VERSION "HNNBNNNYNNNNNNNNNNNNNNNNNNNNNNNNNNNNNNNNNN/4/%%%/4/'%**4NNN///"

NS_ :

BS_:

BU_: BAP_Tester FASFrontradar ICAS1_X_Gateway MFK MFK120 MIK MRR2023 NR_1 NR_2

BO_ 333 ACC_18: 32 FASFrontradar
 SG_ ACC_18_CRC : 0|8@1+ (1,0) [0|255] ""  ICAS1_X_Gateway,MFK120
 SG_ ACC_18_BZ : 8|4@1+ (1,0) [0|15] ""  ICAS1_X_Gateway,MFK120
 SG_ ACC_DynErhoehung : 14|1@1+ (1.0,0.0) [0.0|1] ""  ICAS1_X_Gateway
 SG_ ACC_Freilaufstrategie_TSK : 15|1@1+ (1.0,0.0) [0.0|1] ""  ICAS1_X_Gateway
 SG_ ACC_zul_Regelabw_unten : 16|6@1+ (0.024,0) [0.000|1.512] "Unit_MeterPerSeconSquar"  ICAS1_X_Gateway
 SG_ ACC_Sollbeschleunigung_02 : 24|11@1+ (0.005,-7.22) [-7.220|3.005] "Unit_MeterPerSeconSquar"  ICAS1_X_Gateway
 SG_ ACC_zul_Regelabw_oben : 35|5@1+ (0.0625,0) [0.0000|1.9375] "Unit_MeterPerSeconSquar"  ICAS1_X_Gateway
 SG_ ACC_neg_Sollbeschl_Grad_02 : 40|8@1+ (0.05,0) [0.00|12.75] "Unit_MeterPerCubicSecon"  ICAS1_X_Gateway
 SG_ ACC_pos_Sollbeschl_Grad_02 : 48|8@1+ (0.05,0) [0.00|12.75] "Unit_MeterPerCubicSecon"  ICAS1_X_Gateway
 SG_ ACC_Anfahren : 56|1@1+ (1.0,0.0) [0.0|1] ""  ICAS1_X_Gateway
 SG_ ACC_Anhalten : 57|1@1+ (1.0,0.0) [0.0|1] ""  ICAS1_X_Gateway
 SG_ ACC_Typ : 58|2@1+ (1.0,0.0) [0.0|3] ""  ICAS1_X_Gateway
 SG_ ACC_Status_ACC : 60|3@1+ (1.0,0.0) [0.0|7] ""  ICAS1_X_Gateway,MFK,MFK120
 SG_ ACC_Minimale_Bremsung : 63|1@1+ (1.0,0.0) [0.0|1] ""  ICAS1_X_Gateway
 SG_ ACC_Anhalteweg : 64|11@1+ (0.01,0) [0.00|20.45] "Unit_Meter"  ICAS1_X_Gateway
 SG_ ACC_Anforderung_HMS : 77|3@1+ (1.0,0.0) [0.0|7] ""  ICAS1_X_Gateway
 SG_ ACC_Freilauf_Info : 88|2@1+ (1.0,0.0) [0.0|3] ""  ICAS1_X_Gateway
 SG_ ACC_Tempolimitassistent_Ein : 90|1@1+ (1.0,0.0) [0.0|1] ""  ICAS1_X_Gateway,MFK,MFK120
 SG_ ACC_FoD_Status : 91|2@1+ (1.0,0.0) [0.0|3] ""  ICAS1_X_Gateway,MFK
 SG_ ACC_Verkehrssinn : 94|2@1+ (1.0,0.0) [0.0|3] ""  ICAS1_X_Gateway,MFK120
 SG_ ACC_TA_Kurve_Abstand : 98|6@1+ (5,0) [0|300] "Unit_Meter"  ICAS1_X_Gateway,MFK,MFK120
 SG_ ACC_TA_Kurve_vDelta : 104|4@1+ (5,0) [0|50] "Unit_KiloMeterPerHour"  ICAS1_X_Gateway,MFK,MFK120
 SG_ RDR_VBEG_Anforderung : 108|5@1+ (1,4) [5|35] "Unit_KiloMeterPerHour"  ICAS1_X_Gateway
 SG_ ACC_Abbiegewunsch : 113|2@1+ (1.0,0.0) [0.0|3] ""  ICAS1_X_Gateway,MFK,MFK120
 SG_ ACC_Abbiegewunsch_Abstand : 115|9@1+ (1,0) [0|510] "Unit_Meter"  ICAS1_X_Gateway,MFK,MFK120
 SG_ ACC_Sollbeschleunigung_AD : 124|12@1+ (0.005,-12) [-12.000|8.465] "Unit_MeterPerSeconSquar"  ICAS1_X_Gateway
 SG_ MPPmod_1_Segment : 208|6@1+ (1,0) [2|63] ""  ICAS1_X_Gateway
 SG_ MPPmod_2_Segment : 214|6@1+ (1,0) [2|63] ""  ICAS1_X_Gateway
 SG_ MPPmod_3_Segment : 220|6@1+ (1,0) [2|63] ""  ICAS1_X_Gateway
 SG_ MPPmod_4_Segment : 226|6@1+ (1,0) [2|63] ""  ICAS1_X_Gateway
 SG_ RDR_v_ueber_Grund : 236|12@1+ (0.1,0) [0.0|409.0] "Unit_KiloMeterPerHour"  ICAS1_X_Gateway
 SG_ RDR_v_ueber_Grund_Genauigkeit : 248|6@1+ (0.1,0) [0.0|6.0] "Unit_KiloMeterPerHour"  ICAS1_X_Gateway
 SG_ RDR_v_ueber_Grund_Fahrtrichtung : 254|2@1+ (1.0,0.0) [0.0|3] ""  ICAS1_X_Gateway

BO_ 768 ACC_19: 48 FASFrontradar
 SG_ ACC_FzgStatus_Kamerafusion : 54|2@1+ (1.0,0.0) [0.0|3] ""  ICAS1_X_Gateway
 SG_ ACC_FzgStatus_Anfahrbereitschaft : 56|2@1+ (1.0,0.0) [0.0|3] ""  ICAS1_X_Gateway
 SG_ ACC_FzgStatus_Fehleranzeige : 58|3@1+ (1.0,0.0) [0.0|7] ""  ICAS1_X_Gateway
 SG_ ACC_ENG_Texte_02 : 61|3@1+ (1.0,0.0) [0.0|7] ""  ICAS1_X_Gateway
 SG_ ACC_Tempolimit : 64|5@1+ (1.0,0.0) [0.0|31] ""  ICAS1_X_Gateway
 SG_ ACC_Wunschgeschw_Farbe : 69|1@1+ (1.0,0.0) [0.0|1] ""  ICAS1_X_Gateway
 SG_ ACC_Warnung_Verkehrszeichen_1 : 70|1@1+ (1.0,0.0) [0.0|1] ""  ICAS1_X_Gateway
 SG_ ACA_Querfuehrung : 71|2@1+ (1.0,0.0) [0.0|3] ""  ICAS1_X_Gateway
 SG_ ACC_Wunschgeschw_Farbe_02 : 73|2@1+ (1.0,0.0) [0.0|3] ""  ICAS1_X_Gateway
 SG_ ACC_Regelung_AIO : 75|1@1+ (1.0,0.0) [0.0|1] ""  ICAS1_X_Gateway
 SG_ ACC_Wunschgeschw_02 : 76|10@1+ (0.32,0) [0.00|327.04] "Unit_KiloMeterPerHour"  ICAS1_X_Gateway,MFK,MFK120
 SG_ ACC_Abstandsindex_02 : 86|10@1+ (1,0) [1|1021] ""  ICAS1_X_Gateway,MFK,MFK120
 SG_ ACC_Display_Prio : 96|2@1+ (1.0,0.0) [0.0|3] ""  ICAS1_X_Gateway
 SG_ ACC_rel_Objekt_Zusatzanz : 98|2@1+ (1.0,0.0) [0.0|3] ""  ICAS1_X_Gateway
 SG_ ACC_Gesetzte_Zeitluecke : 101|3@1+ (1.0,0.0) [0.0|7] ""  ICAS1_X_Gateway
 SG_ ACC_Optischer_Fahrerhinweis : 104|1@1+ (1.0,0.0) [0.0|1] ""  ICAS1_X_Gateway
 SG_ ACC_EGO_Fahrzeug : 106|3@1+ (1.0,0.0) [0.0|7] ""  ICAS1_X_Gateway
 SG_ ACC_Relevantes_Objekt_02 : 109|2@1+ (1.0,0.0) [0.0|3] ""  ICAS1_X_Gateway
 SG_ ACC_Wunschgeschw_erreicht : 112|1@1+ (1.0,0.0) [0.0|1] ""  ICAS1_X_Gateway
 SG_ ACC_Anzeige_Zeitluecke : 113|1@1+ (1.0,0.0) [0.0|1] ""  ICAS1_X_Gateway
 SG_ ACC_Texte_Primaeranz_03 : 114|6@1+ (1.0,0.0) [0.0|63] ""  ICAS1_X_Gateway
 SG_ ACC_Texte_Zusatzanz_03 : 120|6@1+ (1.0,0.0) [0.0|63] ""  ICAS1_X_Gateway
 SG_ STA_Primaeranz : 126|2@1+ (1.0,0.0) [0.0|3] ""  ICAS1_X_Gateway
 SG_ ACC_Anzeige_Objektmarkierung : 136|4@1+ (1.0,0.0) [0.0|15] ""  ICAS1_X_Gateway
 SG_ ACC_Regelgeschw : 140|10@1+ (0.32,0) [0.00|327.04] "Unit_KiloMeterPerHour"  ICAS1_X_Gateway
 SG_ ACC_Einheit_maxSetzgeschw : 150|1@1+ (1.0,0.0) [0.0|1] ""  ICAS1_X_Gateway
 SG_ ACC_maxSetzgeschw : 151|9@1+ (1,0) [0|510] ""  ICAS1_X_Gateway
 SG_ ACC_Tempolimit_Einheit : 179|1@1+ (1.0,0.0) [0.0|1] ""  ICAS1_X_Gateway
 SG_ ACC_RUV : 184|2@1+ (1.0,0.0) [0.0|3] ""  ICAS1_X_Gateway
 SG_ ACC_Tachokranz : 186|1@1+ (1.0,0.0) [0.0|1] ""  ICAS1_X_Gateway
 SG_ ACC_Typ_Tachokranz_unten : 187|1@1+ (1.0,0.0) [0.0|1] ""  ICAS1_X_Gateway
 SG_ ACC_ENG_Texte : 188|2@1+ (1.0,0.0) [0.0|3] ""  ICAS1_X_Gateway,MFK,MFK120
 SG_ ACC_Status_GRA_Modus : 190|2@1+ (1.0,0.0) [0.0|3] ""  ICAS1_X_Gateway,MFK,MFK120
 SG_ ACA_Querfuehrung_Texte : 192|3@1+ (1.0,0.0) [0.0|7] ""  ICAS1_X_Gateway
 SG_ ACA_Hinweistexte : 195|3@1+ (1.0,0.0) [0.0|7] ""  ICAS1_X_Gateway
 SG_ ACC_FoD_Status : 198|2@1+ (1.0,0.0) [0.0|3] ""  ICAS1_X_Gateway
 SG_ ACC_Status_Anzeige : 208|3@1+ (1.0,0.0) [0.0|7] ""  ICAS1_X_Gateway
 SG_ ACC_Akustik_03 : 211|3@1+ (1.0,0.0) [0.0|7] ""  ICAS1_X_Gateway
 SG_ ACC_Texte_02 : 224|6@1+ (1.0,0.0) [0.0|63] ""  ICAS1_X_Gateway
 SG_ ACC_Status_Stauende : 231|1@1+ (1.0,0.0) [0.0|1] ""  ICAS1_X_Gateway
 SG_ STA_Texte : 232|3@1+ (1.0,0.0) [0.0|7] ""  ICAS1_X_Gateway
 SG_ AbstWarn_LRR_FAS_Fkt_Status : 235|2@1+ (1.0,0.0) [0.0|3] ""  ICAS1_X_Gateway
 SG_ STA_Zusatzanz : 237|2@1+ (1.0,0.0) [0.0|3] ""  ICAS1_X_Gateway
 SG_ FAS_Licht_Anf : 239|1@1+ (1.0,0.0) [0.0|1] ""  ICAS1_X_Gateway
 SG_ ACC_Texte_Sekundaeranz_03 : 256|5@1+ (1.0,0.0) [0.0|31] ""  ICAS1_X_Gateway
 SG_ ACC_Modus_Pop_Up : 262|3@1+ (1.0,0.0) [0.0|7] ""  ICAS1_X_Gateway
 SG_ ACC_Statusicon : 265|4@1+ (1.0,0.0) [0.0|15] ""  ICAS1_X_Gateway
 SG_ ACC_Anzeige_Objektregelung : 269|5@1+ (1.0,0.0) [0.0|31] ""  ICAS1_X_Gateway
 SG_ ACC_Anzeige_Maximalabstand : 274|7@1+ (2,0) [0|254] "Unit_Meter"  ICAS1_X_Gateway
 SG_ ACC_Typ_LNS : 281|3@1+ (1.0,0.0) [0.0|7] ""  ICAS1_X_Gateway
 SG_ ACC_Typ_RNS : 284|3@1+ (1.0,0.0) [0.0|7] ""  ICAS1_X_Gateway
 SG_ ACC_Typ_WZO : 287|3@1+ (1.0,0.0) [0.0|7] ""  ICAS1_X_Gateway
 SG_ ACC_Abstand_WZO : 290|10@1+ (0.2,0) [0.2|204.6] "Unit_Meter"  ICAS1_X_Gateway
 SG_ ACC_Abstand_RNS : 300|10@1+ (0.2,0) [0.2|204.6] "Unit_Meter"  ICAS1_X_Gateway
 SG_ ACC_Abstand_LNS : 310|10@1+ (0.2,0) [0.2|204.6] "Unit_Meter"  ICAS1_X_Gateway
 SG_ ACC_Texte_03 : 320|7@1+ (1.0,0.0) [0.0|127] ""  ICAS1_X_Gateway,MFK120
 SG_ ACC_iBoost_Anzeige : 327|2@1+ (1.0,0.0) [0.0|3] ""  ICAS1_X_Gateway
 SG_ ACC_Texte_Sekundaeranz_02 : 329|5@1+ (1.0,0.0) [0.0|31] ""  ICAS1_X_Gateway
 SG_ ACC_Sollabstand_1 : 334|10@1+ (0.2,0) [0.2|204.6] "Unit_Meter"  ICAS1_X_Gateway
 SG_ ACC_Sollabstand_2 : 344|10@1+ (0.2,0) [0.2|204.6] "Unit_Meter"  ICAS1_X_Gateway
 SG_ ACC_Sollabstand_3 : 354|10@1+ (0.2,0) [0.2|204.6] "Unit_Meter"  ICAS1_X_Gateway
 SG_ ACC_Sollabstand_4 : 364|10@1+ (0.2,0) [0.2|204.6] "Unit_Meter"  ICAS1_X_Gateway
 SG_ ACC_Sollabstand_5 : 374|10@1+ (0.2,0) [0.2|204.6] "Unit_Meter"  ICAS1_X_Gateway

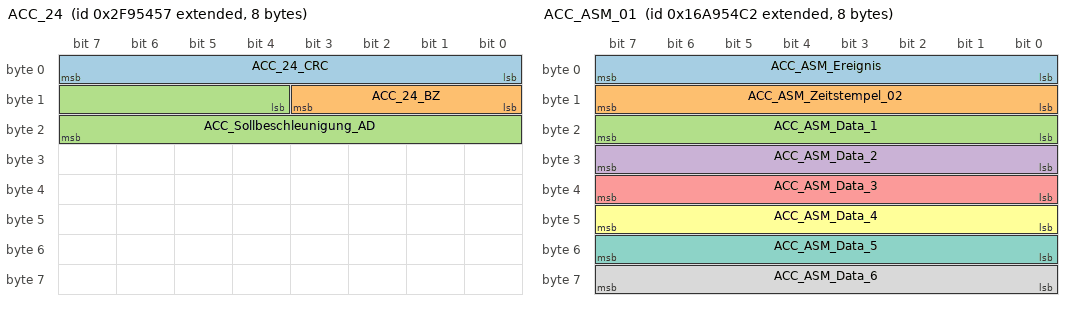
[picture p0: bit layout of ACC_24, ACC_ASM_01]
BO_ 2197378135 ACC_24: 8 Vector__XXX
 SG_ ACC_24_CRC : 0|8@1+ (1,0) [0|255] ""  ICAS1_X_Gateway
 SG_ ACC_24_BZ : 8|4@1+ (1,0) [0|15] ""  ICAS1_X_Gateway
 SG_ ACC_Sollbeschleunigung_AD : 12|12@1+ (0.005,-12) [-12.000|8.465] "Unit_MeterPerSeconSquar"  ICAS1_X_Gateway

BO_ 2527679682 ACC_ASM_01: 8 FASFrontradar
 SG_ ACC_ASM_Ereignis : 0|8@1+ (1,0) [1|254] ""  ICAS1_X_Gateway
 SG_ ACC_ASM_Zeitstempel_02 : 8|8@1+ (0.04,0) [0.00|10.16] "Unit_Secon"  ICAS1_X_Gateway
 SG_ ACC_ASM_Data_1 : 16|8@1+ (1,0) [0|255] ""  ICAS1_X_Gateway
 SG_ ACC_ASM_Data_2 : 24|8@1+ (1,0) [0|255] ""  ICAS1_X_Gateway
 SG_ ACC_ASM_Data_3 : 32|8@1+ (1,0) [0|255] ""  ICAS1_X_Gateway
 SG_ ACC_ASM_Data_4 : 40|8@1+ (1,0) [0|255] ""  ICAS1_X_Gateway
 SG_ ACC_ASM_Data_5 : 48|8@1+ (1,0) [0|255] ""  ICAS1_X_Gateway
 SG_ ACC_ASM_Data_6 : 56|8@1+ (1,0) [0|255] ""  ICAS1_X_Gateway

BO_ 64 Airbag_01: 8 ICAS1_X_Gateway
 SG_ Airbag_01_CRC : 0|8@1+ (1,0) [0|255] ""  FASFrontradar,MFK120,MRR2023
 SG_ Airbag_01_BZ : 8|4@1+ (1,0) [0|15] ""  FASFrontradar,MFK120,MRR2023
 SG_ AB_RGS_Anst : 12|4@1+ (1.0,0.0) [0.0|15] ""  Vector__XXX
 SG_ AB_Front_Crash : 16|1@1+ (1.0,0.0) [0.0|1] ""  MFK,MFK120
 SG_ AB_Heck_Crash : 17|1@1+ (1.0,0.0) [0.0|1] ""  MFK,MFK120
 SG_ AB_SF_Crash : 18|1@1+ (1.0,0.0) [0.0|1] ""  MFK,MFK120
 SG_ AB_SB_Crash : 19|1@1+ (1.0,0.0) [0.0|1] ""  MFK,MFK120
 SG_ AB_Rollover_Crash : 20|1@1+ (1.0,0.0) [0.0|1] ""  MFK,MFK120
 SG_ AB_Crash_Int : 21|3@1+ (1.0,0.0) [0.0|7] ""  FASFrontradar,MFK120,MRR2023
 SG_ AB_Lampe : 24|1@1+ (1.0,0.0) [0.0|1] ""  Vector__XXX
 SG_ AB_Deaktiviert : 25|1@1+ (1.0,0.0) [0.0|1] ""  Vector__XXX
 SG_ AB_VB_deaktiviert : 26|1@1+ (1.0,0.0) [0.0|1] ""  Vector__XXX
 SG_ AB_Systemfehler : 27|1@1+ (1.0,0.0) [0.0|1] ""  MFK,MFK120
 SG_ AB_Diagnose : 28|1@1+ (1.0,0.0) [0.0|1] ""  Vector__XXX
 SG_ AB_Stellgliedtest : 29|1@1+ (1.0,0.0) [0.0|1] ""  Vector__XXX
 SG_ AB_Erh_Auf_VB : 30|2@1+ (1.0,0.0) [0.0|3] ""  Vector__XXX
 SG_ AB_Gurtwarn_VF : 32|1@1+ (1.0,0.0) [0.0|1] ""  MFK
 SG_ AB_Gurtwarn_VB : 33|1@1+ (1.0,0.0) [0.0|1] ""  MFK
 SG_ AB_Anzeige_Fussg : 34|2@1+ (1.0,0.0) [0.0|3] ""  Vector__XXX
 SG_ AB_Texte_AKS : 36|2@1+ (1.0,0.0) [0.0|3] ""  Vector__XXX
 SG_ AB_PAO_Leuchte_Anf : 38|1@1+ (1.0,0.0) [0.0|1] ""  Vector__XXX
 SG_ AB_MKB_gueltig : 39|1@1+ (1.0,0.0) [0.0|1] ""  Vector__XXX
 SG_ AB_MKB_Anforderung : 40|1@1+ (1.0,0.0) [0.0|1] ""  Vector__XXX
 SG_ AB_Versorgungsspannung : 41|1@1+ (1.0,0.0) [0.0|1] ""  Vector__XXX
 SG_ AB_Deaktivierung_HV : 42|3@1+ (1.0,0.0) [0.0|7] ""  Vector__XXX
 SG_ AB_EDR_Trigger : 45|2@1+ (1.0,0.0) [0.0|3] ""  MFK120
 SG_ AB_Belegung_VF : 47|2@1+ (1.0,0.0) [0.0|3] ""  FASFrontradar,MRR2023
 SG_ AB_Gurtschloss_FA_ext : 49|3@1+ (1.0,0.0) [0.0|7] ""  MRR2023
 SG_ AB_Gurtschloss_FA_ext_aktiv : 52|1@1+ (1.0,0.0) [0.0|1] ""  MRR2023
 SG_ AB_eCS_Error : 53|1@1+ (1.0,0.0) [0.0|1] ""  Vector__XXX
 SG_ ASM_Masterzeit_02 : 56|8@1+ (0.04,0) [0.00|10.16] "Unit_Secon"  FASFrontradar,MFK,MFK120,MRR2023

BO_ 1312 Airbag_02: 8 ICAS1_X_Gateway
 SG_ Airbag_02_CRC : 0|8@1+ (1,0) [0|255] ""  FASFrontradar,MRR2023
 SG_ Airbag_02_BZ : 8|4@1+ (1,0) [0|15] ""  FASFrontradar,MRR2023
 SG_ LoGeWa_Event_Kombiwarnung : 12|4@1+ (1.0,0.0) [0.0|15] ""  Vector__XXX
 SG_ AB_Anforderung_eCall : 16|1@1+ (1.0,0.0) [0.0|1] ""  Vector__XXX
 SG_ AB_Anprall_Seite_Beifahrer : 17|1@1+ (1.0,0.0) [0.0|1] ""  MRR2023
 SG_ AB_Anprall_FGS : 19|1@1+ (1.0,0.0) [0.0|1] ""  MRR2023
 SG_ AB_Anprall_Front_Beifahrer : 20|1@1+ (1.0,0.0) [0.0|1] ""  MRR2023
 SG_ AB_Anprall_Front_Fahrer : 21|1@1+ (1.0,0.0) [0.0|1] ""  MRR2023
 SG_ AB_Wickelklappung_Reihe2_MI : 24|2@1+ (1.0,0.0) [0.0|3] ""  Vector__XXX
 SG_ AB_Belegung_VB : 26|2@1+ (1.0,0.0) [0.0|3] ""  Vector__XXX
 SG_ AB_Abschaltanf_SIH_BF : 28|1@1+ (1.0,0.0) [0.0|1] ""  Vector__XXX
 SG_ AB_Anprall_Seite_Fahrer : 29|1@1+ (1.0,0.0) [0.0|1] ""  MRR2023
 SG_ SC_PAO_Schriftzug_Anf : 30|2@1+ (1.0,0.0) [0.0|3] ""  Vector__XXX
 SG_ SC_PAO_ON_Anf : 32|2@1+ (1.0,0.0) [0.0|3] ""  Vector__XXX
 SG_ SC_PAO_OFF_Anf : 34|2@1+ (1.0,0.0) [0.0|3] ""  Vector__XXX
 SG_ AB_Crashschwere : 36|3@1+ (1.0,0.0) [0.0|7] ""  Vector__XXX
 SG_ AB_Anforderung_USM : 39|1@1+ (1.0,0.0) [0.0|1] ""  Vector__XXX
 SG_ AB_Gurtschloss_FA : 40|2@1+ (1.0,0.0) [0.0|3] ""  MFK,MFK120,MRR2023
 SG_ AB_Gurtschloss_BF : 42|2@1+ (1.0,0.0) [0.0|3] ""  MFK,MFK120
 SG_ AB_Gurtschloss_Reihe2_FA : 44|2@1+ (1.0,0.0) [0.0|3] ""  MFK,MFK120
 SG_ AB_Gurtschloss_Reihe2_MI : 46|2@1+ (1.0,0.0) [0.0|3] ""  MFK,MFK120
 SG_ AB_Gurtschloss_Reihe2_BF : 48|2@1+ (1.0,0.0) [0.0|3] ""  MFK,MFK120
 SG_ AB_Gurtschloss_Reihe3_FA : 50|2@1+ (1.0,0.0) [0.0|3] ""  MFK,MFK120
 SG_ AB_Gurtschloss_Reihe3_MI : 52|2@1+ (1.0,0.0) [0.0|3] ""  MFK,MFK120
 SG_ AB_Gurtschloss_Reihe3_BF : 54|2@1+ (1.0,0.0) [0.0|3] ""  MFK,MFK120
 SG_ AB_Sitzpos_Sens_FA : 56|2@1+ (1.0,0.0) [0.0|3] ""  Vector__XXX
 SG_ AB_Sitzpos_Sens_BF : 58|2@1+ (1.0,0.0) [0.0|3] ""  Vector__XXX
 SG_ AB_Wickelklappung_Reihe2_BF : 60|2@1+ (1.0,0.0) [0.0|3] ""  Vector__XXX
 SG_ AB_Wickelklappung_Reihe2_FA : 62|2@1+ (1.0,0.0) [0.0|3] ""  Vector__XXX

BO_ 1349 Airbag_04: 8 ICAS1_X_Gateway
 SG_ Airbag_04_CRC : 0|8@1+ (1,0) [0|255] ""  FASFrontradar,MRR2023
 SG_ Airbag_04_BZ : 8|4@1+ (1,0) [0|15] ""  FASFrontradar,MRR2023
 SG_ AB_Anprall_Heck : 13|1@1+ (1.0,0.0) [0.0|1] ""  Vector__XXX
 SG_ AB_Gurtwarn_Reihe4_FA : 14|2@1+ (1.0,0.0) [0.0|3] ""  Vector__XXX
 SG_ AB_Gurtwarn_Reihe4_BF : 16|2@1+ (1.0,0.0) [0.0|3] ""  Vector__XXX
 SG_ AB_Gurtwarn_Reihe4_MI : 18|2@1+ (1.0,0.0) [0.0|3] ""  Vector__XXX
 SG_ AB_Gurtwarn_Reihe2_FA : 20|2@1+ (1.0,0.0) [0.0|3] ""  MFK
 SG_ AB_Gurtwarn_Reihe2_BF : 22|2@1+ (1.0,0.0) [0.0|3] ""  MFK
 SG_ AbstWarn_MV_FAS_Fkt_Status : 24|2@1+ (1.0,0.0) [0.0|3] ""  Vector__XXX
 SG_ WarnBrems_Charisma_Status : 26|2@1+ (1.0,0.0) [0.0|3] ""  Vector__XXX
 SG_ WarnBrems_Charisma_FahrPr : 28|4@1+ (1.0,0.0) [0.0|15] ""  Vector__XXX
 SG_ AB_Gurtwarn_Reihe2_MI : 32|2@1+ (1.0,0.0) [0.0|3] ""  MFK
 SG_ AB_Gurtwarn_Reihe3_FA : 34|2@1+ (1.0,0.0) [0.0|3] ""  MFK
 SG_ AB_Gurtwarn_Reihe3_MI : 36|2@1+ (1.0,0.0) [0.0|3] ""  MFK
 SG_ AB_Gurtwarn_Reihe3_BF : 38|2@1+ (1.0,0.0) [0.0|3] ""  MFK
 SG_ LGI_FAS_Fkt_Status : 40|2@1+ (1.0,0.0) [0.0|3] ""  Vector__XXX
 SG_ PreCrash_FAS_Fkt_Status : 42|3@1+ (1.0,0.0) [0.0|7] ""  Vector__XXX
 SG_ AB_Belegung_VF_ext : 45|3@1+ (1.0,0.0) [0.0|7] ""  MIK,MRR2023
 SG_ AB_SBR_hinten_verbau : 48|2@1+ (1.0,0.0) [0.0|3] ""  Vector__XXX
 SG_ AB_Belegung_VF_ext_aktiv : 50|1@1+ (1.0,0.0) [0.0|1] ""  Vector__XXX
 SG_ AWV_Einstellung_System_ASG : 51|1@1+ (1.0,0.0) [0.0|1] ""  Vector__XXX
 SG_ AWV_Einstellung_Warnung_ASG : 52|3@1+ (1.0,0.0) [0.0|7] ""  Vector__XXX
 SG_ SC_PreSense_Modus_Warnung_NV : 55|3@1+ (1.0,0.0) [0.0|7] ""  Vector__XXX
 SG_ SC_PreSense_Modus_Warnung_MV : 58|3@1+ (1.0,0.0) [0.0|7] ""  Vector__XXX
 SG_ SC_PreSense_Modus_System_MV : 61|1@1+ (1.0,0.0) [0.0|1] ""  Vector__XXX
 SG_ SC_PreSense_Modus_System_NV : 62|1@1+ (1.0,0.0) [0.0|1] ""  Vector__XXX
 SG_ SC_PreSense_Modus_System_KAS : 63|1@1+ (1.0,0.0) [0.0|1] ""  Vector__XXX

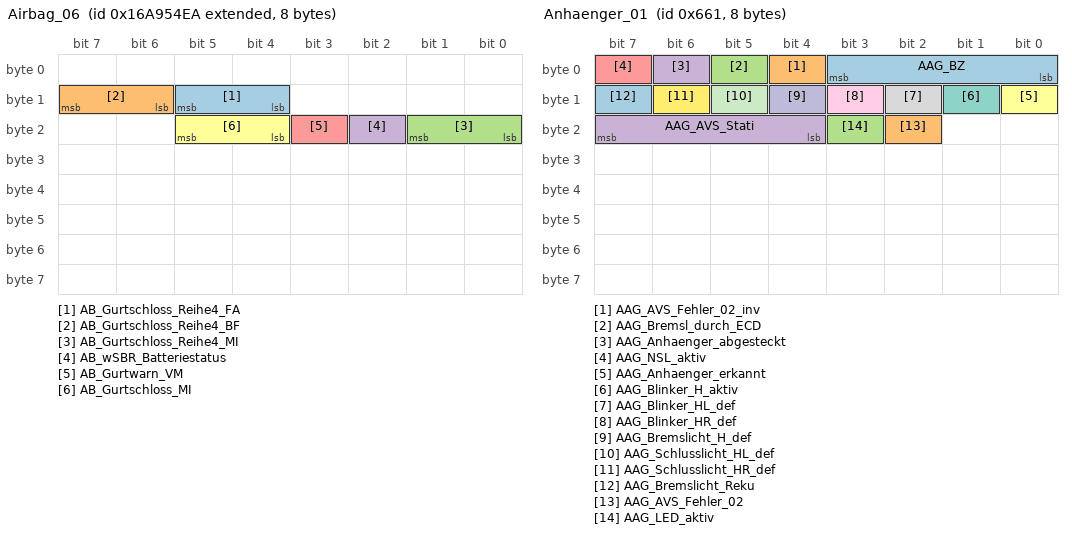
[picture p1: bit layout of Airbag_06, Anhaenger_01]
BO_ 2527679722 Airbag_06: 8 ICAS1_X_Gateway
 SG_ AB_Gurtschloss_Reihe4_FA : 12|2@1+ (1.0,0.0) [0.0|3] ""  Vector__XXX
 SG_ AB_Gurtschloss_Reihe4_BF : 14|2@1+ (1.0,0.0) [0.0|3] ""  Vector__XXX
 SG_ AB_Gurtschloss_Reihe4_MI : 16|2@1+ (1.0,0.0) [0.0|3] ""  Vector__XXX
 SG_ AB_wSBR_Batteriestatus : 18|1@1+ (1.0,0.0) [0.0|1] ""  Vector__XXX
 SG_ AB_Gurtwarn_VM : 19|1@1+ (1.0,0.0) [0.0|1] ""  MFK
 SG_ AB_Gurtschloss_MI : 20|2@1+ (1.0,0.0) [0.0|3] ""  Vector__XXX

BO_ 1633 Anhaenger_01: 8 ICAS1_X_Gateway
 SG_ AAG_BZ : 0|4@1+ (1,0) [0|15] ""  Vector__XXX
 SG_ AAG_AVS_Fehler_02_inv : 4|1@1+ (1.0,0.0) [0.0|1] ""  Vector__XXX
 SG_ AAG_Bremsl_durch_ECD : 5|1@1+ (1.0,0.0) [0.0|1] ""  Vector__XXX
 SG_ AAG_Anhaenger_abgesteckt : 6|1@1+ (1.0,0.0) [0.0|1] ""  Vector__XXX
 SG_ AAG_NSL_aktiv : 7|1@1+ (1.0,0.0) [0.0|1] ""  Vector__XXX
 SG_ AAG_Anhaenger_erkannt : 8|1@1+ (1.0,0.0) [0.0|1] ""  MFK,MFK120,MRR2023
 SG_ AAG_Blinker_H_aktiv : 9|1@1+ (1.0,0.0) [0.0|1] ""  Vector__XXX
 SG_ AAG_Blinker_HL_def : 10|1@1+ (1.0,0.0) [0.0|1] ""  Vector__XXX
 SG_ AAG_Blinker_HR_def : 11|1@1+ (1.0,0.0) [0.0|1] ""  Vector__XXX
 SG_ AAG_Bremslicht_H_def : 12|1@1+ (1.0,0.0) [0.0|1] ""  MRR2023
 SG_ AAG_Schlusslicht_HL_def : 13|1@1+ (1.0,0.0) [0.0|1] ""  Vector__XXX
 SG_ AAG_Schlusslicht_HR_def : 14|1@1+ (1.0,0.0) [0.0|1] ""  Vector__XXX
 SG_ AAG_Bremslicht_Reku : 15|1@1+ (1.0,0.0) [0.0|1] ""  Vector__XXX
 SG_ AAG_AVS_Fehler_02 : 18|1@1+ (1.0,0.0) [0.0|1] ""  Vector__XXX
 SG_ AAG_LED_aktiv : 19|1@1+ (1.0,0.0) [0.0|1] ""  Vector__XXX
 SG_ AAG_AVS_Stati : 20|4@1+ (1.0,0.0) [0.0|15] ""  Vector__XXX

BO_ 616 APS_04: 32 ICAS1_X_Gateway
 SG_ US_Fehler_HLS : 12|1@1+ (1.0,0.0) [0.0|1] ""  MFK
 SG_ US_Fehler_HRS : 13|1@1+ (1.0,0.0) [0.0|1] ""  MFK
 SG_ US_Fehler_VLS : 14|1@1+ (1.0,0.0) [0.0|1] ""  MFK
 SG_ US_Fehler_VRS : 15|1@1+ (1.0,0.0) [0.0|1] ""  MFK
 SG_ US_Links_01_Pos_X : 16|10@1+ (0.016,-8.176) [-8.176|8.176] "Unit_Meter"  MFK
 SG_ US_Links_01_Pos_Y : 26|9@1+ (0.016,0) [0.000|8.160] "Unit_Meter"  MFK
 SG_ US_Links_01_Valid : 35|1@1+ (1.0,0.0) [0.0|1] ""  MFK
 SG_ US_Links_02_Pos_X : 36|10@1+ (0.016,-8.176) [-8.176|8.176] "Unit_Meter"  MFK
 SG_ US_Links_02_Pos_Y : 46|9@1+ (0.016,0) [0.000|8.160] "Unit_Meter"  MFK
 SG_ US_Links_02_Valid : 55|1@1+ (1.0,0.0) [0.0|1] ""  MFK
 SG_ US_Rechts_01_Pos_X : 56|10@1+ (0.016,-8.176) [-8.176|8.176] "Unit_Meter"  MFK
 SG_ US_Rechts_01_Pos_Y : 66|9@1+ (0.016,-8.16) [-8.160|0.000] "Unit_Meter"  MFK
 SG_ US_Rechts_01_Valid : 75|1@1+ (1.0,0.0) [0.0|1] ""  MFK
 SG_ US_Rechts_02_Pos_X : 76|10@1+ (0.016,-8.176) [-8.176|8.176] "Unit_Meter"  MFK
 SG_ US_Rechts_02_Pos_Y : 86|9@1+ (0.016,-8.16) [-8.160|0.000] "Unit_Meter"  MFK
 SG_ US_Rechts_02_Valid : 95|1@1+ (1.0,0.0) [0.0|1] ""  MFK
 SG_ US_QAbstand_HLS : 96|9@1+ (0.016,0) [0.000|8.160] "Unit_Meter"  MFK,MFK120
 SG_ US_Nichtverfuegbarkeit_HLS : 105|1@1+ (1.0,0.0) [0.0|1] ""  MFK
 SG_ US_QAbstand_HRS : 106|9@1+ (0.016,0) [0.000|8.160] "Unit_Meter"  MFK,MFK120
 SG_ US_Nichtverfuegbarkeit_HRS : 115|1@1+ (1.0,0.0) [0.0|1] ""  MFK
 SG_ US_QAbstand_VLS : 116|9@1+ (0.016,0) [0.000|8.160] "Unit_Meter"  MFK,MFK120
 SG_ US_Nichtverfuegbarkeit_VLS : 125|1@1+ (1.0,0.0) [0.0|1] ""  MFK
 SG_ US_QAbstand_VRS : 126|9@1+ (0.016,0) [0.000|8.160] "Unit_Meter"  MFK,MFK120
 SG_ US_Nichtverfuegbarkeit_VRS : 135|1@1+ (1.0,0.0) [0.0|1] ""  MFK
 SG_ US_Datenalter_HLS : 192|16@1+ (0.1,0) [0.0|6553.5] "Unit_MilliSecon"  MFK
 SG_ US_Datenalter_HRS : 208|16@1+ (0.1,0) [0.0|6553.5] "Unit_MilliSecon"  MFK
 SG_ US_Datenalter_VLS : 224|16@1+ (0.1,0) [0.0|6553.5] "Unit_MilliSecon"  MFK
 SG_ US_Datenalter_VRS : 240|16@1+ (0.1,0) [0.0|6553.5] "Unit_MilliSecon"  MFK

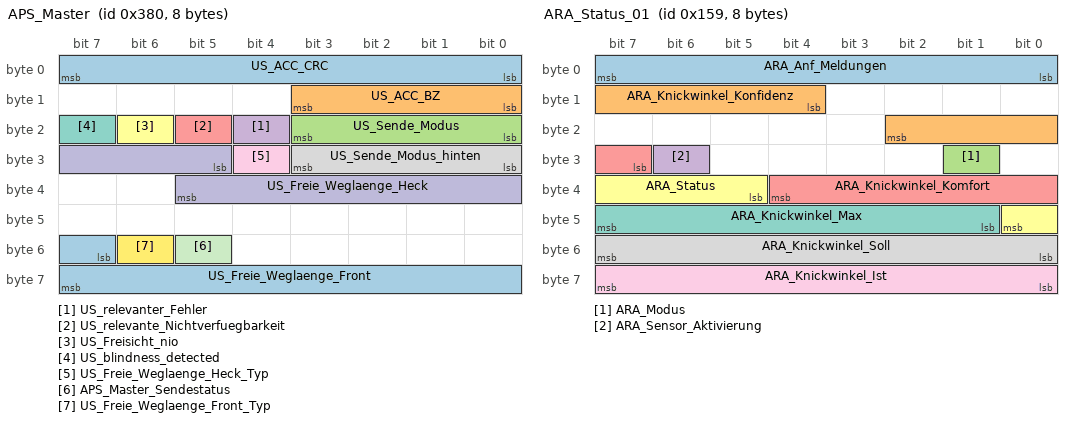
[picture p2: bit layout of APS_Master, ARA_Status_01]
BO_ 896 APS_Master: 8 ICAS1_X_Gateway
 SG_ US_ACC_CRC : 0|8@1+ (1,0) [0|255] ""  Vector__XXX
 SG_ US_ACC_BZ : 8|4@1+ (1,0) [0|15] ""  Vector__XXX
 SG_ US_Sende_Modus : 16|4@1+ (1.0,0.0) [0.0|15] ""  FASFrontradar,MRR2023
 SG_ US_relevanter_Fehler : 20|1@1+ (1.0,0.0) [0.0|1] ""  FASFrontradar,MRR2023
 SG_ US_relevante_Nichtverfuegbarkeit : 21|1@1+ (1.0,0.0) [0.0|1] ""  FASFrontradar,MRR2023
 SG_ US_Freisicht_nio : 22|1@1+ (1.0,0.0) [0.0|1] ""  FASFrontradar,MRR2023
 SG_ US_blindness_detected : 23|1@1+ (1.0,0.0) [0.0|1] ""  FASFrontradar,MRR2023
 SG_ US_Sende_Modus_hinten : 24|4@1+ (1.0,0.0) [0.0|15] ""  Vector__XXX
 SG_ US_Freie_Weglaenge_Heck_Typ : 28|1@1+ (1.0,0.0) [0.0|1] ""  Vector__XXX
 SG_ US_Freie_Weglaenge_Heck : 29|9@1+ (0.01,0) [0.00|5.00] "Unit_Meter"  Vector__XXX
 SG_ APS_Master_Sendestatus : 53|1@1+ (1.0,0.0) [0.0|1] ""  Vector__XXX
 SG_ US_Freie_Weglaenge_Front_Typ : 54|1@1+ (1.0,0.0) [0.0|1] ""  FASFrontradar,MRR2023
 SG_ US_Freie_Weglaenge_Front : 55|9@1+ (0.01,0) [0.00|5.00] "Unit_Meter"  FASFrontradar,MRR2023

BO_ 345 ARA_Status_01: 8 ICAS1_X_Gateway
 SG_ ARA_Anf_Meldungen : 0|8@1+ (1.0,0.0) [0.0|255] ""  Vector__XXX
 SG_ ARA_Knickwinkel_Konfidenz : 12|7@1+ (1,0) [0|120] "Unit_DegreOfArc"  Vector__XXX
 SG_ ARA_Modus : 25|1@1+ (1.0,0.0) [0.0|1] ""  Vector__XXX
 SG_ ARA_Sensor_Aktivierung : 30|1@1+ (1.0,0.0) [0.0|1] ""  Vector__XXX
 SG_ ARA_Knickwinkel_Komfort : 31|6@1+ (1,0) [0|60] "Unit_DegreOfArc"  Vector__XXX
 SG_ ARA_Status : 37|4@1+ (1.0,0.0) [0.0|15] ""  MRR2023
 SG_ ARA_Knickwinkel_Max : 41|7@1+ (1,0) [0|120] "Unit_DegreOfArc"  Vector__XXX
 SG_ ARA_Knickwinkel_Soll : 48|8@1+ (1,-125) [-125|126] "Unit_DegreOfArc"  Vector__XXX
 SG_ ARA_Knickwinkel_Ist : 56|8@1+ (1,-125) [-125|126] "Unit_DegreOfArc"  Vector__XXX

BO_ 2527679661 AWV_02: 8 FASFrontradar
 SG_ WBA_Warnblinken : 0|2@1+ (1.0,0.0) [0.0|3] ""  ICAS1_X_Gateway,MFK120
 SG_ AWV_KA_Konfiguration : 2|1@1+ (1.0,0.0) [0.0|1] ""  ICAS1_X_Gateway
 SG_ AWV_Warnung : 12|3@1+ (1.0,0.0) [0.0|7] ""  ICAS1_X_Gateway,MFK,MFK120
 SG_ AWV_Texte : 15|3@1+ (1.0,0.0) [0.0|7] ""  ICAS1_X_Gateway
 SG_ AWV_Warnlevel : 18|6@1+ (1.0,0.0) [0.0|63] ""  ICAS1_X_Gateway,MFK
 SG_ AWV_Einstellung_System_FSG : 24|1@1+ (1.0,0.0) [0.0|1] ""  ICAS1_X_Gateway
 SG_ AWV_Einstellung_Warnung_FSG : 25|3@1+ (1.0,0.0) [0.0|7] ""  ICAS1_X_Gateway
 SG_ AWV_Status_Anzeige : 28|2@1+ (1.0,0.0) [0.0|3] ""  ICAS1_X_Gateway
 SG_ AWV_LED_Leiste : 30|2@1+ (1.0,0.0) [0.0|3] ""  ICAS1_X_Gateway
 SG_ AWV_Priowarnung : 32|1@1+ (1.0,0.0) [0.0|1] ""  ICAS1_X_Gateway
 SG_ AWV_AW_Abstand : 33|9@1+ (1,0) [0|508] "Unit_Meter"  ICAS1_X_Gateway
 SG_ AWV_AW_Zeitluecke : 42|3@1+ (1.0,0.0) [0.0|7] ""  ICAS1_X_Gateway
 SG_ AWV_AW_Texte : 45|3@1+ (1.0,0.0) [0.0|7] ""  ICAS1_X_Gateway
 SG_ AWV_AW_Texte_Zusatzanzeige : 48|4@1+ (1.0,0.0) [0.0|15] ""  ICAS1_X_Gateway
 SG_ AWV_KA_ObjektFront : 52|1@1+ (1.0,0.0) [0.0|1] ""  ICAS1_X_Gateway
 SG_ AWV_Warnung_Richtung : 53|3@1+ (1.0,0.0) [0.0|7] ""  ICAS1_X_Gateway
 SG_ AWV_Kamera_Objekt_ID : 56|8@1+ (1,0) [1|255] "Unit_None"  ICAS1_X_Gateway

BO_ 219 AWV_03: 48 FASFrontradar
 SG_ AWV_03_CRC : 0|8@1+ (1,0) [0|255] ""  ICAS1_X_Gateway
 SG_ AWV_03_BZ : 8|4@1+ (1,0) [0|15] ""  ICAS1_X_Gateway
 SG_ PCF_Freigabe : 12|1@1+ (1.0,0.0) [0.0|1] ""  ICAS1_X_Gateway
 SG_ SDF_PSF_Objektstatus : 13|3@1+ (1.0,0.0) [0.0|7] ""  ICAS1_X_Gateway
 SG_ SDF_PSF_CU_Status : 16|1@1+ (1.0,0.0) [0.0|1] ""  ICAS1_X_Gateway
 SG_ SDF_PSF_CW : 17|7@1+ (1,0) [0|100] ""  ICAS1_X_Gateway
 SG_ SDF_PSF_Fahrer_aktiv : 24|1@1+ (1.0,0.0) [0.0|1] ""  ICAS1_X_Gateway
 SG_ SDF_PSF_Guete : 25|2@1+ (1.0,0.0) [0.0|3] ""  ICAS1_X_Gateway
 SG_ SDF_PSF_Kollisionsueberdeckung : 27|5@1+ (0.1,0) [0.1|2.8] "Unit_Meter"  ICAS1_X_Gateway
 SG_ SDF_PSF_Time_To_Collision : 32|8@1+ (0.01,0) [0.00|2.50] "Unit_Secon"  ICAS1_X_Gateway
 SG_ SDF_PSF_v_rel : 40|8@1+ (0.4,0) [0.4|101.2] "Unit_MeterPerSecon"  ICAS1_X_Gateway
 SG_ AWV_Eingriff_Sendeart : 64|1@1+ (1.0,0.0) [0.0|1] ""  ICAS1_X_Gateway
 SG_ AWV_Verz_Freigabe : 65|1@1+ (1.0,0.0) [0.0|1] ""  ICAS1_X_Gateway
 SG_ AWV_Verz_Anf : 66|10@1+ (0.024,-20.016) [-20.016|4.512] "Unit_MeterPerSeconSquar"  ICAS1_X_Gateway
 SG_ AWV_Anf_Prefill : 76|1@1+ (1.0,0.0) [0.0|1] ""  ICAS1_X_Gateway
 SG_ AWV_Ruckprofil : 77|3@1+ (1.0,0.0) [0.0|7] ""  ICAS1_X_Gateway
 SG_ AWV_Time_to_collision : 80|8@1+ (0.01,0) [0.00|2.50] "Unit_Secon"  ICAS1_X_Gateway
 SG_ AWV_HBA_Param : 88|2@1+ (1.0,0.0) [0.0|3] ""  ICAS1_X_Gateway
 SG_ AWV_Verz_Anf_ASIL : 90|3@1+ (1.0,0.0) [0.0|7] ""  ICAS1_X_Gateway
 SG_ AWV_Time_to_brake : 93|7@1+ (10,0) [0|1240] "Unit_MilliSecon"  ICAS1_X_Gateway
 SG_ AWV_Zielobjekttyp : 100|4@1+ (1.0,0.0) [0.0|15] ""  ICAS1_X_Gateway
 SG_ AWV_QFK_KruemmSoll : 104|15@1+ (0.0000067,0) [0E-7|0.2195389] "Unit_MeterInver"  ICAS1_X_Gateway
 SG_ AWV_QFK_KruemmSoll_VZ : 119|1@1+ (1.0,0.0) [0.0|1] ""  ICAS1_X_Gateway
 SG_ AWV_QFK_Spuerb : 120|8@1+ (0.4,0) [0.0|100.0] "Unit_PerCent"  ICAS1_X_Gateway
 SG_ AWV_QFK_AnfStat : 128|4@1+ (1.0,0.0) [0.0|15] ""  ICAS1_X_Gateway
 SG_ AWV_QFK_Signal1 : 132|10@1+ (1,0) [0|1023] ""  ICAS1_X_Gateway
 SG_ AWV_QFK_Art1 : 142|3@1+ (1,0) [0|7] ""  ICAS1_X_Gateway
 SG_ AWV_QFK_Art2 : 145|3@1+ (1,0) [0|7] ""  ICAS1_X_Gateway
 SG_ AWV_QFK_Signal2 : 148|10@1+ (1,0) [0|1023] ""  ICAS1_X_Gateway
 SG_ AWV_Fahrerbremswunsch_erf : 158|1@1+ (1.0,0.0) [0.0|1] ""  ICAS1_X_Gateway
 SG_ AWV_Timestamp_TTC : 161|13@1+ (0.001,0) [0.000|8.190] "Unit_Secon"  ICAS1_X_Gateway
 SG_ AWV_QFK_KrSoll_VZ : 175|1@1+ (1.0,0.0) [0.0|1] ""  ICAS1_X_Gateway
 SG_ AWV_QFK_KrSoll : 176|16@1+ (0.0000067,0) [0E-7|0.4390778] "Unit_MeterInver"  ICAS1_X_Gateway
 SG_ AWV_Status_AWU : 192|4@1+ (1.0,0.0) [0.0|15] ""  ICAS1_X_Gateway
 SG_ SOK_AWV_03_Signatur : 336|48@1+ (1,0) [0|281474976710655] "Unit_None"  ICAS1_X_Gateway

BO_ 2536767264 BAP_Debug_Cmd: 8 BAP_Tester
 SG_ BAP_Debug_Cmd : 0|16@1+ (1.0,0.0) [0.0|65535] ""  FASFrontradar,MFK,MFK120,MRR2023

BO_ 2536767280 BAP_Debug_Data: 8 FASFrontradar
 SG_ BAP_Debug_Data : 0|64@1+ (1.0,0.0) [0.0|18446744073709551615] ""  BAP_Tester

BO_ 2536728320 BAP_REM2_ASG_01: 8 ICAS1_X_Gateway
 SG_ BAP_REM2_ASG_01_Header : 0|64@1+ (1.0,0.0) [0.0|18446744073709551615] ""  FASFrontradar,MRR2023

BO_ 2536728336 BAP_REM2_FSG_01: 8 FASFrontradar
 SG_ BAP_REM2_FSG_01_Header : 0|64@1+ (1.0,0.0) [0.0|18446744073709551615] ""  ICAS1_X_Gateway

BO_ 2536728337 BAP_REM2_FSG_02: 8 FASFrontradar
 SG_ BAP_REM2_FSG_02_Header : 0|64@1+ (1.0,0.0) [0.0|18446744073709551615] ""  ICAS1_X_Gateway

BO_ 2536725248 BAP_REM_ASG_01: 8 ICAS1_X_Gateway
 SG_ BAP_REM_ASG_01_Header : 0|8@1+ (1,0) [0|255] "Unit_None"  MFK

BO_ 2536725249 BAP_REM_ASG_02: 64 ICAS1_X_Gateway
 SG_ BAP_REM_ASG_02_Header : 0|512@1+ (1.0,0.0) [0.0|13407807929942597099574024998205846127479365820592393377723561443721764030073546976801874298166903427690031858186486050853753882811946569946433649006084095] ""  MFK

BO_ 2536725264 BAP_REM_FSG_01: 8 MFK
 SG_ BAP_REM_FSG_01_Header : 0|8@1+ (1,0) [0|255] "Unit_None"  ICAS1_X_Gateway

BO_ 2536725265 BAP_REM_FSG_02: 8 MFK
 SG_ BAP_REM_FSG_02_Header : 0|8@1+ (1,0) [0|255] "Unit_None"  ICAS1_X_Gateway

BO_ 2536726273 BAP_TPA_ASG_02: 8 ICAS1_X_Gateway
 SG_ BAP_TPA_ASG_02_Header : 0|64@1+ (1.0,0.0) [0.0|18446744073709551615] ""  MFK

BO_ 2536726288 BAP_TPA_FSG_01: 8 MFK
 SG_ BAP_TPA_FSG_01_Header : 0|64@1+ (1.0,0.0) [0.0|18446744073709551615] ""  ICAS1_X_Gateway

BO_ 870 Blinkmodi_02: 8 ICAS1_X_Gateway
 SG_ Blinkmodi_02_CRC : 0|8@1+ (1,0) [0|255] ""  MFK,MFK120
 SG_ Blinkmodi_02_BZ : 8|4@1+ (1,0) [0|15] ""  MFK,MFK120
 SG_ BM_ZV_auf : 12|1@1+ (1.0,0.0) [0.0|1] ""  Vector__XXX
 SG_ BM_ZV_zu : 13|1@1+ (1.0,0.0) [0.0|1] ""  Vector__XXX
 SG_ BM_DWA_ein : 14|1@1+ (1.0,0.0) [0.0|1] ""  Vector__XXX
 SG_ BM_DWA_Alarm : 15|1@1+ (1.0,0.0) [0.0|1] ""  Vector__XXX
 SG_ BM_Crash : 16|1@1+ (1.0,0.0) [0.0|1] ""  Vector__XXX
 SG_ BM_Panik : 17|1@1+ (1.0,0.0) [0.0|1] ""  Vector__XXX
 SG_ BM_Not_Bremsung : 18|1@1+ (1.0,0.0) [0.0|1] ""  Vector__XXX
 SG_ BM_GDO : 19|1@1+ (1.0,0.0) [0.0|1] ""  Vector__XXX
 SG_ BM_Warnblinken : 20|1@1+ (1.0,0.0) [0.0|1] ""  FASFrontradar,MFK,MFK120
 SG_ BM_Taxi_Notalarm : 21|1@1+ (1.0,0.0) [0.0|1] ""  Vector__XXX
 SG_ BM_Telematik : 22|1@1+ (1.0,0.0) [0.0|1] ""  Vector__XXX
 SG_ BM_links : 23|1@1+ (1.0,0.0) [0.0|1] ""  MFK,MFK120
 SG_ BM_rechts : 24|1@1+ (1.0,0.0) [0.0|1] ""  MFK,MFK120
 SG_ Blinken_li_Fzg_Takt : 25|1@1+ (1.0,0.0) [0.0|1] ""  Vector__XXX
 SG_ Blinken_re_Fzg_Takt : 26|1@1+ (1.0,0.0) [0.0|1] ""  Vector__XXX
 SG_ Blinken_li_Kombi_Takt : 27|1@1+ (1.0,0.0) [0.0|1] ""  Vector__XXX
 SG_ Blinken_re_Kombi_Takt : 28|1@1+ (1.0,0.0) [0.0|1] ""  Vector__XXX
 SG_ BM_NBA_n_codiert_n_aktiv : 29|1@1+ (1.0,0.0) [0.0|1] ""  Vector__XXX
 SG_ BM_NBA_Status : 30|2@1+ (1.0,0.0) [0.0|3] ""  Vector__XXX
 SG_ BM_WBT_Beleuchtung : 32|1@1+ (1.0,0.0) [0.0|1] ""  Vector__XXX
 SG_ BM_HD_Oeffnung_angelernt : 33|1@1+ (1.0,0.0) [0.0|1] ""  Vector__XXX
 SG_ BM_Autobahn : 34|1@1+ (1.0,0.0) [0.0|1] ""  Vector__XXX
 SG_ BM_Rollenmodus_Blinken : 35|1@1+ (1.0,0.0) [0.0|1] ""  Vector__XXX
 SG_ BM_Recas : 36|1@1+ (1.0,0.0) [0.0|1] ""  Vector__XXX
 SG_ BM_Wischblinken : 37|1@1+ (1.0,0.0) [0.0|1] ""  Vector__XXX
 SG_ BM_Telematik_Abbruchgrund : 38|6@1+ (1.0,0.0) [0.0|63] ""  Vector__XXX
 SG_ BM_PiloPa : 44|1@1+ (1.0,0.0) [0.0|1] ""  Vector__XXX
 SG_ SAL_TA_Blinken_Status : 45|3@1+ (1.0,0.0) [0.0|7] ""  MFK,MFK120
 SG_ SAL_RHP_Blinken_Status : 49|3@1+ (1.0,0.0) [0.0|7] ""  Vector__XXX
 SG_ SAL_RHP_Warnblinken : 52|1@1+ (1.0,0.0) [0.0|1] ""  Vector__XXX
 SG_ DWA_Alarmquelle : 59|5@1+ (1.0,0.0) [0.0|31] ""  Vector__XXX

BO_TX_BU_ 333 :FASFrontradar,MRR2023;
BO_TX_BU_ 768 :FASFrontradar,MRR2023;
BO_TX_BU_ 2527679682 :FASFrontradar,MRR2023;
BO_TX_BU_ 2527679661 :FASFrontradar,MRR2023;
BO_TX_BU_ 219 :FASFrontradar,MRR2023;
BO_TX_BU_ 2536767280 :FASFrontradar,MFK,MFK120,MRR2023;
BO_TX_BU_ 2536728336 :FASFrontradar,MRR2023;
BO_TX_BU_ 2536728337 :FASFrontradar,MRR2023;

CM_ "E3V_FASCANFD1_V15.04.01.00F Generated by BusNet_NG_Produktiv 9.26.0.5_V2";
CM_ BU_ FASFrontradar "Frontradar (mit Funktion Adaptive Cruise Control) E3_Volumen";
CM_ BU_ ICAS1_X_Gateway "ICAS1.X E3 1.1 UNECE
DFL-Kürzel: Gateway";
CM_ BU_ MFK "Multifunktionskamera";
CM_ BU_ MFK120 "Multi function camera 120° E3 1_1 UNECE";
CM_ BU_ MRR2023 "Frontradar (mit Funktion Adaptive Cruise Control) E3_Volumen";
CM_ BU_ NR_1 "Nanoradar 01
Nahbereichsradar 01
DFL-Kürzel: NR_01";
CM_ BU_ NR_2 "Nanoradar 02
Nahbereichsradar 02
DFL-Kürzel: NR_02";

CM_ BO_ 1633 "ab MQB 7.2";
CM_ BO_ 616 "mit DLC32";
CM_ BO_ 870 "Nur die Kombination des statischen und toggelnden Signals ergibt den Blinktakt für die Hell & Dunkelphase";

CM_ SG_ 333 ACC_18_BZ "4bit Botschaftszähler, wird mit jeder Sendebotschaft inkrementiert";
CM_ SG_ 333 ACC_18_CRC "Für MLB:
Berechnung siehe Lastenheft 'Kommunikationsabsicherung für FlexRay und CAN'
Ab MQB und MLBevo:
Berechnung siehe Lastenheft 'End-to-End Kommunikationsabsicherung'

Endwerte siehe Begleitdokument 'S-PDU Kennungsfolgen'";
CM_ SG_ 333 ACC_Abbiegewunsch "Identifizierter Abbiegewunsch vom Fahrer";
CM_ SG_ 333 ACC_Abbiegewunsch_Abstand "Ort des identifizierten Abbiegewunsches vom Fahrer";
CM_ SG_ 333 ACC_Anfahren "Anforderung Anfahren";
CM_ SG_ 333 ACC_Anforderung_HMS "Bremsanforderung an den Haltemanager";
CM_ SG_ 333 ACC_Anhalten "Im Falle eines gesetzten Bits wird vom ACC ein Anhalten bis in den Stand gewünscht. Das Bit wird von ACC nur unterhalb einer appl. Geschwindigkeitsschwelle gesetzt. Notwendig für die ACCplus-Funktionalität. Nicht für Audi B8 relevant, jedoch im Vorgriff a";
CM_ SG_ 333 ACC_Anhalteweg "Verbleibender Weg bis zum Stillstand";
CM_ SG_ 333 ACC_DynErhoehung "Ansteuerung einer erhöhten Dynamik im Verzögerungsfall (vor allem beim Motormomentenabbau)";
CM_ SG_ 333 ACC_FoD_Status "Informiert den TSK und Kombi, ob die ACC-Funktion freigeschaltet ist oder nicht.";
CM_ SG_ 333 ACC_Freilauf_Info "Freilauf-Freigabe durch Aktiven Teilnehmer Freilauf";
CM_ SG_ 333 ACC_Freilaufstrategie_TSK "Das Signal definiert im aktiven ACC - Betrieb, ob ein Freilauf direkt über das ACC angefordert wird oder ein Freilauf über den Triebstrangkoordinator (TSK) angefordert wird, falls das ACC den Freilauf freigibt.";
CM_ SG_ 333 ACC_Minimale_Bremsung "Im Falle eines gesetzten Bits wird vom ACC dem TSK angezeigt, dass es sich im Resume_Suspend_Mode befindet. In diesem Mode darf der TSK keine ECD-Bremsung anfordern, unabhängig von der 'ACC_Sollbeschleunigungsanforderung'. Eine Fahrzeugverzögerung darf nu";
CM_ SG_ 333 ACC_neg_Sollbeschl_Grad_02 "Empfehlung an den Triebstrangkoordinator , mit welchem betragsmäßig maximalen negativen Gradienten eine ACC-Anforderung 'ACC_Sollbeschleunigung_02' einzuregeln ist.";
CM_ SG_ 333 ACC_pos_Sollbeschl_Grad_02 "Empfehlung an den Triebstrangkoordinator , mit welchem betragsmäßig maximalen positiven Gradienten eine ACC-Anforderung 'ACC_Sollbeschleunigung_02' einzuregeln ist.";
CM_ SG_ 333 ACC_Sollbeschleunigung_02 "Anforderung an den Triebstrangkoordinator , eine 'ACC_Sollbeschleunigung' umzusetzen.";
CM_ SG_ 333 ACC_Sollbeschleunigung_AD "ACC target acceleration torque for TSK";
CM_ SG_ 333 ACC_Status_ACC "'ACC OFF' bedeutet ACC-Hauptschalter ist 'Gerastet Aus

'ACC Reversibler Fehler' bedeutet, daß das ACC aktuell einen 
reversiblen Fehler im ACC-SG selbst oder in einem zum 
ACC-System gehörenden SG erkennt.

'ACC irreversibler Fehler' bedeutet, daß ";
CM_ SG_ 333 ACC_TA_Kurve_Abstand "Gibt den Abstand zu dem Punkt an, auf den sich das Geschwindigkeitsdelta bezieht. Dieser Punkt ist nicht der Kurveneingang, sondern der Punkt in der Kurve mit maximaler Krümmung. Der Kurveneingang kann uns nicht zur Verfügung gestellt werden";
CM_ SG_ 333 ACC_TA_Kurve_vDelta "Beschreibung: Gibt das Delta der vom ACC eingeregelten Geschwindigkeit im Vergleich zu der Geschwindigkeit an, die für eine erfolgreiche TA Durchfahrt eingestellt werden müsste.";
CM_ SG_ 333 ACC_Tempolimitassistent_Ein "Status ACC-Tempolimitassistent";
CM_ SG_ 333 ACC_Typ "Motor plausibilisiert seine eigene Kodierung";
CM_ SG_ 333 ACC_Verkehrssinn "Vom Radar erkannter Verkehrssinn";
CM_ SG_ 333 ACC_zul_Regelabw_oben "Anforderung an den Triebstrangkoordinator. Zulässiger Betrag der Abweichung zwischen angeforderter 'ACC_Sollbeschleunigung(_02)' und umzusetzender Sollbeschleunigung  im TSK. Im TSK wird, abhängig vom Arbeitspunkt die Toleranz und die Sollbeschleunigung f";
CM_ SG_ 333 ACC_zul_Regelabw_unten "Anforderung an den Triebstrangkoordinator. Zulässiger Betrag der Abweichung zwischen angeforderter 'ACC_Sollbeschleunigung(_02)' und umzusetzender Sollbeschleunigung  im TSK. Im TSK wird, abhängig vom Arbeitspunkt die Toleranz und die Sollbeschleunigung f";
CM_ SG_ 333 MPPmod_1_Segment "Erstes vom MPP abweichendes Segment, welches befahren werden soll.";
CM_ SG_ 333 MPPmod_2_Segment "Zweites vom MPP abweichendes Segment, welches befahren werden soll";
CM_ SG_ 333 MPPmod_3_Segment "Drittes vom MPP abweichendes Segment, welches befahren werden soll.";
CM_ SG_ 333 MPPmod_4_Segment "Viertes vom MPP abweichendes Segment, welches befahren werden soll.";
CM_ SG_ 333 RDR_v_ueber_Grund "Das Signal V_ueber_Grund zeigt die Fahrzeuggeschwindigkeit über Grund in X-Richtung an.
Das Signal wird ausschließlich durch Auswertung von Radarsignalen erzeugt.";
CM_ SG_ 333 RDR_v_ueber_Grund_Fahrtrichtung "Das Signal zeigt die Fahrtrichtung des Fahrzeugs an.  
Das Signal wird ausschließlich durch Auswertung von Radarsignalen erzeugt.";
CM_ SG_ 333 RDR_v_ueber_Grund_Genauigkeit "Das Signal zeigt die Genauigkeit des Geschwindigkeitssignals RDR_v_ueber_Grund im 95%-Konfidenzintervall an.";
CM_ SG_ 333 RDR_VBEG_Anforderung "Anforderung einer Höchstgeschwindigkeitsbegrenzung durch den Frontradar";

CM_ SG_ 768 AbstWarn_LRR_FAS_Fkt_Status "Rückmeldung des Funktionsstatus an FAS ProfileMaster";
CM_ SG_ 768 ACA_Hinweistexte "Anzeigesignal für Hinweise zur Fahrerbedienenhandlung";
CM_ SG_ 768 ACA_Querfuehrung "Ansteuerung einer primären Anzeige 'Querführung aktiv' für ACA in verschiedenen Farben";
CM_ SG_ 768 ACA_Querfuehrung_Texte "Signal zur Ansteuerung von Fahrerhinweisen der Querführung in ACA im Mitteldisplay";
CM_ SG_ 768 ACC_Abstand_LNS "VW: Anzeige des gemessenen Abstands zum linken Nebenspurobjekt (LNS) als Entfernung von der Hinterachse des Egofahrzeugs";
CM_ SG_ 768 ACC_Abstand_RNS "VW: Anzeige des gemessenen Abstands zum rechten Nebenspurobjekt (RNS) als Entfernung von der Hinterachse des Egofahrzeugs";
CM_ SG_ 768 ACC_Abstand_WZO "VW: Anzeige des gemessenen Abstands zum Zielobjekt (WZO) als Entfernung von der Hinterachse des Egofahrzeugs";
CM_ SG_ 768 ACC_Abstandsindex_02 "Für die optionale Anzeige einer einheitenlosen Abstandsreserve oder einer gemessenen Zeitlücke in der Zusatzanzeige. Der Wertebereich 1..1021 entspricht Audi (aktiv_Folgefahrt), VW (passiv/aktiv_Folgefahrt). Audi nutzt den Wertebereich 0..1023, VW nutzt d";
CM_ SG_ 768 ACC_Akustik_03 "Ansteuerung der zugehörigen Akustik im Kombiinstrument, solange die entsprechende Bitkombination gesetzt ist.";
CM_ SG_ 768 ACC_Anzeige_Maximalabstand "VW: Zur Skalierung der Anzeige auf die maximale Reichweite (geschwindigkeitsabhängig) als Entfernung von der Hinterachse des Egofahrzeugs";
CM_ SG_ 768 ACC_Anzeige_Objektmarkierung "Ansteuerung des HUD-Balken bei einer höheren Verzögerung oder einer Objekterkennung auf ein Ziel.";
CM_ SG_ 768 ACC_Anzeige_Objektregelung "VW: Hervorhebung relevantes Regelobjekt in der ACC-Anzeige";
CM_ SG_ 768 ACC_Anzeige_Zeitluecke "Anforderung zur Umschaltung zwischen dem Anzeigemodus 'Keine Änderung Zeitlücke' und 'Änderung Zeitlücke' (z.B. Pfeildarstellung in Zusatzanzeige)
";
CM_ SG_ 768 ACC_Display_Prio "Zur situationsabhängigen Prioritätensteuerung von ACC Anzeigen im nicht permanenten Anzeigebereich. Im Kombiinstrument ist jeder Prioritätsstufe eine adäquate Prio-Definition zugeordnet.

";
CM_ SG_ 768 ACC_EGO_Fahrzeug "Ansteuerung einer Statusanzeige für ACC in verschiedenen Farben";
CM_ SG_ 768 ACC_Einheit_maxSetzgeschw "Einheit zu Signal ACC_maxSetzgeschw";
CM_ SG_ 768 ACC_ENG_Texte "Signal zur Ansteuerung von Fahrerhinweisen der Energo-Funktioin im Mitteldisplay ";
CM_ SG_ 768 ACC_ENG_Texte_02 "Signal zur Ansteuerung von Fahrerhinweisen der Energo-Funktion im Mitteldisplay";
CM_ SG_ 768 ACC_FoD_Status "Informiert den TSK und Kombi, ob die ACC-Funktion freigeschaltet ist oder nicht.";
CM_ SG_ 768 ACC_FzgStatus_Anfahrbereitschaft "Signal zur Ansteuerung von Fahrerhinweisen der ACC-Anfahrbereitschaft im Mitteldisplay";
CM_ SG_ 768 ACC_FzgStatus_Fehleranzeige "Signal zur Ansteuerung von Fahrerhinweisen der ACC-Fehleranzeige im Mitteldisplay";
CM_ SG_ 768 ACC_FzgStatus_Kamerafusion "Signal zur Ansteuerung von Fahrerhinweisen der ACC-Objekterkennung im Mitteldisplay";
CM_ SG_ 768 ACC_Gesetzte_Zeitluecke "Nur in ADR/ACC-Fahrzeugen: ACC Zusatzanzeige: 0 = aus / ungleich 0 = ein; angezeigte ADR-Zeitlücke wird auf 3 Bits begrenzt";
CM_ SG_ 768 ACC_iBoost_Anzeige "Signal dient der Anzeige des iBoost für die Funktion ACC";
CM_ SG_ 768 ACC_maxSetzgeschw "maximale ACC-Setzgeschwindigkeit zur Ansteuerung des ACC-Setzbereichs im Kombi
Hinweis: Signal ist mit Signal ACC_Einheit_maxSetzgeschw zu interpretieren";
CM_ SG_ 768 ACC_Modus_Pop_Up "Steuert das Pop-Up bei der Modus-Umschaltung zwischen den Längsregelfunktionen";
CM_ SG_ 768 ACC_Optischer_Fahrerhinweis "Fahrerübernahmeaufforderung; z.B. bei Erreichen der Systemgrenzen oder beim Auftreten von Fehlern in kritischen Situationen (VW).
";
CM_ SG_ 768 ACC_Regelgeschw "Zur Anzeige der Regelgeschwindigkeit (z.B. Kurven- / Tempolimitassistent) im Kombiinstrument";
CM_ SG_ 768 ACC_Regelung_AIO "Unterscheidung im Kombi, ob pACC Regelung auf Ampel aktiv oder AIO zur Anzeige kommt";
CM_ SG_ 768 ACC_rel_Objekt_Zusatzanz "Für optionale Anzeige eines Bildes/Textes in der Zusatzanzeige. ";
CM_ SG_ 768 ACC_Relevantes_Objekt_02 "Ansteuerung einer primären Anzeige 'Relevantes Objekt' für ACC in verschiedenen Farben.";
CM_ SG_ 768 ACC_RUV "Anzeige für Rechtsunterholverhinderung in Abhängigkeit Rechts- / Linksverkehr";
CM_ SG_ 768 ACC_Sollabstand_1 "VW: Anzeige der Fahrerwunschzeitlücke 1 zum Zielobjekt (WZO) als Entfernung von der Hinterachse des Egofahrzeugs";
CM_ SG_ 768 ACC_Sollabstand_2 "VW: Anzeige der Fahrerwunschzeitlücke 2 zum Zielobjekt (WZO) als Entfernung von der Hinterachse des Egofahrzeugs";
CM_ SG_ 768 ACC_Sollabstand_3 "VW: Anzeige der Fahrerwunschzeitlücke 3 zum Zielobjekt (WZO) als Entfernung von der Hinterachse des Egofahrzeugs";
CM_ SG_ 768 ACC_Sollabstand_4 "VW: Anzeige der Fahrerwunschzeitlücke 4 zum Zielobjekt (WZO) als Entfernung von der Hinterachse des Egofahrzeugs";
CM_ SG_ 768 ACC_Sollabstand_5 "VW: Anzeige der Fahrerwunschzeitlücke 5 zum Zielobjekt (WZO) als Entfernung von der Hinterachse des Egofahrzeugs";
CM_ SG_ 768 ACC_Status_Anzeige "Status nur zur Defintion von Anzeige im Kombi. Hinweis: Wird für die spez. VW-Anzeige (überlappende Anzeigebereiche) verwendet. Vom AUDI-ACC im Rahmen der Modulstrategie zu bedienen.";
CM_ SG_ 768 ACC_Status_GRA_Modus "Statusinformation zur GRA in Verbindung mit ACC";
CM_ SG_ 768 ACC_Status_Stauende "Information, ob ACC auf ein Stauende auf Basis von Car2X reagiert.";
CM_ SG_ 768 ACC_Statusicon "Statusanzeige der aktiven Längsregelfuntkion (ACC/GRA-Modus)";
CM_ SG_ 768 ACC_Tachokranz "Für zusätzliche Status- und Einstellbereichsanzeige im Tacho. (z.B. Tachokranz)
";
CM_ SG_ 768 ACC_Tempolimit "Anzeige einer Tempolimit-Vorgabe (Geschwindigkeitsbegrenzung, Aufhebung einer Geschwindigkeitsbegrenzung)

Signalbeschreibung 0..31: siehe LH Kombi-SG_-_6.2.x_ACC";
CM_ SG_ 768 ACC_Tempolimit_Einheit "Einheit des Verkehrszeichen in ACC_Tempolimit";
CM_ SG_ 768 ACC_Texte_02 "Zusätzliches Signal zu 'ACC_Texte_Primaeranz', welches Warnungen und Fahrerhinweise bzgl. ACC im Mitteldisplay des Kombis anzeigt.";
CM_ SG_ 768 ACC_Texte_03 "Zusätzliches Signal zu 'ACC_Texte_Primaeranz', welches Warnungen und Fahrerhinweise bzgl. ACC im Mitteldisplay des Kombis anzeigt; Signalergänzung der Aktivierverhinderung aufgrund Geschwindigkeitsgrenze für ACC und TA";
CM_ SG_ 768 ACC_Texte_Primaeranz_03 "Textdefinitionen";
CM_ SG_ 768 ACC_Texte_Sekundaeranz_02 "VW: Anzeige ACC Informationen, wie z.B. die Vorankündigung, oder die Anfahrbereitschaft";
CM_ SG_ 768 ACC_Texte_Sekundaeranz_03 "VW: Anzeige ACC Informationen, wie z.B. die Vorankündigung, oder die Anfahrbereitschaft";
CM_ SG_ 768 ACC_Texte_Zusatzanz_03 "Beschreibt aktuell aktives Fahrprogramm/Zeitlücke usw. des ACC";
CM_ SG_ 768 ACC_Typ_LNS "VW: Anzeige der Klasse des linken Nebenspurobjektes (LNS)";
CM_ SG_ 768 ACC_Typ_RNS "VW: Anzeige der Klasse des rechten Nebenspurobjektes (RNS)";
CM_ SG_ 768 ACC_Typ_Tachokranz_unten "Mit diesem Bit wird die LED unterhalb der minimalen Setzgeschwindigkeit an/ausgeschaltet.
";
CM_ SG_ 768 ACC_Typ_WZO "VW: Anzeige der Klasse des Zielobjektes (WZO)";
CM_ SG_ 768 ACC_Warnung_Verkehrszeichen_1 "PACC: Zeigt bei Überschreitung der aktuellen Höchstgeschwindigkeit um 10% einen Hinweis im Kombi an";
CM_ SG_ 768 ACC_Wunschgeschw_02 "Zur Anzeige der Wunschgeschwindigkeit im Kombiinstrument
";
CM_ SG_ 768 ACC_Wunschgeschw_erreicht "Signal for Bentley BY83x: ACC_set_speed_achieved

Mit diesem Signal wird im Kombi eine Anzeige angesteuert, wenn das Fahrzeug die gesetzte Wunschgeschwindigkeit erreicht hat.

This signal illuminates the set speed icon a different colour  in the Kombi";
CM_ SG_ 768 ACC_Wunschgeschw_Farbe "Umschaltung der Farbe der angezeigten Setzgeschwindigkeit im Tacho";
CM_ SG_ 768 ACC_Wunschgeschw_Farbe_02 "Umschaltung der Farbe der angezeigten Setzgeschwindigkeit im Tacho";
CM_ SG_ 768 FAS_Licht_Anf "Anforderung zum Einschalten des Assistenzfahrlicht";
CM_ SG_ 768 STA_Primaeranz "Signal zur Ansteuerung der STA-Primaeranzeige";
CM_ SG_ 768 STA_Texte "Signal, welches Warnungen und Fahrerhinweise bzgl. der Funktion STA im Kombi anzeigt";
CM_ SG_ 768 STA_Zusatzanz "Für Anzeigen der STA-Funktion im Mitteldisplay";

CM_ SG_ 2197378135 ACC_Sollbeschleunigung_AD "ACC target acceleration torque for TSK";

CM_ SG_ 2527679682 ACC_ASM_Data_1 "Dieses Signal wird von ACC (LongRangeRadar) befüllt und an den Assistenzsystemmonitor ASM (Host SG: Safety Computer) gesendet.";
CM_ SG_ 2527679682 ACC_ASM_Data_2 "Dieses Signal wird von ACC (LongRangeRadar) befüllt und an den Assistenzsystemmonitor ASM (Host SG: Safety Computer) gesendet.";
CM_ SG_ 2527679682 ACC_ASM_Data_3 "Dieses Signal wird von ACC (LongRangeRadar) befüllt und an den Assistenzsystemmonitor ASM (Host SG: Safety Computer) gesendet.";
CM_ SG_ 2527679682 ACC_ASM_Data_4 "Dieses Signal wird von ACC (LongRangeRadar) befüllt und an den Assistenzsystemmonitor ASM (Host SG: Safety Computer) gesendet.";
CM_ SG_ 2527679682 ACC_ASM_Data_5 "Dieses Signal wird von ACC (LongRangeRadar) befüllt und an den Assistenzsystemmonitor ASM (Host SG: Safety Computer) gesendet.";
CM_ SG_ 2527679682 ACC_ASM_Data_6 "Dieses Signal wird von ACC (LongRangeRadar) befüllt und an den Assistenzsystemmonitor ASM (Host SG: Safety Computer) gesendet.";
CM_ SG_ 2527679682 ACC_ASM_Ereignis "Dieses Signal definiert, welche Funktion und welche Art von Aktivität das Senden der Botschaft an den Assistenzsystemmonitor ASM (Host SG: Safety Computer) veranlasst hat.";
CM_ SG_ 2527679682 ACC_ASM_Zeitstempel_02 "Dieses Signal ermöglicht die zeitliche Zuordnung der von ACC an den Assistenzsystemmonitor ASM (Host SG: Safety Computer) gesendeten Statusbotschaften.";

CM_ SG_ 64 AB_Anzeige_Fussg "Anzeige für ausgelöste Fussgängerschutz-Aktuatorik";
CM_ SG_ 64 AB_Belegung_VF "Belegungserkennung vorne Fahrer.";
CM_ SG_ 64 AB_Crash_Int "Crash_Intensität_1 = fahrzeugabhängige Reaktionen im Crash
Crash_Intensität_2 = fahrzeugabhängige Reaktionen im Crash
Crash_Intensität_3 = fahrzeugabhängige Reaktionen im Crash

Die jeweiligen fahrzeugabhängigen Reaktionen im Crash sind in einem separ";
CM_ SG_ 64 AB_Deaktiviert "Airbag oder Gurtstraffer wurden per Anpassung deaktiviert: Aktualisierung erst nach Selbsttest";
CM_ SG_ 64 AB_Deaktivierung_HV "Deaktivierung des HV-Systems und der HV-Teilnehmer im Crash (u.a. Hybrid- und Elektrofahrzeuge)";
CM_ SG_ 64 AB_Diagnose "Airbag in Diagnose";
CM_ SG_ 64 AB_eCS_Error "Signal zur Anforderung der Anzeige von Störungen im System der elektrischen Gurtverriegelung";
CM_ SG_ 64 AB_EDR_Trigger "Triggerbedingung zur dezentralen Aufzeichnung unfallrelevanter Daten im Event Data Recorder";
CM_ SG_ 64 AB_Erh_Auf_VB "Der Fahrer soll bei einem Statuswechsel des Beifahrerairbags (ausgelöst durch die Beifahrerinsassenerkennung oder den Schlüsselschloßschalter) aufmerksam gemacht werden durch eine Anzeige im Kombi. Nur Audi: gültig für: AB2 (4-Türer AU352), B7, C6, D3";
CM_ SG_ 64 AB_Front_Crash "Bit wird bei Überschreitung der Gurtstraffer-, US- und RdW-Schwelle gesetzt";
CM_ SG_ 64 AB_Gurtschloss_FA_ext "Das Ergebnis der Basisfunktion 'Plausibilisierung Gurtschloss' des Verlassenskonzepts wird im Signal dargestellt.";
CM_ SG_ 64 AB_Gurtschloss_FA_ext_aktiv "Über dieses Signal wird signalisiert ob die Erweiterte Gurtdiagnose (Ergebnis wird im Signal AB_Gurtschloss_FA_ext dargestellt) aktiviert oder deaktiviert ist.";
CM_ SG_ 64 AB_Gurtwarn_VB "Beifahrer hat Gurt nicht gesteckt, Anzeige im Kombi";
CM_ SG_ 64 AB_Gurtwarn_VF "Fahrer hat Gurt nicht gesteckt, Anzeige im Kombi";
CM_ SG_ 64 AB_Heck_Crash "Wird für alle neu anlaufenden Projekte umgesetzt: AB8.4, Audi8/VW8";
CM_ SG_ 64 AB_Lampe "Sicherheitswarnlampe im Kombi wird vom Airbag-SG angesteuert; Zustand der Lampe wird auf dem CAN-Bus ausgegeben (auch Blinkinformation).";
CM_ SG_ 64 AB_MKB_Anforderung "Anforderung Multi-Kollisions-Bremsung";
CM_ SG_ 64 AB_MKB_gueltig "Multi-Kollisions-Bremsung im Airbag freigeschaltet";
CM_ SG_ 64 AB_PAO_Leuchte_Anf "Anforderung an die Passenger-Airbag-Off Leuchte in der Dachkonsole (ein / aus), Einsatz nur bei PAG";
CM_ SG_ 64 AB_RGS_Anst "PreCrash-Ansteuerung reversibler Gurtstraffer (Aktivierung und Kraftniveau)

10xx = deaktiviert";
CM_ SG_ 64 AB_Rollover_Crash "Wird im B6/B7 Cabrio und New Beetle Cabrio bedient. ";
CM_ SG_ 64 AB_SB_Crash "Z.Zt. nur in Verbindung mit Crash-Intensität >= 100b (Kraftstoffpumpenabschaltung) verwendet.
";
CM_ SG_ 64 AB_SF_Crash "Z.Zt. nur in Verbindung mit Crash-Intensität >= 100b (Kraftstoffpumpenabschaltung) verwendet.";
CM_ SG_ 64 AB_Stellgliedtest "Information, ob Airbag im Stellgliedtest ist, um eine Notrufauflösung beim Stellgliedtest zu verhindern";
CM_ SG_ 64 AB_Systemfehler "Systemfehler Ggf. wird Warnlampe dauernd eingeschaltet.";
CM_ SG_ 64 AB_Texte_AKS "Textanzeige für pyrotechnische Auslösung der aktiven Kopfstütze (AKS)";
CM_ SG_ 64 AB_VB_deaktiviert "Als Option vorgehalten, Beifahrerairbag wurden per Schlüsselschalter oder Insassenerkennung deaktiviert";
CM_ SG_ 64 AB_Versorgungsspannung "Übertragung der Plausibilitätsinformation Kl.15-Last vs. Kl.15-CAN.
Bedienung im Fall Kl.15-Last 'EIN' und Kl.15-CAN 'AUS' mit Ausgabe Warnung/Akustik im Kombi.";
CM_ SG_ 64 Airbag_01_CRC "Für MLB:
'Berechnung siehe Lastenheft 'Kommunikationsabsicherung für FlexRay und CAN''

Ab MQB und MLBevo:
'Berechnung siehe Lastenheft 'End-to-End Kommunikationsabsicherung''

Endwerte siehe Begleitdokument 'S-PDU Kennungsfolgen'";
CM_ SG_ 64 ASM_Masterzeit_02 "Masterzeit für alle ASM Sender";

CM_ SG_ 1312 AB_Abschaltanf_SIH_BF "Die Insassenerkennung auf der Beifahrerseite fordert bei Übertemperatur eine Abschaltung der Sitzheizung an. Die Übertemperatur kann bei niederohmigen Nebenschlüssen der Sitzheizungsmatte als Folge von zu hohem resultierenden Strom auftreten.";
CM_ SG_ 1312 AB_Anforderung_eCall "Trigger für Car2X Steuergerät das ein eCall Ereignis erkannt wurde.";
CM_ SG_ 1312 AB_Anforderung_USM "Trigger für Gateway (OBDC) und MIB/MMI, dass ein USM-Ereignis erkannt wurde.";
CM_ SG_ 1312 AB_Anprall_FGS "Uebermittlung der Lage einer Kollision, Fussgaengerschutz-Aktorik";
CM_ SG_ 1312 AB_Anprall_Front_Beifahrer "Uebermittlung der Lage einer Kollision, Anprallzone Front Beifahrerseite";
CM_ SG_ 1312 AB_Anprall_Front_Fahrer "Uebermittlung der Lage einer Kollision, Anprallzone Front Fahrerseite";
CM_ SG_ 1312 AB_Anprall_Seite_Beifahrer "Uebermittlung der Lage einer Kollision, Anprallzone Beifahrerseite Seite";
CM_ SG_ 1312 AB_Anprall_Seite_Fahrer "Uebermittlung der Lage einer Kollision, Anprallzone Fahrerseite Seite";
CM_ SG_ 1312 AB_Belegung_VB "Belegungserkennung vorne Beifahrer. Wird in US-Steuergeräten über Bladder-Matte bedient, optional bei RdW, falls SBE_EuroNCAP entschieden wird.";
CM_ SG_ 1312 AB_Crashschwere "Übermittlung der Crashschwere an das Gateway (OBDC)";
CM_ SG_ 1312 AB_Gurtschloss_BF "Gurtschlossstatus Beifahrerseite";
CM_ SG_ 1312 AB_Gurtschloss_FA "Gurtschlosstatatus Fahrerseite";
CM_ SG_ 1312 AB_Gurtschloss_Reihe2_BF "Gurtschlossstatus 2. Reihe Beifahrerseite,  Mehrausstattung";
CM_ SG_ 1312 AB_Gurtschloss_Reihe2_FA "Gurtschlossstatus 2. Reihe Fahrerseite, Mehrausstattung";
CM_ SG_ 1312 AB_Gurtschloss_Reihe2_MI "Gurtschlossstatus 2. Reihe Mitte,  Mehrausstattung";
CM_ SG_ 1312 AB_Gurtschloss_Reihe3_BF "Gurtschlossstatus 3. Reihe Beifahrerseite,  Mehrausstattung";
CM_ SG_ 1312 AB_Gurtschloss_Reihe3_FA "Gurtschlossstatus 3. Reihe Fahrerseite,  Mehrausstattung";
CM_ SG_ 1312 AB_Gurtschloss_Reihe3_MI "Gurtschlossstatus 3. Reihe Mitte,  Mehrausstattung";
CM_ SG_ 1312 AB_Sitzpos_Sens_BF "Ausgabe Sitzposition Beifahrer";
CM_ SG_ 1312 AB_Sitzpos_Sens_FA "Ausgabe Sitzposition Fahrer";
CM_ SG_ 1312 AB_Wickelklappung_Reihe2_BF "Status Wickelklappung 2. Reihe Beifahrerseite, Mehrausstattung";
CM_ SG_ 1312 AB_Wickelklappung_Reihe2_FA "Status Wickelklappung 2. Reihe Fahrerseite, Mehrausstattung";
CM_ SG_ 1312 AB_Wickelklappung_Reihe2_MI "Status Wickelklappung 2. Reihe Mitte, Mehrausstattung";
CM_ SG_ 1312 Airbag_02_CRC "Für MLB:
'Berechnung siehe Lastenheft 'Kommunikationsabsicherung für FlexRay und CAN''

Ab MQB und MLBevo:
'Berechnung siehe Lastenheft 'End-to-End Kommunikationsabsicherung''

Endwerte siehe Begleitdokument 'S-PDU Kennungsfolgen'";
CM_ SG_ 1312 LoGeWa_Event_Kombiwarnung "Event für Kombiwarnung";
CM_ SG_ 1312 SC_PAO_OFF_Anf "Sollwert für LED 'OFF' in Anzeige Passenger Airbag On/Off";
CM_ SG_ 1312 SC_PAO_ON_Anf "Sollwert für LED 'ON' in Anzeige Passenger Airbag On/Off";
CM_ SG_ 1312 SC_PAO_Schriftzug_Anf "Sollwert für LED 'PASSENGER AIRBAG' in Anzeige Passenger Airbag On/Off";

CM_ SG_ 1349 AB_Anprall_Heck "Uebermittlung der Lage einer Kollision, Anprallzone Heck";
CM_ SG_ 1349 AB_Belegung_VF_ext "Das Signal kommuniziert den Status des Sitzbelegsensors Fahrer incl. dauerhafter Zustände mit Signalqualität ASIL A.";
CM_ SG_ 1349 AB_Belegung_VF_ext_aktiv "Kennzeichnet aktive Funktion 'Erweiterte Sitzbelegdiagnose' für Signal AB_Belegung_VF_ext";
CM_ SG_ 1349 AB_Gurtwarn_Reihe2_BF "Status Gurtwarnung 2. Sitzreihe Beifahrerseite";
CM_ SG_ 1349 AB_Gurtwarn_Reihe2_FA "Status Gurtwarnung 2. Sitzreihe Fahrerseite";
CM_ SG_ 1349 AB_Gurtwarn_Reihe2_MI "Status Gurtwarnung 2. Sitzreihe Mitte";
CM_ SG_ 1349 AB_Gurtwarn_Reihe3_BF "Status Gurtwarnung 3. Sitzreihe Beifahrerseite";
CM_ SG_ 1349 AB_Gurtwarn_Reihe3_FA "Status Gurtwarnung 3. Sitzreihe Fahrerseite";
CM_ SG_ 1349 AB_Gurtwarn_Reihe3_MI "Status Gurtwarnung 3. Sitzreihe Mitte";
CM_ SG_ 1349 AB_Gurtwarn_Reihe4_BF "Status Gurtwarnung 4. Sitzreihe Beifahrerseite";
CM_ SG_ 1349 AB_Gurtwarn_Reihe4_FA "Status Gurtwarnung 4. Sitzreihe Fahrerseite";
CM_ SG_ 1349 AB_Gurtwarn_Reihe4_MI "Status Gurtwarnung 4. Sitzreihe Mitte";
CM_ SG_ 1349 AB_SBR_hinten_verbau "Verbauinformation Sitzbelegungssensor hinten (2. und 3. Sitzreihe)";
CM_ SG_ 1349 AbstWarn_MV_FAS_Fkt_Status "FAS-ProfileMaster Iststatus der Kundenfunktion";
CM_ SG_ 1349 Airbag_04_BZ "4bit Botschaftszähler, wird mit jeder Sendebotschaft inkrementiert";
CM_ SG_ 1349 Airbag_04_CRC "Für MLB:
Berechnung siehe Lastenheft 'Kommunikationsabsicherung für FlexRay und CAN'
Ab MQB und MLBevo:
Berechnung siehe Lastenheft 'End-to-End Kommunikationsabsicherung'

Endwerte siehe Begleitdokument 'S-PDU Kennungsfolgen'";
CM_ SG_ 1349 AWV_Einstellung_System_ASG "Signal zur Realisierung des BAP-Koordinators";
CM_ SG_ 1349 AWV_Einstellung_Warnung_ASG "Signal zur Realisierung des BAP-Koordinators";
CM_ SG_ 1349 LGI_FAS_Fkt_Status "FAS-ProfileMaster Iststatus der Kundenfunktion (LGI: Lokale Gefahreninformation)";
CM_ SG_ 1349 PreCrash_FAS_Fkt_Status "FAS-ProfileMaster Iststatus der Kundenfunktion";
CM_ SG_ 1349 SC_PreSense_Modus_System_KAS "BAP-Kommunikation zum Kreuzungsassistent";
CM_ SG_ 1349 SC_PreSense_Modus_System_MV "Signal zur Realisierung der BAP-Kommunikation für PreSense";
CM_ SG_ 1349 SC_PreSense_Modus_System_NV "Signal zur Realisierung der BAP-Kommunikation für PreSense";
CM_ SG_ 1349 SC_PreSense_Modus_Warnung_MV "Signal zur Realisierung der BAP-Kommunikation für PreSense";
CM_ SG_ 1349 SC_PreSense_Modus_Warnung_NV "Signal zur Realisierung der BAP-Kommunikation für PreSense";
CM_ SG_ 1349 WarnBrems_Charisma_FahrPr "Aktuell eingestelltes Fahrprogramm der Funktion Warn- und/oder Notbremsfunktion";
CM_ SG_ 1349 WarnBrems_Charisma_Status "Verfügbarkeit der Funktion Warn- und/oder Notbremsfunktion für die Ansteuerung durch den Charisma-Koordinator.";

CM_ SG_ 2527679722 AB_Gurtschloss_MI "Gurtschloss-Status 1. Reihe Mitte
Ersteinsetzer: T6PA";
CM_ SG_ 2527679722 AB_Gurtschloss_Reihe4_BF "Gurtschlossstatus 4. Reihe Beifahrerseite,  Mehrausstattung";
CM_ SG_ 2527679722 AB_Gurtschloss_Reihe4_FA "Gurtschlossstatus 4. Reihe Fahrerseite, Mehrausstattung";
CM_ SG_ 2527679722 AB_Gurtschloss_Reihe4_MI "Gurtschlossstatus 4. Reihe Mitte,  Mehrausstattung";
CM_ SG_ 2527679722 AB_Gurtwarn_VM "Beifahrer auf mittlerem Sitz (Nutzfahrzeug) hat Gurt nicht gesteckt, Anzeige im Kombi";
CM_ SG_ 2527679722 AB_wSBR_Batteriestatus "Anzeige einer schwachen Batterie in einer Sitzeinheit des wSBR-Systems im Kombi.";

CM_ SG_ 1633 AAG_Anhaenger_abgesteckt "Anhaenger wurde bei Kl. 15 aus abgesteckt";
CM_ SG_ 1633 AAG_Anhaenger_erkannt "Erkennung Anhaenger ";
CM_ SG_ 1633 AAG_AVS_Fehler_02 "Fehler AVS";
CM_ SG_ 1633 AAG_AVS_Fehler_02_inv "Fehler AVS (inverses Signal)";
CM_ SG_ 1633 AAG_AVS_Stati "Status AVS (bei abnehmbarer oder mech.schwenkbarer Anhängerkupplung ist der Status immer 0)";
CM_ SG_ 1633 AAG_Blinker_H_aktiv "Status: Anhaenger Blinker aktiv";
CM_ SG_ 1633 AAG_Blinker_HL_def "Anhaenger Blinker links defekt";
CM_ SG_ 1633 AAG_Blinker_HR_def "Anhaenger Blinker rechts defekt";
CM_ SG_ 1633 AAG_Bremsl_durch_ECD "Bremslicht durch ECD aktiv";
CM_ SG_ 1633 AAG_Bremslicht_H_def "Anhaenger Bremslicht defekt";
CM_ SG_ 1633 AAG_Bremslicht_Reku "AAG_Bremslicht_Reku meldet zyklisch den empfangenen Zustand des CAN-Signals MO_Bremslicht_Reku zurück.";
CM_ SG_ 1633 AAG_BZ "4bit-Botschaftszaehler, wird in jeder Sendebotschaft inkrementiert

";
CM_ SG_ 1633 AAG_LED_aktiv "Dieses Signal sendet der Beleuchtungsart des Anhängers (LED oder Lampe)
Bei LED aktiv erfolgt kein Kaltüberwachung";
CM_ SG_ 1633 AAG_NSL_aktiv "Anhaenger Nebelschlusslicht aktiv";
CM_ SG_ 1633 AAG_Schlusslicht_HL_def "Anhaenger Schlußlicht links defekt";
CM_ SG_ 1633 AAG_Schlusslicht_HR_def "Anhaenger Schlußlicht rechts defekt";

CM_ SG_ 616 US_Datenalter_HLS "Das Signal beinhaltet die Zeitdifferenz zwischen Sendezeitpunkt und Messzeitpunkt bezogen auf die steuergeräte-interne Zeit.";
CM_ SG_ 616 US_Datenalter_HRS "Das Signal beinhaltet die Zeitdifferenz zwischen Sendezeitpunkt und Messzeitpunkt bezogen auf die steuergeräte-interne Zeit.";
CM_ SG_ 616 US_Datenalter_VLS "Das Signal beinhaltet die Zeitdifferenz zwischen Sendezeitpunkt und Messzeitpunkt bezogen auf die steuergeräte-interne Zeit.";
CM_ SG_ 616 US_Datenalter_VRS "Das Signal beinhaltet die Zeitdifferenz zwischen Sendezeitpunkt und Messzeitpunkt bezogen auf die steuergeräte-interne Zeit.";
CM_ SG_ 616 US_Fehler_HLS "Fehlerbit der hinteren linken seitlichen US-Sensorik";
CM_ SG_ 616 US_Fehler_HRS "Fehlerbit der hinteren rechten seitlichen US-Sensorik";
CM_ SG_ 616 US_Fehler_VLS "Fehlerbit der vorderen linken seitlichen US-Sensorik";
CM_ SG_ 616 US_Fehler_VRS "Fehlerbit der vorderen rechten seitlichen US-Sensorik";
CM_ SG_ 616 US_Links_01_Pos_X "x-Koordinate durch Mehrfachmessung bestätigter Messpunkt 01 links im FZG-Koordinatensystem";
CM_ SG_ 616 US_Links_01_Pos_Y "y-Koordinate durch Mehrfachmessung bestätigter Messpunkt 01 links im FZG-Koordinatensystem";
CM_ SG_ 616 US_Links_01_Valid "Valid Flag Messpunkt 01 links";
CM_ SG_ 616 US_Links_02_Pos_X "x-Koordinate durch Mehrfachmessung bestätigter Messpunkt 02 links im FZG-Koordinatensystem";
CM_ SG_ 616 US_Links_02_Pos_Y "y-Koordinate durch Mehrfachmessung bestätigter Messpunkt 02 links im FZG-Koordinatensystem";
CM_ SG_ 616 US_Links_02_Valid "Valid Flag Messpunkt 02 links";
CM_ SG_ 616 US_Nichtverfuegbarkeit_HLS "Nichtverfügbarkeit der hinteren linken seitlichen US-Sensorik";
CM_ SG_ 616 US_Nichtverfuegbarkeit_HRS "Nichtverfügbarkeit der hinteren rechten seitlichen US-Sensorik";
CM_ SG_ 616 US_Nichtverfuegbarkeit_VLS "Nichtverfügbarkeit der vorderen linken seitlichen US-Sensorik";
CM_ SG_ 616 US_Nichtverfuegbarkeit_VRS "Nichtverfügbarkeit der vorderen rechten seitlichen US-Sensorik";
CM_ SG_ 616 US_QAbstand_HLS "Abstand Rohwert der hinteren linken seitlichen US-Sensorik";
CM_ SG_ 616 US_QAbstand_HRS "Abstand Rohwert der hinteren rechten seitlichen US-Sensorik";
CM_ SG_ 616 US_QAbstand_VLS "Abstand Rohwert der vorderen linken seitlichen US-Sensorik";
CM_ SG_ 616 US_QAbstand_VRS "Abstand Rohwert der vorderen rechten seitlichen US-Sensorik";
CM_ SG_ 616 US_Rechts_01_Pos_X "x-Koordinate durch Mehrfachmessung bestätigter Messpunkt 01 rechts im FZG-Koordinatensystem";
CM_ SG_ 616 US_Rechts_01_Pos_Y "y-Koordinate durch Mehrfachmessung bestätigter Messpunkt 01 rechts im FZG-Koordinatensystem";
CM_ SG_ 616 US_Rechts_01_Valid "Valid Flag Messpunkt 01 rechts";
CM_ SG_ 616 US_Rechts_02_Pos_X "x-Koordinate durch Mehrfachmessung bestätigter Messpunkt 02 rechts im FZG-Koordinatensystem";
CM_ SG_ 616 US_Rechts_02_Pos_Y "y-Koordinate durch Mehrfachmessung bestätigter Messpunkt 02 rechts im FZG-Koordinatensystem";
CM_ SG_ 616 US_Rechts_02_Valid "Valid Flag Messpunkt 02 rechts";

CM_ SG_ 896 APS_Master_Sendestatus "Gibt den Sendestatus der Botschaft APS_Master an (notwendig für IL-Unterstützung)";
CM_ SG_ 896 US_ACC_CRC "Ab MQB und MLBevo:
'Berechnung siehe Lastenheft 'End-to-End Kommunikationsabsicherung''

Endwerte siehe Begleitdokument 'S-PDU Kennungsfolgen'";
CM_ SG_ 896 US_blindness_detected "US erkennt selbständig eigene Blindheit durch äußere Einflüsse.";
CM_ SG_ 896 US_Freie_Weglaenge_Front "US_Freie Weglaenge vor dem Fahrzeug - lenkwinkelabhängig. Die freie Weglänge kann dabei durch Hindernisse oder den maximalen Sichtbereich beschränkt sein. Siehe Signal US_Freie_Weglaenge_Front_Typ";
CM_ SG_ 896 US_Freie_Weglaenge_Front_Typ "Beschreibt die Begrenzung der freien Weglänge vor dem Fahrzeug. Gehört somit zum Signal US_Freie_Weglaenge_Front. Die freie Weglänge kann bei einem gemessenen Objekt enden oder bei der maximalen Sensorreichweite.";
CM_ SG_ 896 US_Freie_Weglaenge_Heck "Gibt lenkwinkelabhängig einen Abstand hinter dem Fahrzeug aus. Dabei kann der Abstand entweder den Abstand zu einem Hindernis oder den maximalen Sichtbereich darstellen. Zur Unterscheidung Hindernis oder maximaler Sichtbereich siehe Signal US_Freie_Weglae";
CM_ SG_ 896 US_Freie_Weglaenge_Heck_Typ "US_Freie_Weglaenge_Typ gibt an, ob es sich bei dem Signal US_Freie_Weglaenge_Heck um ein gemessenes Objekt handelt oder um die maximale Sensorreichweite. Gehört somit zum Signal US_Freie_Weglaenge_Front";
CM_ SG_ 896 US_Freisicht_nio "Blindheitserkennung
Nach KL15-Ein konnte Freisichtprüfung noch nicht erfüllt werden";
CM_ SG_ 896 US_relevante_Nichtverfuegbarkeit "US erkennt eine Nichtverfuegbarkeit, die Objektdetektion im Frontbereich betreffend, ohne FSP-Eintrag";
CM_ SG_ 896 US_relevanter_Fehler "US erkennt einen Fehler, die Objektdetektion im Frontbereich betreffend, mit FSP-Eintrag.";
CM_ SG_ 896 US_Sende_Modus "US=Ultraschall
US_SendeModus:
0x0: keine für das ACC-SG relevanten Abstandswerte werden gesendet
0x1: 4K ext. range, 10 Signalwege verfügbar ('4m')
0x2: 4K norm. range, 10 Signalwege verfügbar ('2m')
0x3: 6K ext. range, 16 Signalwege verfügbar ('4m')";
CM_ SG_ 896 US_Sende_Modus_hinten "US=Ultraschall
US_Sende_Modus_hinten:
0x0: keine für das ACC-SG relevanten Abstandswerte werden gesendet
0x1....0x4: frei
0x5: 2-K. ext. range (PLA), 2 Signalwege verfügbar ('4m')
0x6: Modeumschaltung (ext -> norm oder norm -> ext)
0x7: Blindheitspr";

CM_ SG_ 345 ARA_Anf_Meldungen "Anforderung der Meldungen:
0 - Keine Meldung
1-127 niederprio. Meldungen
128-255 hochprio. Meldungen";
CM_ SG_ 345 ARA_Knickwinkel_Ist "Gibt den aktuellen Knickwinkel zwischen Anhänger und Fahrzeug wieder";
CM_ SG_ 345 ARA_Knickwinkel_Komfort "Knickwinkelgrenze bis zu der, bei maximalem Lenkeinschlag, eine sofortige gerade Rückwärtsfahrt möglich ist.";
CM_ SG_ 345 ARA_Knickwinkel_Konfidenz "irregular trailer angle area value for HMI display";
CM_ SG_ 345 ARA_Knickwinkel_Max "Gibt den maximalen ausregelbaren Knickwinkel zwischen Anhänger und Fahrzeug wieder.";
CM_ SG_ 345 ARA_Knickwinkel_Soll "Vom Fahrer vorgegebener Knickwinkel.";
CM_ SG_ 345 ARA_Modus "Regelmodus ARA für Kombidarstellung";
CM_ SG_ 345 ARA_Sensor_Aktivierung "activation  of ARA IP (image processing)";
CM_ SG_ 345 ARA_Status "Status of ARA Controller";

CM_ SG_ 2527679661 AWV_AW_Abstand "Signal dient zur Anzeige des Abstands im Kombi.";
CM_ SG_ 2527679661 AWV_AW_Texte "Signal zur Ansteuerung von Fahrer- und Warnhinweisen des Abstandswarners im Mitteldisplay";
CM_ SG_ 2527679661 AWV_AW_Texte_Zusatzanzeige "Signal zur Ansteuerung von Fahrer- und Warnhinweisen des Abstandswarners im Mitteldisplay";
CM_ SG_ 2527679661 AWV_AW_Zeitluecke "Anzeige der aktuellen Zeitluecke zum vorausfahrenden Fahrzeug (AW == Abstandswarner)";
CM_ SG_ 2527679661 AWV_Einstellung_System_FSG "Signal zur Realisierung des BAP-Koordiantors";
CM_ SG_ 2527679661 AWV_Einstellung_Warnung_FSG "Signal zur Realisierung des BAP-Koordinators";
CM_ SG_ 2527679661 AWV_KA_Konfiguration "Systemstatus Bedienung vom Kreuzungsassistent zum PaCo.";
CM_ SG_ 2527679661 AWV_KA_ObjektFront "Anforderung der MIB Parkenanzeige vom Kreuzungsassistent zum PaCo.";
CM_ SG_ 2527679661 AWV_Kamera_Objekt_ID "Kamera Objekt-ID des AWV-Zielobjekts";
CM_ SG_ 2527679661 AWV_LED_Leiste "Ansteuerung LED Warnleiste";
CM_ SG_ 2527679661 AWV_Priowarnung "Priorisierung der AWV-Warnung über die Spurverlassensanzeige des HCA";
CM_ SG_ 2527679661 AWV_Status_Anzeige "Signal zur Realisierung des BAP-Koordiantors
Signal identisch zu AWV_BAP_Status 
Kl15 aus: nicht bereitgestellt.";
CM_ SG_ 2527679661 AWV_Texte "Hinweisanzeige im Kombi 'Hauptdisplay'";
CM_ SG_ 2527679661 AWV_Warnlevel "Warnlevel der Funktion Anhaltewegverkürzung";
CM_ SG_ 2527679661 AWV_Warnung "Hinweisanzeige im Kombi 'Hauptdisplay'";
CM_ SG_ 2527679661 AWV_Warnung_Richtung "Zusätzliche Richtungsanzeige zum Signal AWV_Warnung für die Darstellung im Smartlight und HUD.";
CM_ SG_ 2527679661 WBA_Warnblinken "Ansteuerung des Warnblinkers für die Funktion Warnen, Bremsen, Ausweichen";

CM_ SG_ 219 AWV_03_BZ "4bit Botschaftszähler, wird mit jeder Sendebotschaft inkrementiert";
CM_ SG_ 219 AWV_03_CRC "Für MLB:
Berechnung siehe Lastenheft 'Kommunikationsabsicherung für FlexRay und CAN'
Ab MQB und MLBevo:
Berechnung siehe Lastenheft 'End-to-End Kommunikationsabsicherung'

Endwerte siehe Begleitdokument 'S-PDU Kennungsfolgen'";
CM_ SG_ 219 AWV_Anf_Prefill "Anforderung an VZM, dass die Prefill-Funktion aktiviert werden soll.";
CM_ SG_ 219 AWV_Eingriff_Sendeart "Umschalten zwischen langsamem und schnellem Zyklus der AWV_Eingriffs-Botschaft";
CM_ SG_ 219 AWV_Fahrerbremswunsch_erf "Anforderung an das ESC, die Verzögerungsdynamik höher als die Auswertung des Fahrerbremswunsch zu priorisieren.";
CM_ SG_ 219 AWV_HBA_Param "Anforderung an HBA zur Anpassung der HBA-Auslöseschwelle.";
CM_ SG_ 219 AWV_QFK_AnfStat "Statusinformationen des Anforderers";
CM_ SG_ 219 AWV_QFK_Art1 "Auswahlsignal für AWV_QFK_Signal1";
CM_ SG_ 219 AWV_QFK_Art2 "Auswahlsignal für AWV_QFK_Signal2";
CM_ SG_ 219 AWV_QFK_KrSoll "Krümmungsanforderung";
CM_ SG_ 219 AWV_QFK_KrSoll_VZ "Vorzeichen für die Krümmungsanforderung";
CM_ SG_ 219 AWV_QFK_KruemmSoll "Krümmungsanforderung";
CM_ SG_ 219 AWV_QFK_KruemmSoll_VZ "Vorzeichen für die Krümmungsanforderung";
CM_ SG_ 219 AWV_QFK_Signal1 "Inhalt AWV_QFK_Signal1 wird durch das Signal AWV_QFK_Art1 gesteuert.
Nähere Informationen im LAH Querführungskoordinator.";
CM_ SG_ 219 AWV_QFK_Signal2 "Inhalt AWV_QFK_Signal2 wird durch das Signal AWV_QFK_Art2 gesteuert.
Nähere Informationen im LAH Querführungskoordinator.";
CM_ SG_ 219 AWV_QFK_Spuerb "Spürbarkeitsanforderung. Legt fest, mit welchem Handmoment die angeforderte Krümmung überlenkt werden muss.";
CM_ SG_ 219 AWV_Ruckprofil "Anforderung an VZM, welcher Ruck aus einer Auswahl von 3 verschiedenen Ruckprofilen verwendet werden soll.";
CM_ SG_ 219 AWV_Status_AWU "Signal für die Erfüllung der GSR2 EDR Anforderungen bezüglich der Unterfunktion AWU des Elementes CSF.";
CM_ SG_ 219 AWV_Time_to_brake "Zeit in Millisekunden bs zu einer AWV Verzögerungsanforderung (ATB oder ZBR)";
CM_ SG_ 219 AWV_Time_to_collision "Prädizierter Aufprallzeitpunkt des relevanten Objektes aus der AWV-Funktion";
CM_ SG_ 219 AWV_Timestamp_TTC "Messzeitpunkt der WBA Daten";
CM_ SG_ 219 AWV_Verz_Anf "Verzögerungsanforderung der Funktionen Zielbremsung und Teilbremsung an das VZM";
CM_ SG_ 219 AWV_Verz_Anf_ASIL "Definiert das Anforderungssignal von FKT an VZM mit dem dynamischen ASIL";
CM_ SG_ 219 AWV_Verz_Freigabe "Freigabe-Bit der AWV Verzögerung an das VZM";
CM_ SG_ 219 AWV_Zielobjekttyp "Definiert den Zielobjekttyp an VZM";
CM_ SG_ 219 PCF_Freigabe "Freigabe der Funktion PreCrash-Front";
CM_ SG_ 219 SDF_PSF_CU_Status "Kollisionsvermeidbarkeit";
CM_ SG_ 219 SDF_PSF_CW "Kollisionswahrscheinlichkeit";
CM_ SG_ 219 SDF_PSF_Fahrer_aktiv "Fahreraktivität";
CM_ SG_ 219 SDF_PSF_Guete "Guete des Objektes

Umsetzung ab MQB37W Baseline: 
Wert 0: Initialwert;  Wert 1 ('Modellgüte n.i.O_kein_Plausi') wird nicht mehr bedatet bei vorhandenem Crashobjekt. Es werden nur 2 und 3 bedatet. Somit ist der Informationsgehalt dieses Signales nur de";
CM_ SG_ 219 SDF_PSF_Kollisionsueberdeckung "Kollisionsueberdeckung in y-Richtung";
CM_ SG_ 219 SDF_PSF_Objektstatus "Objektstatus";
CM_ SG_ 219 SDF_PSF_Time_To_Collision "Zeit bis zur Kollision";
CM_ SG_ 219 SDF_PSF_v_rel "Prädizierte Aufprallgeschwindigkeit";
CM_ SG_ 219 SOK_AWV_03_Signatur "Signatur im Rahmen der durch SOK geschützen Broadcast-Kommunikation

Geschützte Funktion: Anhaltwegverkürzung 
Geschützte Botschaft: AWV_03";

CM_ SG_ 2536728320 BAP_REM2_ASG_01_Header "REM Anzeigesteuergeraet
(REM=road experience management)";

CM_ SG_ 2536728336 BAP_REM2_FSG_01_Header "REM Funktionssteuergeraet
(REM=road experience management)";

CM_ SG_ 2536728337 BAP_REM2_FSG_02_Header "REM Funktionssteuergeraet
(REM=road experience management) 
fast signal";

CM_ SG_ 2536725248 BAP_REM_ASG_01_Header "REM Anzeigesteuergeraet
(REM=road experience management)";

CM_ SG_ 2536725249 BAP_REM_ASG_02_Header "REM Anzeigesteuergeraet
(REM=road experience management)";

CM_ SG_ 2536725264 BAP_REM_FSG_01_Header "REM Funktionssteuergeraet
(REM=road experience management)";

CM_ SG_ 2536725265 BAP_REM_FSG_02_Header "REM Funktionssteuergeraet
(REM=road experience management) 
fast signal";

CM_ SG_ 2536726273 BAP_TPA_ASG_02_Header "Parktrajektorie Anzeigesteuergerät";

CM_ SG_ 2536726288 BAP_TPA_FSG_01_Header "Parktrajektorie Funktionssteuergeraet";

CM_ SG_ 870 Blinken_li_Fzg_Takt "Fzg-Takt Blinker links

";
CM_ SG_ 870 Blinken_li_Kombi_Takt "Kombi-Takt Blinker links

";
CM_ SG_ 870 Blinken_re_Fzg_Takt "Fzg-Takt Blinker rechts

";
CM_ SG_ 870 Blinken_re_Kombi_Takt "Kombi-Takt Blinker rechts

";
CM_ SG_ 870 Blinkmodi_02_BZ "4bit Botschaftszähler, wird mit jeder Sendebotschaft inkrementiert";
CM_ SG_ 870 Blinkmodi_02_CRC "Für MLB:
Berechnung siehe Lastenheft 'Kommunikationsabsicherung für FlexRay und CAN'
Ab MQB und MLBevo:
Berechnung siehe Lastenheft 'End-to-End Kommunikationsabsicherung'

Endwerte siehe Begleitdokument 'S-PDU Kennungsfolgen'";
CM_ SG_ 870 BM_Autobahn "Status Autobahnblinken
";
CM_ SG_ 870 BM_Crash "Status Crashblinken
";
CM_ SG_ 870 BM_DWA_Alarm "Status DWA-Alarmblinken
";
CM_ SG_ 870 BM_DWA_ein "Status Quittierungsblinken DWA";
CM_ SG_ 870 BM_GDO "Blinken bei UGDO anlernen

";
CM_ SG_ 870 BM_HD_Oeffnung_angelernt "HD_Rueckmeld_prog eine Blinkerquittierung wird beim BCM2 angefordert.
Wenn die Geschwindigkeit kleiner einer vorgegebenen Schwelle (default 2km/h) ist wird das Signal BM_HD_Öffnung_angelernt versendet und die Blinkerquittierung ausgelöst";
CM_ SG_ 870 BM_links "Richtungsblinken links

";
CM_ SG_ 870 BM_NBA_n_codiert_n_aktiv "Notbremsanzeige nicht codiert/nicht aktiv (Fehler)";
CM_ SG_ 870 BM_NBA_Status "Notbremsanzeige Status nicht aktiv / BRL Dunkelphase / BRL Hellphase";
CM_ SG_ 870 BM_Not_Bremsung "Das Signal BM_Not_Bremsung  zeigt an,  ob ein Warnblinken aufgrund einer vom Bremssystem signalisierten Notbremsung aktiv ist.";
CM_ SG_ 870 BM_Panik "Panikblinken
";
CM_ SG_ 870 BM_PiloPa "Quittierungsblinken bei pilotierten Parkvorgängen";
CM_ SG_ 870 BM_Recas "Blinkermodus RECAS  (RearEndCollisionAlertSignal)";
CM_ SG_ 870 BM_rechts "Richtungsblinken rechts

";
CM_ SG_ 870 BM_Rollenmodus_Blinken "Das Signal wird statisch gesetzt, wenn die Blinkerart Rollenmodus_Blinken aktiv ist.";
CM_ SG_ 870 BM_Taxi_Notalarm "Blinken bei Taxi-Not-Alarm

";
CM_ SG_ 870 BM_Telematik "Telematikblinken
";
CM_ SG_ 870 BM_Telematik_Abbruchgrund "Gibt bei erwaretem aber ausbleibendem Flankenanstieg der BM_Telematik an wieso die Ausführung verhindert wurde. Bei Flankenabfall der BM_Telematik wird angegeben wieso die Ausführung beendet wurde.

Bei nicht bereitem Sender soll 'init' gesendet werden,";
CM_ SG_ 870 BM_Warnblinken "Warnblinken

";
CM_ SG_ 870 BM_WBT_Beleuchtung "Aktivierung Warnblinktasterfunktionsbeleuchtung
Warnblinktasterfunktionsbeleuchtung soll aktiviert werden (statisch auf 1)";
CM_ SG_ 870 BM_Wischblinken "Blinkermodus Wisch_Blinken";
CM_ SG_ 870 BM_ZV_auf "Blinken bei ZV auf

";
CM_ SG_ 870 BM_ZV_zu "Blinken bei ZV zu

";
CM_ SG_ 870 DWA_Alarmquelle "Signalisiert den Auslösegrund der DWA";
CM_ SG_ 870 SAL_RHP_Blinken_Status "SAL Rückmeldung Rush Hour Pilot Blinker-Status an Funktion RHP";
CM_ SG_ 870 SAL_RHP_Warnblinken "Rückkanal des durch RHP angeforderten Warnblinken";
CM_ SG_ 870 SAL_TA_Blinken_Status "SAL RückmeldungTravelAssist Blinker-Status an Funktion TA (MFK)";

BA_DEF_  "DBName" STRING;
BA_DEF_  "GenNWMApBusSleep" STRING;
BA_DEF_  "GenNWMApCanNormal" STRING;
BA_DEF_  "GenNWMApCanOff" STRING;
BA_DEF_  "GenNWMApCanOn" STRING;
BA_DEF_  "GenNWMApCanSleep" STRING;
BA_DEF_  "GenNWMApCanWakeUp" STRING;
BA_DEF_  "GenNWMGotoMode_Awake" STRING;
BA_DEF_  "GenNWMGotoMode_BusSleep" STRING;
BA_DEF_  "GenNWMSleepTime" INT 0 1000000;
BA_DEF_  "GenNWMTalkNM" STRING;
BA_DEF_  "Manufacturer" STRING;
BA_DEF_  "NmhBaseAddress" HEX 0 536870911;
BA_DEF_  "NmhMessageCount" INT 0 1024;
BA_DEF_  "NmType" STRING;
BA_DEF_  "VAGTP20_SetupMessageCount" INT 0 255;
BA_DEF_  "VAGTP20_SetupStartAddress" HEX 0 2047;
BA_DEF_  "VersionDay" INT 1 31;
BA_DEF_  "VersionMonth" INT 1 12;
BA_DEF_  "VersionWeek" INT 1 52;
BA_DEF_  "VersionYear" INT 0 99;
BA_DEF_  "VersionNumber" INT 0 65535;
BA_DEF_  "BusType" STRING;
BA_DEF_  "Baudrate" INT 1 1000000;
BA_DEF_  "BaudrateCANFD" INT 1 16000000;
BA_DEF_  "NmhTimeoutTimer" INT 0 65535;
BA_DEF_  "NmhWaitBusSleepTimer" INT 0 65535;
BA_DEF_  "NmhPrepareBusSleepTimer" INT 0 65535;
BA_DEF_  "NmhLongTimer" INT 0 65535;
BA_DEF_  "NmhNStart" INT 0 255;
BA_DEF_ BU_  "GenNodAutoGenDsp" ENUM "No", "Yes";
BA_DEF_ BU_  "GenNodAutoGenSnd" ENUM "No", "Yes";
BA_DEF_ BU_  "GenNodSleepTime" INT 0 1000000;
BA_DEF_ BU_  "ILUsed" ENUM "No", "Yes";
BA_DEF_ BU_  "ECUVariantDefault" ENUM "No", "Yes";
BA_DEF_ BU_  "ECUVariantGroup" STRING;
BA_DEF_ BU_  "NodeLayerModules" STRING;
BA_DEF_ BU_  "NmhNode" ENUM "No", "Yes";
BA_DEF_ BU_  "NmNode" ENUM "No", "Yes";
BA_DEF_ BU_  "SamplePointMin" FLOAT 50.0 99.9;
BA_DEF_ BU_  "SamplePointMax" FLOAT 50.0 99.9;
BA_DEF_ BU_  "SyncJumpWidthMin" FLOAT 0.0 50.0;
BA_DEF_ BU_  "SyncJumpWidthMax" FLOAT 0.0 50.0;
BA_DEF_ BU_  "SyncJumpWidthCANFDMin" FLOAT 0.0 50.0;
BA_DEF_ BU_  "SyncJumpWidthCANFDMax" FLOAT 0.0 50.0;
BA_DEF_ BU_  "SamplePointCANFDMin" FLOAT 50.0 99.9;
BA_DEF_ BU_  "SamplePointCANFDMax" FLOAT 50.0 99.9;
BA_DEF_ BU_  "SSPOffsetCANFDMin" FLOAT 50.0 99.9;
BA_DEF_ BU_  "SSPOffsetCANFDMax" FLOAT 50.0 99.9;
BA_DEF_ BU_  "TimeQuantaMin" INT 4 257;
BA_DEF_ BU_  "TimeQuantaMax" INT 4 257;
BA_DEF_ BU_  "TimeQuantaCANFDMin" INT 4 257;
BA_DEF_ BU_  "TimeQuantaCANFDMax" INT 4 257;
BA_DEF_REL_ BU_SG_REL_  "GenSigTimeoutTime" INT 0 65535;
BA_DEF_ BO_  "DiagRequest" ENUM "No", "Yes";
BA_DEF_ BO_  "DiagResponse" ENUM "No", "Yes";
BA_DEF_ BO_  "DiagState" ENUM "No", "Yes";
BA_DEF_ BO_  "GenMsgChkConstant" HEX 0 4095;
BA_DEF_ BO_  "GenMsgCycleTime" INT 0 65535;
BA_DEF_ BO_  "GenMsgCycleTimeFast" INT 0 65535;
BA_DEF_ BO_  "GenMsgDelayTime" INT 0 100000;
BA_DEF_ BO_  "GenMsgILSupport" ENUM "No", "Yes";
BA_DEF_ BO_  "GenMsgNrOfRepetition" INT 0 100;
BA_DEF_ BO_  "GenMsgPDUConstants" STRING;
BA_DEF_ BO_  "GenMsgSendType" ENUM "Cyclic", "not_used", "not_used", "not_used", "not_used", "not_used", "not_used", "IfActive", "NoMsgSendType";
BA_DEF_ BO_  "GenMsgStartDelayTime" INT 0 100000;
BA_DEF_ BO_  "NmMessage" ENUM "No", "Yes";
BA_DEF_ BO_  "NmhMessage" ENUM "No", "Yes";
BA_DEF_ BO_  "MsgType" ENUM "Application", "NM ", "NMH", "TP2.0", "ISO-TP ", "BAP", "EID", "KS", "XCP_PRE_CONFIGURED", "XCP_RUNTIME_CONFIGURED";
BA_DEF_ BO_  "VAGTP20_API" HEX 0 255;
BA_DEF_ BO_  "VAGTP20_DynConnection" ENUM "No", "Yes";
BA_DEF_ BO_  "VAGTP20_DynSetup" ENUM "No", "Yes";
BA_DEF_ BO_  "VAGTP20_StatConnection" ENUM "No", "Yes";
BA_DEF_ BO_  "CANFD_BRS" ENUM "0", "1";
BA_DEF_ BO_  "VFrameFormat" ENUM "StandardCAN", "ExtendedCAN", "reserved", "reserved", "reserved", "reserved", "reserved", "reserved", "reserved", "reserved", "reserved", "reserved", "reserved", "reserved", "StandardCAN_FD", "ExtendedCAN_FD";
BA_DEF_ SG_  "GenSigActiveRepetitions" INT -2147483648 2147483647;
BA_DEF_ SG_  "GenSigInactiveValue" INT -2147483648 2147483647;
BA_DEF_ SG_  "GenSigSendType" ENUM "Cyclic", "OnWrite", "OnWriteWithRepetition", "OnChange", "OnChangeWithRepetition", "IfActive", "IfActiveWithRepetition", "NoSigSendType", "OnChangeAndIfActive", "OnChangeAndIfActiveWithRepetition";
BA_DEF_ SG_  "GenSigStartValue" INT -2147483648 2147483647;
BA_DEF_ SG_  "NWM-WakeupAllowed" ENUM "No", "Yes";
BA_DEF_ SG_  "GenSigFuncType" ENUM "NoFunction", "MsgCounter", "CRC-8", "XOR", "XOR-2", "DatedBit", "SW-Kl15", "CHK", "Constant", "Protocol", "CRC-8-SAE_J1850", "CRC-32", "DataLength", "DataID", "MsgCounter16", "SOK-Signatur", "Cluster";
BA_DEF_ SG_  "GenSigSwitchedByIgnition" ENUM "No", "Yes";
BA_DEF_ SG_  "Fehlerwert" HEX 0 2147483647;
BA_DEF_ SG_  "GenSigMissingSourceValue" HEX 0 2147483647;
BA_DEF_DEF_  "DBName" "";
BA_DEF_DEF_  "GenNWMApBusSleep" "";
BA_DEF_DEF_  "GenNWMApCanNormal" "";
BA_DEF_DEF_  "GenNWMApCanOff" "";
BA_DEF_DEF_  "GenNWMApCanOn" "";
BA_DEF_DEF_  "GenNWMApCanSleep" "";
BA_DEF_DEF_  "GenNWMApCanWakeUp" "";
BA_DEF_DEF_  "GenNWMGotoMode_Awake" "";
BA_DEF_DEF_  "GenNWMGotoMode_BusSleep" "";
BA_DEF_DEF_  "GenNWMSleepTime" 0;
BA_DEF_DEF_  "GenNWMTalkNM" "";
BA_DEF_DEF_  "Manufacturer" "";
BA_DEF_DEF_  "NmhBaseAddress" 0;
BA_DEF_DEF_  "NmhMessageCount" 1;
BA_DEF_DEF_  "NmType" "None";
BA_DEF_DEF_  "VAGTP20_SetupMessageCount" 0;
BA_DEF_DEF_  "VAGTP20_SetupStartAddress" 0;
BA_DEF_DEF_  "VersionDay" 27;
BA_DEF_DEF_  "VersionMonth" 7;
BA_DEF_DEF_  "VersionWeek" 30;
BA_DEF_DEF_  "VersionYear" 23;
BA_DEF_DEF_  "VersionNumber" 0;
BA_DEF_DEF_  "BusType" "";
BA_DEF_DEF_  "Baudrate" 500000;
BA_DEF_DEF_  "BaudrateCANFD" 2000000;
BA_DEF_DEF_  "NmhTimeoutTimer" 0;
BA_DEF_DEF_  "NmhWaitBusSleepTimer" 0;
BA_DEF_DEF_  "NmhPrepareBusSleepTimer" 0;
BA_DEF_DEF_  "NmhLongTimer" 0;
BA_DEF_DEF_  "NmhNStart" 0;
BA_DEF_DEF_  "GenNodAutoGenDsp" "Yes";
BA_DEF_DEF_  "GenNodAutoGenSnd" "Yes";
BA_DEF_DEF_  "GenNodSleepTime" 0;
BA_DEF_DEF_  "ILUsed" "Yes";
BA_DEF_DEF_  "ECUVariantDefault" "Yes";
BA_DEF_DEF_  "ECUVariantGroup" "";
BA_DEF_DEF_  "NodeLayerModules" "";
BA_DEF_DEF_  "NmhNode" "Yes";
BA_DEF_DEF_  "NmNode" "No";
BA_DEF_DEF_  "SamplePointMin" 75;
BA_DEF_DEF_  "SamplePointMax" 75;
BA_DEF_DEF_  "SyncJumpWidthMin" 50;
BA_DEF_DEF_  "SyncJumpWidthMax" 50;
BA_DEF_DEF_  "SyncJumpWidthCANFDMin" 50;
BA_DEF_DEF_  "SyncJumpWidthCANFDMax" 50;
BA_DEF_DEF_  "SamplePointCANFDMin" 75;
BA_DEF_DEF_  "SamplePointCANFDMax" 75;
BA_DEF_DEF_  "SSPOffsetCANFDMin" 75;
BA_DEF_DEF_  "SSPOffsetCANFDMax" 75;
BA_DEF_DEF_  "TimeQuantaMin" 160;
BA_DEF_DEF_  "TimeQuantaMax" 160;
BA_DEF_DEF_  "TimeQuantaCANFDMin" 40;
BA_DEF_DEF_  "TimeQuantaCANFDMax" 40;
BA_DEF_DEF_REL_  "GenSigTimeoutTime" 0;
BA_DEF_DEF_  "DiagRequest" "No";
BA_DEF_DEF_  "DiagResponse" "No";
BA_DEF_DEF_  "DiagState" "No";
BA_DEF_DEF_  "GenMsgChkConstant" 0;
BA_DEF_DEF_  "GenMsgCycleTime" 0;
BA_DEF_DEF_  "GenMsgCycleTimeFast" 0;
BA_DEF_DEF_  "GenMsgDelayTime" 0;
BA_DEF_DEF_  "GenMsgILSupport" "No";
BA_DEF_DEF_  "GenMsgNrOfRepetition" 0;
BA_DEF_DEF_  "GenMsgPDUConstants" "";
BA_DEF_DEF_  "GenMsgSendType" "NoMsgSendType";
BA_DEF_DEF_  "GenMsgStartDelayTime" 0;
BA_DEF_DEF_  "NmMessage" "No";
BA_DEF_DEF_  "NmhMessage" "No";
BA_DEF_DEF_  "MsgType" "Application";
BA_DEF_DEF_  "VAGTP20_API" 0;
BA_DEF_DEF_  "VAGTP20_DynConnection" "No";
BA_DEF_DEF_  "VAGTP20_DynSetup" "No";
BA_DEF_DEF_  "VAGTP20_StatConnection" "No";
BA_DEF_DEF_  "CANFD_BRS" "1";
BA_DEF_DEF_  "VFrameFormat" "StandardCAN";
BA_DEF_DEF_  "GenSigActiveRepetitions" 0;
BA_DEF_DEF_  "GenSigInactiveValue" 0;
BA_DEF_DEF_  "GenSigSendType" "NoSigSendType";
BA_DEF_DEF_  "GenSigStartValue" 0;
BA_DEF_DEF_  "NWM-WakeupAllowed" "No";
BA_DEF_DEF_  "GenSigFuncType" "NoFunction";
BA_DEF_DEF_  "GenSigSwitchedByIgnition" "Yes";
BA_DEF_DEF_  "Fehlerwert" 0;
BA_DEF_DEF_  "GenSigMissingSourceValue" 0;
BA_  "DBName" "E3V_FASCANFD1";
BA_  "GenNWMApBusSleep" "NMIndNetSDN()";
BA_  "GenNWMApCanNormal" "apCanNormal()";
BA_  "GenNWMApCanOff" "NMIndnetOff()";
BA_  "GenNWMApCanOn" "NMIndnetOn()";
BA_  "GenNWMApCanSleep" "apCanSleep()";
BA_  "GenNWMApCanWakeUp" "apCanWakeUp()";
BA_  "GenNWMGotoMode_Awake" "Nmh_ReqNetOn()";
BA_  "GenNWMGotoMode_BusSleep" "Nmh_ReqNetOff()";
BA_  "GenNWMSleepTime" 4000;
BA_  "GenNWMTalkNM" "Nmh_ReqNetOn()";
BA_  "Manufacturer" "VAG";
BA_  "NmhBaseAddress" 452984832;
BA_  "NmhMessageCount" 1024;
BA_  "NmType" "NM-High";
BA_  "VAGTP20_SetupMessageCount" 128;
BA_  "VAGTP20_SetupStartAddress" 512;
BA_  "VersionNumber" 401;
BA_  "BusType" "CAN FD";
BA_  "NmhTimeoutTimer" 1000;
BA_  "NmhWaitBusSleepTimer" 750;
BA_  "NmhPrepareBusSleepTimer" 500;
BA_  "NmhLongTimer" 200;
BA_  "NmhNStart" 20;
BA_ "GenNodSleepTime" BU_ BAP_Tester 4000;
BA_ "ECUVariantGroup" BU_ BAP_Tester "BAP";
BA_ "NmhNode" BU_ BAP_Tester 0;
BA_ "SamplePointMin" BU_ BAP_Tester 80;
BA_ "SamplePointMax" BU_ BAP_Tester 80;
BA_ "SyncJumpWidthMin" BU_ BAP_Tester 16;
BA_ "SyncJumpWidthMax" BU_ BAP_Tester 16;
BA_ "SyncJumpWidthCANFDMin" BU_ BAP_Tester 6;
BA_ "SyncJumpWidthCANFDMax" BU_ BAP_Tester 6;
BA_ "SamplePointCANFDMin" BU_ BAP_Tester 70;
BA_ "SamplePointCANFDMax" BU_ BAP_Tester 70;
BA_ "SSPOffsetCANFDMin" BU_ BAP_Tester 70;
BA_ "SSPOffsetCANFDMax" BU_ BAP_Tester 70;
BA_ "TimeQuantaMin" BU_ BAP_Tester 80;
BA_ "TimeQuantaMax" BU_ BAP_Tester 80;
BA_ "TimeQuantaCANFDMin" BU_ BAP_Tester 20;
BA_ "TimeQuantaCANFDMax" BU_ BAP_Tester 20;
BA_ "GenNodSleepTime" BU_ FASFrontradar 4000;
BA_ "ECUVariantGroup" BU_ FASFrontradar "ACC";
BA_ "NodeLayerModules" BU_ FASFrontradar "NMHigh.DLL";
BA_ "SamplePointMin" BU_ FASFrontradar 80;
BA_ "SamplePointMax" BU_ FASFrontradar 80;
BA_ "SyncJumpWidthMin" BU_ FASFrontradar 16;
BA_ "SyncJumpWidthMax" BU_ FASFrontradar 16;
BA_ "SyncJumpWidthCANFDMin" BU_ FASFrontradar 6;
BA_ "SyncJumpWidthCANFDMax" BU_ FASFrontradar 6;
BA_ "SamplePointCANFDMin" BU_ FASFrontradar 70;
BA_ "SamplePointCANFDMax" BU_ FASFrontradar 70;
BA_ "SSPOffsetCANFDMin" BU_ FASFrontradar 70;
BA_ "SSPOffsetCANFDMax" BU_ FASFrontradar 70;
BA_ "TimeQuantaMin" BU_ FASFrontradar 80;
BA_ "TimeQuantaMax" BU_ FASFrontradar 80;
BA_ "TimeQuantaCANFDMin" BU_ FASFrontradar 20;
BA_ "TimeQuantaCANFDMax" BU_ FASFrontradar 20;
BA_ "GenNodSleepTime" BU_ ICAS1_X_Gateway 4000;
BA_ "ECUVariantGroup" BU_ ICAS1_X_Gateway "Gateway";
BA_ "NodeLayerModules" BU_ ICAS1_X_Gateway "NMHigh.DLL";
BA_ "SamplePointMin" BU_ ICAS1_X_Gateway 80;
BA_ "SamplePointMax" BU_ ICAS1_X_Gateway 80;
BA_ "SyncJumpWidthMin" BU_ ICAS1_X_Gateway 16;
BA_ "SyncJumpWidthMax" BU_ ICAS1_X_Gateway 16;
BA_ "SyncJumpWidthCANFDMin" BU_ ICAS1_X_Gateway 6;
BA_ "SyncJumpWidthCANFDMax" BU_ ICAS1_X_Gateway 6;
BA_ "SamplePointCANFDMin" BU_ ICAS1_X_Gateway 70;
BA_ "SamplePointCANFDMax" BU_ ICAS1_X_Gateway 70;
BA_ "SSPOffsetCANFDMin" BU_ ICAS1_X_Gateway 70;
BA_ "SSPOffsetCANFDMax" BU_ ICAS1_X_Gateway 70;
BA_ "TimeQuantaMin" BU_ ICAS1_X_Gateway 80;
BA_ "TimeQuantaMax" BU_ ICAS1_X_Gateway 80;
BA_ "TimeQuantaCANFDMin" BU_ ICAS1_X_Gateway 20;
BA_ "TimeQuantaCANFDMax" BU_ ICAS1_X_Gateway 20;
BA_ "GenNodSleepTime" BU_ MFK 4000;
BA_ "ECUVariantGroup" BU_ MFK "Frontsensorik";
BA_ "NodeLayerModules" BU_ MFK "NMHigh.DLL";
BA_ "SamplePointMin" BU_ MFK 80;
BA_ "SamplePointMax" BU_ MFK 80;
BA_ "SyncJumpWidthMin" BU_ MFK 16;
BA_ "SyncJumpWidthMax" BU_ MFK 16;
BA_ "SyncJumpWidthCANFDMin" BU_ MFK 6;
BA_ "SyncJumpWidthCANFDMax" BU_ MFK 6;
BA_ "SamplePointCANFDMin" BU_ MFK 70;
BA_ "SamplePointCANFDMax" BU_ MFK 70;
BA_ "SSPOffsetCANFDMin" BU_ MFK 70;
BA_ "SSPOffsetCANFDMax" BU_ MFK 70;
BA_ "TimeQuantaMin" BU_ MFK 80;
BA_ "TimeQuantaMax" BU_ MFK 80;
BA_ "TimeQuantaCANFDMin" BU_ MFK 20;
BA_ "TimeQuantaCANFDMax" BU_ MFK 20;
BA_ "GenNodSleepTime" BU_ MFK120 4000;
BA_ "NodeLayerModules" BU_ MFK120 "NMHigh.DLL";
BA_ "SamplePointMin" BU_ MFK120 80;
BA_ "SamplePointMax" BU_ MFK120 80;
BA_ "SyncJumpWidthMin" BU_ MFK120 16;
BA_ "SyncJumpWidthMax" BU_ MFK120 16;
BA_ "SyncJumpWidthCANFDMin" BU_ MFK120 6;
BA_ "SyncJumpWidthCANFDMax" BU_ MFK120 6;
BA_ "SamplePointCANFDMin" BU_ MFK120 70;
BA_ "SamplePointCANFDMax" BU_ MFK120 70;
BA_ "SSPOffsetCANFDMin" BU_ MFK120 70;
BA_ "SSPOffsetCANFDMax" BU_ MFK120 70;
BA_ "TimeQuantaMin" BU_ MFK120 80;
BA_ "TimeQuantaMax" BU_ MFK120 80;
BA_ "TimeQuantaCANFDMin" BU_ MFK120 20;
BA_ "TimeQuantaCANFDMax" BU_ MFK120 20;
BA_ "GenNodSleepTime" BU_ MIK 4000;
BA_ "SamplePointMin" BU_ MIK 80;
BA_ "SamplePointMax" BU_ MIK 80;
BA_ "SyncJumpWidthMin" BU_ MIK 16;
BA_ "SyncJumpWidthMax" BU_ MIK 16;
BA_ "SyncJumpWidthCANFDMin" BU_ MIK 6;
BA_ "SyncJumpWidthCANFDMax" BU_ MIK 6;
BA_ "SamplePointCANFDMin" BU_ MIK 70;
BA_ "SamplePointCANFDMax" BU_ MIK 70;
BA_ "SSPOffsetCANFDMin" BU_ MIK 70;
BA_ "SSPOffsetCANFDMax" BU_ MIK 70;
BA_ "TimeQuantaMin" BU_ MIK 80;
BA_ "TimeQuantaMax" BU_ MIK 80;
BA_ "TimeQuantaCANFDMin" BU_ MIK 20;
BA_ "TimeQuantaCANFDMax" BU_ MIK 20;
BA_ "GenNodSleepTime" BU_ MRR2023 4000;
BA_ "ECUVariantGroup" BU_ MRR2023 "ACC";
BA_ "NodeLayerModules" BU_ MRR2023 "NMHigh.DLL";
BA_ "SamplePointMin" BU_ MRR2023 80;
BA_ "SamplePointMax" BU_ MRR2023 80;
BA_ "SyncJumpWidthMin" BU_ MRR2023 16;
BA_ "SyncJumpWidthMax" BU_ MRR2023 16;
BA_ "SyncJumpWidthCANFDMin" BU_ MRR2023 6;
BA_ "SyncJumpWidthCANFDMax" BU_ MRR2023 6;
BA_ "SamplePointCANFDMin" BU_ MRR2023 70;
BA_ "SamplePointCANFDMax" BU_ MRR2023 70;
BA_ "SSPOffsetCANFDMin" BU_ MRR2023 70;
BA_ "SSPOffsetCANFDMax" BU_ MRR2023 70;
BA_ "TimeQuantaMin" BU_ MRR2023 80;
BA_ "TimeQuantaMax" BU_ MRR2023 80;
BA_ "TimeQuantaCANFDMin" BU_ MRR2023 20;
BA_ "TimeQuantaCANFDMax" BU_ MRR2023 20;
BA_ "GenNodSleepTime" BU_ NR_1 4000;
BA_ "NodeLayerModules" BU_ NR_1 "NMHigh.DLL";
BA_ "SamplePointMin" BU_ NR_1 80;
BA_ "SamplePointMax" BU_ NR_1 80;
BA_ "SyncJumpWidthMin" BU_ NR_1 16;
BA_ "SyncJumpWidthMax" BU_ NR_1 16;
BA_ "SyncJumpWidthCANFDMin" BU_ NR_1 6;
BA_ "SyncJumpWidthCANFDMax" BU_ NR_1 6;
BA_ "SamplePointCANFDMin" BU_ NR_1 70;
BA_ "SamplePointCANFDMax" BU_ NR_1 70;
BA_ "SSPOffsetCANFDMin" BU_ NR_1 70;
BA_ "SSPOffsetCANFDMax" BU_ NR_1 70;
BA_ "TimeQuantaMin" BU_ NR_1 80;
BA_ "TimeQuantaMax" BU_ NR_1 80;
BA_ "TimeQuantaCANFDMin" BU_ NR_1 20;
BA_ "TimeQuantaCANFDMax" BU_ NR_1 20;
BA_ "GenNodSleepTime" BU_ NR_2 4000;
BA_ "NodeLayerModules" BU_ NR_2 "NMHigh.DLL";
BA_ "SamplePointMin" BU_ NR_2 80;
BA_ "SamplePointMax" BU_ NR_2 80;
BA_ "SyncJumpWidthMin" BU_ NR_2 16;
BA_ "SyncJumpWidthMax" BU_ NR_2 16;
BA_ "SyncJumpWidthCANFDMin" BU_ NR_2 6;
BA_ "SyncJumpWidthCANFDMax" BU_ NR_2 6;
BA_ "SamplePointCANFDMin" BU_ NR_2 70;
BA_ "SamplePointCANFDMax" BU_ NR_2 70;
BA_ "SSPOffsetCANFDMin" BU_ NR_2 70;
BA_ "SSPOffsetCANFDMax" BU_ NR_2 70;
BA_ "TimeQuantaMin" BU_ NR_2 80;
BA_ "TimeQuantaMax" BU_ NR_2 80;
BA_ "TimeQuantaCANFDMin" BU_ NR_2 20;
BA_ "TimeQuantaCANFDMax" BU_ NR_2 20;
BA_ "GenMsgCycleTime" BO_ 333 20;
BA_ "GenMsgILSupport" BO_ 333 1;
BA_ "GenMsgPDUConstants" BO_ 333 "0x1a,0x65,0x81,0x96,0xc0,0xdf,0x11,0x92,0xd3,0x61,0xc6,0x95,0x8c,0x29,0x21,0xb5";
BA_ "GenMsgSendType" BO_ 333 0;
BA_ "VFrameFormat" BO_ 333 14;
BA_ "GenMsgCycleTime" BO_ 768 60;
BA_ "GenMsgILSupport" BO_ 768 1;
BA_ "GenMsgSendType" BO_ 768 0;
BA_ "VFrameFormat" BO_ 768 14;
BA_ "GenMsgCycleTime" BO_ 2197378135 10;
BA_ "GenMsgILSupport" BO_ 2197378135 1;
BA_ "GenMsgSendType" BO_ 2197378135 0;
BA_ "VFrameFormat" BO_ 2197378135 15;
BA_ "GenMsgCycleTime" BO_ 2527679682 2000;
BA_ "GenMsgDelayTime" BO_ 2527679682 100;
BA_ "GenMsgILSupport" BO_ 2527679682 1;
BA_ "GenMsgSendType" BO_ 2527679682 0;
BA_ "VFrameFormat" BO_ 2527679682 15;
BA_ "GenMsgChkConstant" BO_ 64 64;
BA_ "GenMsgCycleTime" BO_ 64 40;
BA_ "GenMsgCycleTimeFast" BO_ 64 10;
BA_ "GenMsgDelayTime" BO_ 64 10;
BA_ "GenMsgILSupport" BO_ 64 1;
BA_ "GenMsgNrOfRepetition" BO_ 64 5;
BA_ "GenMsgPDUConstants" BO_ 64 "0x40,0x40,0x40,0x40,0x40,0x40,0x40,0x40,0x40,0x40,0x40,0x40,0x40,0x40,0x40,0x40";
BA_ "GenMsgSendType" BO_ 64 0;
BA_ "VFrameFormat" BO_ 64 14;
BA_ "GenMsgChkConstant" BO_ 1312 68;
BA_ "GenMsgCycleTime" BO_ 1312 200;
BA_ "GenMsgDelayTime" BO_ 1312 20;
BA_ "GenMsgILSupport" BO_ 1312 1;
BA_ "GenMsgPDUConstants" BO_ 1312 "0x44,0x44,0x44,0x44,0x44,0x44,0x44,0x44,0x44,0x44,0x44,0x44,0x44,0x44,0x44,0x44";
BA_ "GenMsgSendType" BO_ 1312 0;
BA_ "VFrameFormat" BO_ 1312 14;
BA_ "GenMsgCycleTime" BO_ 1349 200;
BA_ "GenMsgDelayTime" BO_ 1349 40;
BA_ "GenMsgILSupport" BO_ 1349 1;
BA_ "GenMsgPDUConstants" BO_ 1349 "0x95,0x19,0xd1,0x36,0x89,0xd4,0x02,0x1e,0xb9,0x80,0xd0,0x22,0x8a,0xf4,0x15,0xb8";
BA_ "GenMsgSendType" BO_ 1349 0;
BA_ "VFrameFormat" BO_ 1349 14;
BA_ "GenMsgCycleTime" BO_ 2527679722 200;
BA_ "GenMsgILSupport" BO_ 2527679722 1;
BA_ "GenMsgPDUConstants" BO_ 2527679722 "0x81,0x55,0xf0,0x94,0x56,0x5f,0xa4,0x5c,0x2f,0x61,0x48,0x01,0xf8,0xd7,0x33,0x87";
BA_ "GenMsgSendType" BO_ 2527679722 0;
BA_ "VFrameFormat" BO_ 2527679722 15;
BA_ "GenMsgCycleTime" BO_ 1633 100;
BA_ "GenMsgILSupport" BO_ 1633 1;
BA_ "GenMsgSendType" BO_ 1633 0;
BA_ "VFrameFormat" BO_ 1633 14;
BA_ "GenMsgCycleTime" BO_ 616 40;
BA_ "GenMsgILSupport" BO_ 616 1;
BA_ "GenMsgSendType" BO_ 616 0;
BA_ "VFrameFormat" BO_ 616 14;
BA_ "GenMsgChkConstant" BO_ 896 19;
BA_ "GenMsgCycleTime" BO_ 896 80;
BA_ "GenMsgCycleTimeFast" BO_ 896 20;
BA_ "GenMsgILSupport" BO_ 896 1;
BA_ "GenMsgPDUConstants" BO_ 896 "0x13,0x13,0x13,0x13,0x13,0x13,0x13,0x13,0x13,0x13,0x13,0x13,0x13,0x13,0x13,0x13";
BA_ "GenMsgSendType" BO_ 896 0;
BA_ "VFrameFormat" BO_ 896 14;
BA_ "GenMsgCycleTime" BO_ 345 100;
BA_ "GenMsgDelayTime" BO_ 345 10;
BA_ "GenMsgILSupport" BO_ 345 1;
BA_ "GenMsgSendType" BO_ 345 0;
BA_ "VFrameFormat" BO_ 345 14;
BA_ "GenMsgCycleTime" BO_ 2527679661 200;
BA_ "GenMsgDelayTime" BO_ 2527679661 40;
BA_ "GenMsgILSupport" BO_ 2527679661 1;
BA_ "GenMsgSendType" BO_ 2527679661 0;
BA_ "VFrameFormat" BO_ 2527679661 15;
BA_ "GenMsgCycleTime" BO_ 219 1000;
BA_ "GenMsgCycleTimeFast" BO_ 219 20;
BA_ "GenMsgDelayTime" BO_ 219 20;
BA_ "GenMsgILSupport" BO_ 219 1;
BA_ "GenMsgNrOfRepetition" BO_ 219 5;
BA_ "GenMsgPDUConstants" BO_ 219 "0x09,0xfa,0xca,0x8e,0x62,0xd5,0xd1,0xf0,0x31,0xa0,0xaf,0xda,0x4d,0x1a,0x0a,0x97";
BA_ "GenMsgSendType" BO_ 219 0;
BA_ "VFrameFormat" BO_ 219 14;
BA_ "GenMsgSendType" BO_ 2536767264 7;
BA_ "MsgType" BO_ 2536767264 5;
BA_ "VFrameFormat" BO_ 2536767264 15;
BA_ "GenMsgSendType" BO_ 2536767280 7;
BA_ "MsgType" BO_ 2536767280 5;
BA_ "VFrameFormat" BO_ 2536767280 15;
BA_ "GenMsgCycleTimeFast" BO_ 2536728320 80;
BA_ "GenMsgSendType" BO_ 2536728320 7;
BA_ "MsgType" BO_ 2536728320 5;
BA_ "VFrameFormat" BO_ 2536728320 15;
BA_ "GenMsgCycleTime" BO_ 2536728336 1000;
BA_ "GenMsgCycleTimeFast" BO_ 2536728336 30;
BA_ "GenMsgSendType" BO_ 2536728336 7;
BA_ "MsgType" BO_ 2536728336 5;
BA_ "VFrameFormat" BO_ 2536728336 15;
BA_ "GenMsgCycleTime" BO_ 2536728337 1000;
BA_ "GenMsgCycleTimeFast" BO_ 2536728337 10;
BA_ "GenMsgSendType" BO_ 2536728337 7;
BA_ "MsgType" BO_ 2536728337 5;
BA_ "VFrameFormat" BO_ 2536728337 15;
BA_ "GenMsgCycleTimeFast" BO_ 2536725248 80;
BA_ "GenMsgSendType" BO_ 2536725248 7;
BA_ "MsgType" BO_ 2536725248 5;
BA_ "VFrameFormat" BO_ 2536725248 15;
BA_ "GenMsgCycleTimeFast" BO_ 2536725249 10;
BA_ "GenMsgSendType" BO_ 2536725249 7;
BA_ "MsgType" BO_ 2536725249 5;
BA_ "VFrameFormat" BO_ 2536725249 15;
BA_ "GenMsgCycleTime" BO_ 2536725264 1000;
BA_ "GenMsgCycleTimeFast" BO_ 2536725264 20;
BA_ "GenMsgSendType" BO_ 2536725264 7;
BA_ "MsgType" BO_ 2536725264 5;
BA_ "VFrameFormat" BO_ 2536725264 15;
BA_ "GenMsgCycleTime" BO_ 2536725265 1000;
BA_ "GenMsgCycleTimeFast" BO_ 2536725265 20;
BA_ "GenMsgSendType" BO_ 2536725265 7;
BA_ "MsgType" BO_ 2536725265 5;
BA_ "VFrameFormat" BO_ 2536725265 15;
BA_ "GenMsgCycleTimeFast" BO_ 2536726273 80;
BA_ "GenMsgSendType" BO_ 2536726273 7;
BA_ "MsgType" BO_ 2536726273 5;
BA_ "VFrameFormat" BO_ 2536726273 15;
BA_ "GenMsgCycleTime" BO_ 2536726288 1000;
BA_ "GenMsgCycleTimeFast" BO_ 2536726288 20;
BA_ "GenMsgSendType" BO_ 2536726288 7;
BA_ "MsgType" BO_ 2536726288 5;
BA_ "VFrameFormat" BO_ 2536726288 15;
BA_ "GenMsgCycleTime" BO_ 870 1000;
BA_ "GenMsgCycleTimeFast" BO_ 870 50;
BA_ "GenMsgDelayTime" BO_ 870 10;
BA_ "GenMsgILSupport" BO_ 870 1;
BA_ "GenMsgNrOfRepetition" BO_ 870 5;
BA_ "GenMsgPDUConstants" BO_ 870 "0xa9,0xbd,0xfb,0x3c,0x95,0x0f,0x75,0x3a,0x4f,0x19,0x59,0x6d,0xb2,0xe9,0xd1,0x97";
BA_ "GenMsgSendType" BO_ 870 0;
BA_ "VFrameFormat" BO_ 870 14;
BA_ "GenSigSendType" SG_ 333 ACC_18_BZ 0;
BA_ "GenSigFuncType" SG_ 333 ACC_18_BZ 1;
BA_ "GenSigSwitchedByIgnition" SG_ 333 ACC_18_BZ 0;
BA_ "GenSigSendType" SG_ 333 ACC_18_CRC 0;
BA_ "GenSigFuncType" SG_ 333 ACC_18_CRC 2;
BA_ "GenSigSwitchedByIgnition" SG_ 333 ACC_18_CRC 0;
BA_ "GenSigSendType" SG_ 333 ACC_Abbiegewunsch 0;
BA_ "GenSigSwitchedByIgnition" SG_ 333 ACC_Abbiegewunsch 0;
BA_ "GenSigSendType" SG_ 333 ACC_Abbiegewunsch_Abstand 0;
BA_ "GenSigSwitchedByIgnition" SG_ 333 ACC_Abbiegewunsch_Abstand 0;
BA_ "GenSigSendType" SG_ 333 ACC_Anfahren 0;
BA_ "GenSigSendType" SG_ 333 ACC_Anforderung_HMS 0;
BA_ "GenSigSendType" SG_ 333 ACC_Anhalten 0;
BA_ "GenSigSendType" SG_ 333 ACC_Anhalteweg 0;
BA_ "GenSigStartValue" SG_ 333 ACC_Anhalteweg 2046;
BA_ "Fehlerwert" SG_ 333 ACC_Anhalteweg 2047;
BA_ "GenSigSendType" SG_ 333 ACC_DynErhoehung 0;
BA_ "GenSigSendType" SG_ 333 ACC_FoD_Status 0;
BA_ "GenSigSendType" SG_ 333 ACC_Freilauf_Info 0;
BA_ "GenSigSendType" SG_ 333 ACC_Freilaufstrategie_TSK 0;
BA_ "GenSigSendType" SG_ 333 ACC_Minimale_Bremsung 0;
BA_ "GenSigSendType" SG_ 333 ACC_neg_Sollbeschl_Grad_02 0;
BA_ "GenSigSendType" SG_ 333 ACC_pos_Sollbeschl_Grad_02 0;
BA_ "GenSigSendType" SG_ 333 ACC_Sollbeschleunigung_02 0;
BA_ "GenSigStartValue" SG_ 333 ACC_Sollbeschleunigung_02 2046;
BA_ "Fehlerwert" SG_ 333 ACC_Sollbeschleunigung_02 2047;
BA_ "GenSigSendType" SG_ 333 ACC_Sollbeschleunigung_AD 0;
BA_ "GenSigSwitchedByIgnition" SG_ 333 ACC_Sollbeschleunigung_AD 0;
BA_ "Fehlerwert" SG_ 333 ACC_Sollbeschleunigung_AD 4095;
BA_ "GenSigSendType" SG_ 333 ACC_Status_ACC 0;
BA_ "GenSigSendType" SG_ 333 ACC_TA_Kurve_Abstand 0;
BA_ "GenSigStartValue" SG_ 333 ACC_TA_Kurve_Abstand 62;
BA_ "GenSigSendType" SG_ 333 ACC_TA_Kurve_vDelta 0;
BA_ "GenSigStartValue" SG_ 333 ACC_TA_Kurve_vDelta 11;
BA_ "GenSigSendType" SG_ 333 ACC_Tempolimitassistent_Ein 0;
BA_ "GenSigSendType" SG_ 333 ACC_Typ 0;
BA_ "GenSigFuncType" SG_ 333 ACC_Typ 8;
BA_ "GenSigSendType" SG_ 333 ACC_Verkehrssinn 0;
BA_ "GenSigSendType" SG_ 333 ACC_zul_Regelabw_oben 0;
BA_ "GenSigSendType" SG_ 333 ACC_zul_Regelabw_unten 0;
BA_ "GenSigSendType" SG_ 333 MPPmod_1_Segment 0;
BA_ "GenSigSwitchedByIgnition" SG_ 333 MPPmod_1_Segment 0;
BA_ "GenSigSendType" SG_ 333 MPPmod_2_Segment 0;
BA_ "GenSigSwitchedByIgnition" SG_ 333 MPPmod_2_Segment 0;
BA_ "GenSigSendType" SG_ 333 MPPmod_3_Segment 0;
BA_ "GenSigSwitchedByIgnition" SG_ 333 MPPmod_3_Segment 0;
BA_ "GenSigSendType" SG_ 333 MPPmod_4_Segment 0;
BA_ "GenSigSwitchedByIgnition" SG_ 333 MPPmod_4_Segment 0;
BA_ "GenSigSendType" SG_ 333 RDR_v_ueber_Grund 0;
BA_ "GenSigStartValue" SG_ 333 RDR_v_ueber_Grund 4091;
BA_ "Fehlerwert" SG_ 333 RDR_v_ueber_Grund 4093;
BA_ "GenSigSendType" SG_ 333 RDR_v_ueber_Grund_Fahrtrichtung 0;
BA_ "GenSigStartValue" SG_ 333 RDR_v_ueber_Grund_Fahrtrichtung 2;
BA_ "GenSigSendType" SG_ 333 RDR_v_ueber_Grund_Genauigkeit 0;
BA_ "GenSigStartValue" SG_ 333 RDR_v_ueber_Grund_Genauigkeit 62;
BA_ "Fehlerwert" SG_ 333 RDR_v_ueber_Grund_Genauigkeit 63;
BA_ "GenSigSendType" SG_ 333 RDR_VBEG_Anforderung 0;
BA_ "GenSigSendType" SG_ 768 AbstWarn_LRR_FAS_Fkt_Status 0;
BA_ "Fehlerwert" SG_ 768 AbstWarn_LRR_FAS_Fkt_Status 3;
BA_ "GenSigSendType" SG_ 768 ACA_Hinweistexte 0;
BA_ "GenSigSendType" SG_ 768 ACA_Querfuehrung 0;
BA_ "GenSigSendType" SG_ 768 ACA_Querfuehrung_Texte 0;
BA_ "GenSigSendType" SG_ 768 ACC_Abstand_LNS 0;
BA_ "GenSigSendType" SG_ 768 ACC_Abstand_RNS 0;
BA_ "GenSigSendType" SG_ 768 ACC_Abstand_WZO 0;
BA_ "GenSigSendType" SG_ 768 ACC_Abstandsindex_02 0;
BA_ "GenSigSendType" SG_ 768 ACC_Akustik_03 0;
BA_ "GenSigSendType" SG_ 768 ACC_Anzeige_Maximalabstand 0;
BA_ "GenSigSendType" SG_ 768 ACC_Anzeige_Objektmarkierung 0;
BA_ "GenSigSwitchedByIgnition" SG_ 768 ACC_Anzeige_Objektmarkierung 0;
BA_ "GenSigSendType" SG_ 768 ACC_Anzeige_Objektregelung 0;
BA_ "GenSigSendType" SG_ 768 ACC_Anzeige_Zeitluecke 0;
BA_ "GenSigSendType" SG_ 768 ACC_Display_Prio 0;
BA_ "GenSigSendType" SG_ 768 ACC_EGO_Fahrzeug 0;
BA_ "GenSigSendType" SG_ 768 ACC_Einheit_maxSetzgeschw 0;
BA_ "GenSigSendType" SG_ 768 ACC_ENG_Texte 0;
BA_ "GenSigSendType" SG_ 768 ACC_ENG_Texte_02 0;
BA_ "GenSigSendType" SG_ 768 ACC_FoD_Status 0;
BA_ "GenSigSendType" SG_ 768 ACC_FzgStatus_Anfahrbereitschaft 0;
BA_ "GenSigSendType" SG_ 768 ACC_FzgStatus_Fehleranzeige 0;
BA_ "GenSigSendType" SG_ 768 ACC_FzgStatus_Kamerafusion 0;
BA_ "GenSigSendType" SG_ 768 ACC_Gesetzte_Zeitluecke 0;
BA_ "GenSigSendType" SG_ 768 ACC_iBoost_Anzeige 0;
BA_ "GenSigSendType" SG_ 768 ACC_maxSetzgeschw 0;
BA_ "GenSigStartValue" SG_ 768 ACC_maxSetzgeschw 511;
BA_ "GenSigSendType" SG_ 768 ACC_Modus_Pop_Up 0;
BA_ "GenSigSwitchedByIgnition" SG_ 768 ACC_Modus_Pop_Up 0;
BA_ "GenSigSendType" SG_ 768 ACC_Optischer_Fahrerhinweis 0;
BA_ "GenSigSendType" SG_ 768 ACC_Regelgeschw 0;
BA_ "GenSigStartValue" SG_ 768 ACC_Regelgeschw 1023;
BA_ "GenSigSendType" SG_ 768 ACC_Regelung_AIO 0;
BA_ "GenSigSendType" SG_ 768 ACC_rel_Objekt_Zusatzanz 0;
BA_ "GenSigSendType" SG_ 768 ACC_Relevantes_Objekt_02 0;
BA_ "GenSigSendType" SG_ 768 ACC_RUV 0;
BA_ "GenSigSendType" SG_ 768 ACC_Sollabstand_1 0;
BA_ "GenSigSendType" SG_ 768 ACC_Sollabstand_2 0;
BA_ "GenSigSendType" SG_ 768 ACC_Sollabstand_3 0;
BA_ "GenSigSendType" SG_ 768 ACC_Sollabstand_4 0;
BA_ "GenSigSendType" SG_ 768 ACC_Sollabstand_5 0;
BA_ "GenSigSendType" SG_ 768 ACC_Status_Anzeige 0;
BA_ "GenSigSendType" SG_ 768 ACC_Status_GRA_Modus 0;
BA_ "GenSigSendType" SG_ 768 ACC_Status_Stauende 0;
BA_ "GenSigSwitchedByIgnition" SG_ 768 ACC_Status_Stauende 0;
BA_ "GenSigSendType" SG_ 768 ACC_Statusicon 0;
BA_ "GenSigSendType" SG_ 768 ACC_Tachokranz 0;
BA_ "GenSigSendType" SG_ 768 ACC_Tempolimit 0;
BA_ "GenSigSendType" SG_ 768 ACC_Tempolimit_Einheit 0;
BA_ "GenSigSendType" SG_ 768 ACC_Texte_02 0;
BA_ "GenSigSendType" SG_ 768 ACC_Texte_03 0;
BA_ "GenSigSendType" SG_ 768 ACC_Texte_Primaeranz_03 0;
BA_ "GenSigSendType" SG_ 768 ACC_Texte_Sekundaeranz_02 0;
BA_ "GenSigSendType" SG_ 768 ACC_Texte_Sekundaeranz_03 0;
BA_ "GenSigSendType" SG_ 768 ACC_Texte_Zusatzanz_03 0;
BA_ "GenSigSendType" SG_ 768 ACC_Typ_LNS 0;
BA_ "GenSigSendType" SG_ 768 ACC_Typ_RNS 0;
BA_ "GenSigSendType" SG_ 768 ACC_Typ_Tachokranz_unten 0;
BA_ "GenSigSendType" SG_ 768 ACC_Typ_WZO 0;
BA_ "GenSigSendType" SG_ 768 ACC_Warnung_Verkehrszeichen_1 0;
BA_ "GenSigSendType" SG_ 768 ACC_Wunschgeschw_02 0;
BA_ "GenSigStartValue" SG_ 768 ACC_Wunschgeschw_02 1023;
BA_ "GenSigSendType" SG_ 768 ACC_Wunschgeschw_erreicht 0;
BA_ "GenSigSendType" SG_ 768 ACC_Wunschgeschw_Farbe 0;
BA_ "GenSigSendType" SG_ 768 ACC_Wunschgeschw_Farbe_02 0;
BA_ "GenSigSendType" SG_ 768 FAS_Licht_Anf 0;
BA_ "GenSigSendType" SG_ 768 STA_Primaeranz 0;
BA_ "GenSigSendType" SG_ 768 STA_Texte 0;
BA_ "GenSigSendType" SG_ 768 STA_Zusatzanz 0;
BA_ "GenSigSendType" SG_ 2197378135 ACC_24_BZ 0;
BA_ "GenSigSwitchedByIgnition" SG_ 2197378135 ACC_24_BZ 0;
BA_ "GenSigSendType" SG_ 2197378135 ACC_24_CRC 0;
BA_ "GenSigSwitchedByIgnition" SG_ 2197378135 ACC_24_CRC 0;
BA_ "GenSigSendType" SG_ 2197378135 ACC_Sollbeschleunigung_AD 0;
BA_ "GenSigSwitchedByIgnition" SG_ 2197378135 ACC_Sollbeschleunigung_AD 0;
BA_ "Fehlerwert" SG_ 2197378135 ACC_Sollbeschleunigung_AD 4095;
BA_ "GenSigSendType" SG_ 2527679682 ACC_ASM_Data_1 0;
BA_ "GenSigSendType" SG_ 2527679682 ACC_ASM_Data_2 0;
BA_ "GenSigSendType" SG_ 2527679682 ACC_ASM_Data_3 0;
BA_ "GenSigSendType" SG_ 2527679682 ACC_ASM_Data_4 0;
BA_ "GenSigSendType" SG_ 2527679682 ACC_ASM_Data_5 0;
BA_ "GenSigSendType" SG_ 2527679682 ACC_ASM_Data_6 0;
BA_ "GenSigSendType" SG_ 2527679682 ACC_ASM_Ereignis 3;
BA_ "GenSigSendType" SG_ 2527679682 ACC_ASM_Zeitstempel_02 3;
BA_ "GenSigStartValue" SG_ 2527679682 ACC_ASM_Zeitstempel_02 255;
BA_ "GenSigSendType" SG_ 64 AB_Anzeige_Fussg 0;
BA_ "GenSigSwitchedByIgnition" SG_ 64 AB_Anzeige_Fussg 0;
BA_ "GenSigSendType" SG_ 64 AB_Belegung_VF 0;
BA_ "GenSigSwitchedByIgnition" SG_ 64 AB_Belegung_VF 0;
BA_ "Fehlerwert" SG_ 64 AB_Belegung_VF 1;
BA_ "GenSigSendType" SG_ 64 AB_Crash_Int 4;
BA_ "GenSigSwitchedByIgnition" SG_ 64 AB_Crash_Int 0;
BA_ "GenSigSendType" SG_ 64 AB_Deaktiviert 0;
BA_ "GenSigSwitchedByIgnition" SG_ 64 AB_Deaktiviert 0;
BA_ "GenSigSendType" SG_ 64 AB_Deaktivierung_HV 4;
BA_ "GenSigSwitchedByIgnition" SG_ 64 AB_Deaktivierung_HV 0;
BA_ "Fehlerwert" SG_ 64 AB_Deaktivierung_HV 7;
BA_ "GenSigSendType" SG_ 64 AB_Diagnose 0;
BA_ "GenSigSwitchedByIgnition" SG_ 64 AB_Diagnose 0;
BA_ "GenSigSendType" SG_ 64 AB_eCS_Error 0;
BA_ "GenSigSwitchedByIgnition" SG_ 64 AB_eCS_Error 0;
BA_ "GenSigSendType" SG_ 64 AB_EDR_Trigger 3;
BA_ "GenSigSwitchedByIgnition" SG_ 64 AB_EDR_Trigger 0;
BA_ "GenSigSendType" SG_ 64 AB_Erh_Auf_VB 0;
BA_ "GenSigSwitchedByIgnition" SG_ 64 AB_Erh_Auf_VB 0;
BA_ "GenSigSendType" SG_ 64 AB_Front_Crash 4;
BA_ "GenSigSwitchedByIgnition" SG_ 64 AB_Front_Crash 0;
BA_ "GenSigSendType" SG_ 64 AB_Gurtschloss_FA_ext 3;
BA_ "GenSigStartValue" SG_ 64 AB_Gurtschloss_FA_ext 6;
BA_ "GenSigSwitchedByIgnition" SG_ 64 AB_Gurtschloss_FA_ext 0;
BA_ "Fehlerwert" SG_ 64 AB_Gurtschloss_FA_ext 7;
BA_ "GenSigSendType" SG_ 64 AB_Gurtschloss_FA_ext_aktiv 0;
BA_ "GenSigSwitchedByIgnition" SG_ 64 AB_Gurtschloss_FA_ext_aktiv 0;
BA_ "GenSigSendType" SG_ 64 AB_Gurtwarn_VB 0;
BA_ "GenSigSwitchedByIgnition" SG_ 64 AB_Gurtwarn_VB 0;
BA_ "GenSigSendType" SG_ 64 AB_Gurtwarn_VF 0;
BA_ "GenSigSwitchedByIgnition" SG_ 64 AB_Gurtwarn_VF 0;
BA_ "GenSigSendType" SG_ 64 AB_Heck_Crash 4;
BA_ "GenSigSwitchedByIgnition" SG_ 64 AB_Heck_Crash 0;
BA_ "GenSigSendType" SG_ 64 AB_Lampe 0;
BA_ "GenSigStartValue" SG_ 64 AB_Lampe 1;
BA_ "GenSigSwitchedByIgnition" SG_ 64 AB_Lampe 0;
BA_ "GenSigSendType" SG_ 64 AB_MKB_Anforderung 4;
BA_ "GenSigSwitchedByIgnition" SG_ 64 AB_MKB_Anforderung 0;
BA_ "GenSigSendType" SG_ 64 AB_MKB_gueltig 0;
BA_ "GenSigSwitchedByIgnition" SG_ 64 AB_MKB_gueltig 0;
BA_ "GenSigSendType" SG_ 64 AB_PAO_Leuchte_Anf 0;
BA_ "GenSigStartValue" SG_ 64 AB_PAO_Leuchte_Anf 1;
BA_ "GenSigSwitchedByIgnition" SG_ 64 AB_PAO_Leuchte_Anf 0;
BA_ "GenSigSendType" SG_ 64 AB_RGS_Anst 3;
BA_ "GenSigStartValue" SG_ 64 AB_RGS_Anst 8;
BA_ "GenSigSwitchedByIgnition" SG_ 64 AB_RGS_Anst 0;
BA_ "GenSigSendType" SG_ 64 AB_Rollover_Crash 4;
BA_ "GenSigSwitchedByIgnition" SG_ 64 AB_Rollover_Crash 0;
BA_ "GenSigSendType" SG_ 64 AB_SB_Crash 4;
BA_ "GenSigSwitchedByIgnition" SG_ 64 AB_SB_Crash 0;
BA_ "GenSigSendType" SG_ 64 AB_SF_Crash 4;
BA_ "GenSigSwitchedByIgnition" SG_ 64 AB_SF_Crash 0;
BA_ "GenSigSendType" SG_ 64 AB_Stellgliedtest 0;
BA_ "GenSigSwitchedByIgnition" SG_ 64 AB_Stellgliedtest 0;
BA_ "GenSigSendType" SG_ 64 AB_Systemfehler 0;
BA_ "GenSigSwitchedByIgnition" SG_ 64 AB_Systemfehler 0;
BA_ "GenSigSendType" SG_ 64 AB_Texte_AKS 0;
BA_ "GenSigSwitchedByIgnition" SG_ 64 AB_Texte_AKS 0;
BA_ "GenSigSendType" SG_ 64 AB_VB_deaktiviert 0;
BA_ "GenSigStartValue" SG_ 64 AB_VB_deaktiviert 1;
BA_ "GenSigSwitchedByIgnition" SG_ 64 AB_VB_deaktiviert 0;
BA_ "GenSigSendType" SG_ 64 AB_Versorgungsspannung 0;
BA_ "GenSigSwitchedByIgnition" SG_ 64 AB_Versorgungsspannung 0;
BA_ "GenSigSendType" SG_ 64 Airbag_01_BZ 0;
BA_ "GenSigFuncType" SG_ 64 Airbag_01_BZ 1;
BA_ "GenSigSwitchedByIgnition" SG_ 64 Airbag_01_BZ 0;
BA_ "GenSigSendType" SG_ 64 Airbag_01_CRC 0;
BA_ "GenSigFuncType" SG_ 64 Airbag_01_CRC 2;
BA_ "GenSigSwitchedByIgnition" SG_ 64 Airbag_01_CRC 0;
BA_ "GenSigSendType" SG_ 64 ASM_Masterzeit_02 0;
BA_ "GenSigStartValue" SG_ 64 ASM_Masterzeit_02 255;
BA_ "GenSigSwitchedByIgnition" SG_ 64 ASM_Masterzeit_02 0;
BA_ "GenSigSendType" SG_ 1312 AB_Abschaltanf_SIH_BF 3;
BA_ "GenSigSendType" SG_ 1312 AB_Anforderung_eCall 0;
BA_ "GenSigSwitchedByIgnition" SG_ 1312 AB_Anforderung_eCall 0;
BA_ "GenSigSendType" SG_ 1312 AB_Anforderung_USM 0;
BA_ "GenSigSwitchedByIgnition" SG_ 1312 AB_Anforderung_USM 0;
BA_ "GenSigSendType" SG_ 1312 AB_Anprall_FGS 3;
BA_ "GenSigSendType" SG_ 1312 AB_Anprall_Front_Beifahrer 3;
BA_ "GenSigSendType" SG_ 1312 AB_Anprall_Front_Fahrer 3;
BA_ "GenSigSendType" SG_ 1312 AB_Anprall_Seite_Beifahrer 3;
BA_ "GenSigSendType" SG_ 1312 AB_Anprall_Seite_Fahrer 3;
BA_ "GenSigSendType" SG_ 1312 AB_Belegung_VB 0;
BA_ "GenSigSwitchedByIgnition" SG_ 1312 AB_Belegung_VB 0;
BA_ "Fehlerwert" SG_ 1312 AB_Belegung_VB 1;
BA_ "GenSigSendType" SG_ 1312 AB_Crashschwere 3;
BA_ "GenSigSwitchedByIgnition" SG_ 1312 AB_Crashschwere 0;
BA_ "Fehlerwert" SG_ 1312 AB_Crashschwere 7;
BA_ "GenSigSendType" SG_ 1312 AB_Gurtschloss_BF 3;
BA_ "GenSigStartValue" SG_ 1312 AB_Gurtschloss_BF 1;
BA_ "GenSigSwitchedByIgnition" SG_ 1312 AB_Gurtschloss_BF 0;
BA_ "GenSigSendType" SG_ 1312 AB_Gurtschloss_FA 3;
BA_ "GenSigStartValue" SG_ 1312 AB_Gurtschloss_FA 1;
BA_ "GenSigSwitchedByIgnition" SG_ 1312 AB_Gurtschloss_FA 0;
BA_ "GenSigSendType" SG_ 1312 AB_Gurtschloss_Reihe2_BF 3;
BA_ "GenSigStartValue" SG_ 1312 AB_Gurtschloss_Reihe2_BF 1;
BA_ "GenSigSwitchedByIgnition" SG_ 1312 AB_Gurtschloss_Reihe2_BF 0;
BA_ "GenSigSendType" SG_ 1312 AB_Gurtschloss_Reihe2_FA 3;
BA_ "GenSigStartValue" SG_ 1312 AB_Gurtschloss_Reihe2_FA 1;
BA_ "GenSigSwitchedByIgnition" SG_ 1312 AB_Gurtschloss_Reihe2_FA 0;
BA_ "GenSigSendType" SG_ 1312 AB_Gurtschloss_Reihe2_MI 3;
BA_ "GenSigStartValue" SG_ 1312 AB_Gurtschloss_Reihe2_MI 1;
BA_ "GenSigSwitchedByIgnition" SG_ 1312 AB_Gurtschloss_Reihe2_MI 0;
BA_ "GenSigSendType" SG_ 1312 AB_Gurtschloss_Reihe3_BF 3;
BA_ "GenSigStartValue" SG_ 1312 AB_Gurtschloss_Reihe3_BF 1;
BA_ "GenSigSwitchedByIgnition" SG_ 1312 AB_Gurtschloss_Reihe3_BF 0;
BA_ "GenSigSendType" SG_ 1312 AB_Gurtschloss_Reihe3_FA 3;
BA_ "GenSigStartValue" SG_ 1312 AB_Gurtschloss_Reihe3_FA 1;
BA_ "GenSigSwitchedByIgnition" SG_ 1312 AB_Gurtschloss_Reihe3_FA 0;
BA_ "GenSigSendType" SG_ 1312 AB_Gurtschloss_Reihe3_MI 3;
BA_ "GenSigStartValue" SG_ 1312 AB_Gurtschloss_Reihe3_MI 1;
BA_ "GenSigSwitchedByIgnition" SG_ 1312 AB_Gurtschloss_Reihe3_MI 0;
BA_ "GenSigSendType" SG_ 1312 AB_Sitzpos_Sens_BF 0;
BA_ "GenSigSwitchedByIgnition" SG_ 1312 AB_Sitzpos_Sens_BF 0;
BA_ "Fehlerwert" SG_ 1312 AB_Sitzpos_Sens_BF 1;
BA_ "GenSigSendType" SG_ 1312 AB_Sitzpos_Sens_FA 0;
BA_ "GenSigSwitchedByIgnition" SG_ 1312 AB_Sitzpos_Sens_FA 0;
BA_ "Fehlerwert" SG_ 1312 AB_Sitzpos_Sens_FA 1;
BA_ "GenSigSendType" SG_ 1312 AB_Wickelklappung_Reihe2_BF 3;
BA_ "GenSigStartValue" SG_ 1312 AB_Wickelklappung_Reihe2_BF 1;
BA_ "GenSigSwitchedByIgnition" SG_ 1312 AB_Wickelklappung_Reihe2_BF 0;
BA_ "GenSigSendType" SG_ 1312 AB_Wickelklappung_Reihe2_FA 3;
BA_ "GenSigStartValue" SG_ 1312 AB_Wickelklappung_Reihe2_FA 1;
BA_ "GenSigSwitchedByIgnition" SG_ 1312 AB_Wickelklappung_Reihe2_FA 0;
BA_ "GenSigSendType" SG_ 1312 AB_Wickelklappung_Reihe2_MI 3;
BA_ "GenSigStartValue" SG_ 1312 AB_Wickelklappung_Reihe2_MI 1;
BA_ "GenSigSwitchedByIgnition" SG_ 1312 AB_Wickelklappung_Reihe2_MI 0;
BA_ "GenSigSendType" SG_ 1312 Airbag_02_BZ 0;
BA_ "GenSigFuncType" SG_ 1312 Airbag_02_BZ 1;
BA_ "GenSigSwitchedByIgnition" SG_ 1312 Airbag_02_BZ 0;
BA_ "GenSigSendType" SG_ 1312 Airbag_02_CRC 0;
BA_ "GenSigFuncType" SG_ 1312 Airbag_02_CRC 2;
BA_ "GenSigSwitchedByIgnition" SG_ 1312 Airbag_02_CRC 0;
BA_ "GenSigSendType" SG_ 1312 LoGeWa_Event_Kombiwarnung 3;
BA_ "GenSigSwitchedByIgnition" SG_ 1312 LoGeWa_Event_Kombiwarnung 0;
BA_ "GenSigSendType" SG_ 1312 SC_PAO_OFF_Anf 3;
BA_ "GenSigSwitchedByIgnition" SG_ 1312 SC_PAO_OFF_Anf 0;
BA_ "GenSigSendType" SG_ 1312 SC_PAO_ON_Anf 3;
BA_ "GenSigSwitchedByIgnition" SG_ 1312 SC_PAO_ON_Anf 0;
BA_ "GenSigSendType" SG_ 1312 SC_PAO_Schriftzug_Anf 3;
BA_ "GenSigSwitchedByIgnition" SG_ 1312 SC_PAO_Schriftzug_Anf 0;
BA_ "GenSigSendType" SG_ 1349 AB_Anprall_Heck 3;
BA_ "GenSigSwitchedByIgnition" SG_ 1349 AB_Anprall_Heck 0;
BA_ "GenSigSendType" SG_ 1349 AB_Belegung_VF_ext 3;
BA_ "GenSigStartValue" SG_ 1349 AB_Belegung_VF_ext 6;
BA_ "GenSigSwitchedByIgnition" SG_ 1349 AB_Belegung_VF_ext 0;
BA_ "Fehlerwert" SG_ 1349 AB_Belegung_VF_ext 7;
BA_ "GenSigSendType" SG_ 1349 AB_Belegung_VF_ext_aktiv 3;
BA_ "GenSigSwitchedByIgnition" SG_ 1349 AB_Belegung_VF_ext_aktiv 0;
BA_ "GenSigSendType" SG_ 1349 AB_Gurtwarn_Reihe2_BF 0;
BA_ "GenSigSwitchedByIgnition" SG_ 1349 AB_Gurtwarn_Reihe2_BF 0;
BA_ "GenSigSendType" SG_ 1349 AB_Gurtwarn_Reihe2_FA 0;
BA_ "GenSigSwitchedByIgnition" SG_ 1349 AB_Gurtwarn_Reihe2_FA 0;
BA_ "GenSigSendType" SG_ 1349 AB_Gurtwarn_Reihe2_MI 0;
BA_ "GenSigSwitchedByIgnition" SG_ 1349 AB_Gurtwarn_Reihe2_MI 0;
BA_ "GenSigSendType" SG_ 1349 AB_Gurtwarn_Reihe3_BF 0;
BA_ "GenSigSwitchedByIgnition" SG_ 1349 AB_Gurtwarn_Reihe3_BF 0;
BA_ "GenSigSendType" SG_ 1349 AB_Gurtwarn_Reihe3_FA 0;
BA_ "GenSigSwitchedByIgnition" SG_ 1349 AB_Gurtwarn_Reihe3_FA 0;
BA_ "GenSigSendType" SG_ 1349 AB_Gurtwarn_Reihe3_MI 0;
BA_ "GenSigSwitchedByIgnition" SG_ 1349 AB_Gurtwarn_Reihe3_MI 0;
BA_ "GenSigSendType" SG_ 1349 AB_Gurtwarn_Reihe4_BF 0;
BA_ "GenSigSwitchedByIgnition" SG_ 1349 AB_Gurtwarn_Reihe4_BF 0;
BA_ "GenSigSendType" SG_ 1349 AB_Gurtwarn_Reihe4_FA 0;
BA_ "GenSigSwitchedByIgnition" SG_ 1349 AB_Gurtwarn_Reihe4_FA 0;
BA_ "GenSigSendType" SG_ 1349 AB_Gurtwarn_Reihe4_MI 0;
BA_ "GenSigSwitchedByIgnition" SG_ 1349 AB_Gurtwarn_Reihe4_MI 0;
BA_ "GenSigSendType" SG_ 1349 AB_SBR_hinten_verbau 0;
BA_ "GenSigStartValue" SG_ 1349 AB_SBR_hinten_verbau 3;
BA_ "GenSigSwitchedByIgnition" SG_ 1349 AB_SBR_hinten_verbau 0;
BA_ "GenSigSendType" SG_ 1349 AbstWarn_MV_FAS_Fkt_Status 3;
BA_ "GenSigSwitchedByIgnition" SG_ 1349 AbstWarn_MV_FAS_Fkt_Status 0;
BA_ "Fehlerwert" SG_ 1349 AbstWarn_MV_FAS_Fkt_Status 3;
BA_ "GenSigSendType" SG_ 1349 Airbag_04_BZ 0;
BA_ "GenSigFuncType" SG_ 1349 Airbag_04_BZ 1;
BA_ "GenSigSwitchedByIgnition" SG_ 1349 Airbag_04_BZ 0;
BA_ "GenSigSendType" SG_ 1349 Airbag_04_CRC 0;
BA_ "GenSigFuncType" SG_ 1349 Airbag_04_CRC 2;
BA_ "GenSigSwitchedByIgnition" SG_ 1349 Airbag_04_CRC 0;
BA_ "GenSigSendType" SG_ 1349 AWV_Einstellung_System_ASG 3;
BA_ "GenSigSwitchedByIgnition" SG_ 1349 AWV_Einstellung_System_ASG 0;
BA_ "GenSigSendType" SG_ 1349 AWV_Einstellung_Warnung_ASG 3;
BA_ "GenSigSwitchedByIgnition" SG_ 1349 AWV_Einstellung_Warnung_ASG 0;
BA_ "GenSigSendType" SG_ 1349 LGI_FAS_Fkt_Status 3;
BA_ "GenSigSwitchedByIgnition" SG_ 1349 LGI_FAS_Fkt_Status 0;
BA_ "Fehlerwert" SG_ 1349 LGI_FAS_Fkt_Status 3;
BA_ "GenSigSendType" SG_ 1349 PreCrash_FAS_Fkt_Status 3;
BA_ "GenSigSwitchedByIgnition" SG_ 1349 PreCrash_FAS_Fkt_Status 0;
BA_ "Fehlerwert" SG_ 1349 PreCrash_FAS_Fkt_Status 3;
BA_ "GenSigSendType" SG_ 1349 SC_PreSense_Modus_System_KAS 3;
BA_ "GenSigSwitchedByIgnition" SG_ 1349 SC_PreSense_Modus_System_KAS 0;
BA_ "GenSigSendType" SG_ 1349 SC_PreSense_Modus_System_MV 3;
BA_ "GenSigSwitchedByIgnition" SG_ 1349 SC_PreSense_Modus_System_MV 0;
BA_ "GenSigSendType" SG_ 1349 SC_PreSense_Modus_System_NV 3;
BA_ "GenSigSwitchedByIgnition" SG_ 1349 SC_PreSense_Modus_System_NV 0;
BA_ "GenSigSendType" SG_ 1349 SC_PreSense_Modus_Warnung_MV 3;
BA_ "GenSigSwitchedByIgnition" SG_ 1349 SC_PreSense_Modus_Warnung_MV 0;
BA_ "GenSigSendType" SG_ 1349 SC_PreSense_Modus_Warnung_NV 3;
BA_ "GenSigSwitchedByIgnition" SG_ 1349 SC_PreSense_Modus_Warnung_NV 0;
BA_ "GenSigSendType" SG_ 1349 WarnBrems_Charisma_FahrPr 0;
BA_ "GenSigSendType" SG_ 1349 WarnBrems_Charisma_Status 0;
BA_ "GenSigSendType" SG_ 2527679722 AB_Gurtschloss_MI 0;
BA_ "GenSigStartValue" SG_ 2527679722 AB_Gurtschloss_MI 1;
BA_ "GenSigSwitchedByIgnition" SG_ 2527679722 AB_Gurtschloss_MI 0;
BA_ "GenSigSendType" SG_ 2527679722 AB_Gurtschloss_Reihe4_BF 0;
BA_ "GenSigStartValue" SG_ 2527679722 AB_Gurtschloss_Reihe4_BF 1;
BA_ "GenSigSwitchedByIgnition" SG_ 2527679722 AB_Gurtschloss_Reihe4_BF 0;
BA_ "GenSigSendType" SG_ 2527679722 AB_Gurtschloss_Reihe4_FA 0;
BA_ "GenSigStartValue" SG_ 2527679722 AB_Gurtschloss_Reihe4_FA 1;
BA_ "GenSigSwitchedByIgnition" SG_ 2527679722 AB_Gurtschloss_Reihe4_FA 0;
BA_ "GenSigSendType" SG_ 2527679722 AB_Gurtschloss_Reihe4_MI 0;
BA_ "GenSigStartValue" SG_ 2527679722 AB_Gurtschloss_Reihe4_MI 1;
BA_ "GenSigSwitchedByIgnition" SG_ 2527679722 AB_Gurtschloss_Reihe4_MI 0;
BA_ "GenSigSendType" SG_ 2527679722 AB_Gurtwarn_VM 0;
BA_ "GenSigSwitchedByIgnition" SG_ 2527679722 AB_Gurtwarn_VM 0;
BA_ "GenSigSendType" SG_ 2527679722 AB_wSBR_Batteriestatus 0;
BA_ "GenSigSwitchedByIgnition" SG_ 2527679722 AB_wSBR_Batteriestatus 0;
BA_ "GenSigSendType" SG_ 1633 AAG_Anhaenger_abgesteckt 0;
BA_ "GenSigSwitchedByIgnition" SG_ 1633 AAG_Anhaenger_abgesteckt 0;
BA_ "GenSigSendType" SG_ 1633 AAG_Anhaenger_erkannt 0;
BA_ "NWM-WakeupAllowed" SG_ 1633 AAG_Anhaenger_erkannt 1;
BA_ "GenSigSwitchedByIgnition" SG_ 1633 AAG_Anhaenger_erkannt 0;
BA_ "GenSigSendType" SG_ 1633 AAG_AVS_Fehler_02 0;
BA_ "GenSigSwitchedByIgnition" SG_ 1633 AAG_AVS_Fehler_02 0;
BA_ "Fehlerwert" SG_ 1633 AAG_AVS_Fehler_02 1;
BA_ "GenSigSendType" SG_ 1633 AAG_AVS_Fehler_02_inv 0;
BA_ "GenSigStartValue" SG_ 1633 AAG_AVS_Fehler_02_inv 1;
BA_ "GenSigSwitchedByIgnition" SG_ 1633 AAG_AVS_Fehler_02_inv 0;
BA_ "GenSigSendType" SG_ 1633 AAG_AVS_Stati 0;
BA_ "GenSigSwitchedByIgnition" SG_ 1633 AAG_AVS_Stati 0;
BA_ "GenSigSendType" SG_ 1633 AAG_Blinker_H_aktiv 0;
BA_ "GenSigSwitchedByIgnition" SG_ 1633 AAG_Blinker_H_aktiv 0;
BA_ "GenSigSendType" SG_ 1633 AAG_Blinker_HL_def 0;
BA_ "GenSigSwitchedByIgnition" SG_ 1633 AAG_Blinker_HL_def 0;
BA_ "GenSigSendType" SG_ 1633 AAG_Blinker_HR_def 0;
BA_ "GenSigSwitchedByIgnition" SG_ 1633 AAG_Blinker_HR_def 0;
BA_ "GenSigSendType" SG_ 1633 AAG_Bremsl_durch_ECD 0;
BA_ "GenSigSwitchedByIgnition" SG_ 1633 AAG_Bremsl_durch_ECD 0;
BA_ "GenSigSendType" SG_ 1633 AAG_Bremslicht_H_def 0;
BA_ "GenSigSwitchedByIgnition" SG_ 1633 AAG_Bremslicht_H_def 0;
BA_ "GenSigSendType" SG_ 1633 AAG_Bremslicht_Reku 0;
BA_ "GenSigSwitchedByIgnition" SG_ 1633 AAG_Bremslicht_Reku 0;
BA_ "GenSigSendType" SG_ 1633 AAG_BZ 0;
BA_ "GenSigFuncType" SG_ 1633 AAG_BZ 1;
BA_ "GenSigSwitchedByIgnition" SG_ 1633 AAG_BZ 0;
BA_ "GenSigSendType" SG_ 1633 AAG_LED_aktiv 0;
BA_ "GenSigSwitchedByIgnition" SG_ 1633 AAG_LED_aktiv 0;
BA_ "GenSigSendType" SG_ 1633 AAG_NSL_aktiv 0;
BA_ "GenSigSwitchedByIgnition" SG_ 1633 AAG_NSL_aktiv 0;
BA_ "GenSigSendType" SG_ 1633 AAG_Schlusslicht_HL_def 0;
BA_ "GenSigSwitchedByIgnition" SG_ 1633 AAG_Schlusslicht_HL_def 0;
BA_ "GenSigSendType" SG_ 1633 AAG_Schlusslicht_HR_def 0;
BA_ "GenSigSwitchedByIgnition" SG_ 1633 AAG_Schlusslicht_HR_def 0;
BA_ "GenSigSendType" SG_ 616 US_Datenalter_HLS 0;
BA_ "GenSigSendType" SG_ 616 US_Datenalter_HRS 0;
BA_ "GenSigSendType" SG_ 616 US_Datenalter_VLS 0;
BA_ "GenSigSendType" SG_ 616 US_Datenalter_VRS 0;
BA_ "GenSigSendType" SG_ 616 US_Fehler_HLS 0;
BA_ "Fehlerwert" SG_ 616 US_Fehler_HLS 1;
BA_ "GenSigSendType" SG_ 616 US_Fehler_HRS 0;
BA_ "Fehlerwert" SG_ 616 US_Fehler_HRS 1;
BA_ "GenSigSendType" SG_ 616 US_Fehler_VLS 0;
BA_ "Fehlerwert" SG_ 616 US_Fehler_VLS 1;
BA_ "GenSigSendType" SG_ 616 US_Fehler_VRS 0;
BA_ "Fehlerwert" SG_ 616 US_Fehler_VRS 1;
BA_ "GenSigSendType" SG_ 616 US_Links_01_Pos_X 0;
BA_ "GenSigStartValue" SG_ 616 US_Links_01_Pos_X 1023;
BA_ "GenSigSendType" SG_ 616 US_Links_01_Pos_Y 0;
BA_ "GenSigStartValue" SG_ 616 US_Links_01_Pos_Y 511;
BA_ "GenSigSendType" SG_ 616 US_Links_01_Valid 0;
BA_ "GenSigSendType" SG_ 616 US_Links_02_Pos_X 0;
BA_ "GenSigStartValue" SG_ 616 US_Links_02_Pos_X 1023;
BA_ "GenSigSendType" SG_ 616 US_Links_02_Pos_Y 0;
BA_ "GenSigStartValue" SG_ 616 US_Links_02_Pos_Y 511;
BA_ "GenSigSendType" SG_ 616 US_Links_02_Valid 0;
BA_ "GenSigSendType" SG_ 616 US_Nichtverfuegbarkeit_HLS 0;
BA_ "GenSigStartValue" SG_ 616 US_Nichtverfuegbarkeit_HLS 1;
BA_ "GenSigSendType" SG_ 616 US_Nichtverfuegbarkeit_HRS 0;
BA_ "GenSigStartValue" SG_ 616 US_Nichtverfuegbarkeit_HRS 1;
BA_ "GenSigSendType" SG_ 616 US_Nichtverfuegbarkeit_VLS 0;
BA_ "GenSigStartValue" SG_ 616 US_Nichtverfuegbarkeit_VLS 1;
BA_ "GenSigSendType" SG_ 616 US_Nichtverfuegbarkeit_VRS 0;
BA_ "GenSigStartValue" SG_ 616 US_Nichtverfuegbarkeit_VRS 1;
BA_ "GenSigSendType" SG_ 616 US_QAbstand_HLS 0;
BA_ "GenSigStartValue" SG_ 616 US_QAbstand_HLS 511;
BA_ "GenSigSendType" SG_ 616 US_QAbstand_HRS 0;
BA_ "GenSigStartValue" SG_ 616 US_QAbstand_HRS 511;
BA_ "GenSigSendType" SG_ 616 US_QAbstand_VLS 0;
BA_ "GenSigStartValue" SG_ 616 US_QAbstand_VLS 511;
BA_ "GenSigSendType" SG_ 616 US_QAbstand_VRS 0;
BA_ "GenSigStartValue" SG_ 616 US_QAbstand_VRS 511;
BA_ "GenSigSendType" SG_ 616 US_Rechts_01_Pos_X 0;
BA_ "GenSigStartValue" SG_ 616 US_Rechts_01_Pos_X 1023;
BA_ "GenSigSendType" SG_ 616 US_Rechts_01_Pos_Y 0;
BA_ "GenSigStartValue" SG_ 616 US_Rechts_01_Pos_Y 511;
BA_ "GenSigSendType" SG_ 616 US_Rechts_01_Valid 0;
BA_ "GenSigSendType" SG_ 616 US_Rechts_02_Pos_X 0;
BA_ "GenSigStartValue" SG_ 616 US_Rechts_02_Pos_X 1023;
BA_ "GenSigSendType" SG_ 616 US_Rechts_02_Pos_Y 0;
BA_ "GenSigStartValue" SG_ 616 US_Rechts_02_Pos_Y 511;
BA_ "GenSigSendType" SG_ 616 US_Rechts_02_Valid 0;
BA_ "GenSigSendType" SG_ 896 APS_Master_Sendestatus 5;
BA_ "GenSigSendType" SG_ 896 US_ACC_BZ 0;
BA_ "GenSigFuncType" SG_ 896 US_ACC_BZ 1;
BA_ "GenSigSendType" SG_ 896 US_ACC_CRC 0;
BA_ "GenSigFuncType" SG_ 896 US_ACC_CRC 2;
BA_ "GenSigSendType" SG_ 896 US_blindness_detected 0;
BA_ "GenSigSendType" SG_ 896 US_Freie_Weglaenge_Front 0;
BA_ "GenSigStartValue" SG_ 896 US_Freie_Weglaenge_Front 510;
BA_ "Fehlerwert" SG_ 896 US_Freie_Weglaenge_Front 511;
BA_ "GenSigSendType" SG_ 896 US_Freie_Weglaenge_Front_Typ 0;
BA_ "GenSigSendType" SG_ 896 US_Freie_Weglaenge_Heck 0;
BA_ "GenSigStartValue" SG_ 896 US_Freie_Weglaenge_Heck 510;
BA_ "Fehlerwert" SG_ 896 US_Freie_Weglaenge_Heck 511;
BA_ "GenSigSendType" SG_ 896 US_Freie_Weglaenge_Heck_Typ 0;
BA_ "GenSigSendType" SG_ 896 US_Freisicht_nio 0;
BA_ "GenSigSendType" SG_ 896 US_relevante_Nichtverfuegbarkeit 0;
BA_ "GenSigSendType" SG_ 896 US_relevanter_Fehler 0;
BA_ "GenSigSendType" SG_ 896 US_Sende_Modus 0;
BA_ "Fehlerwert" SG_ 896 US_Sende_Modus 15;
BA_ "GenSigSendType" SG_ 896 US_Sende_Modus_hinten 0;
BA_ "Fehlerwert" SG_ 896 US_Sende_Modus_hinten 15;
BA_ "GenSigSendType" SG_ 345 ARA_Anf_Meldungen 0;
BA_ "GenSigSendType" SG_ 345 ARA_Knickwinkel_Ist 3;
BA_ "GenSigStartValue" SG_ 345 ARA_Knickwinkel_Ist 254;
BA_ "Fehlerwert" SG_ 345 ARA_Knickwinkel_Ist 255;
BA_ "GenSigSendType" SG_ 345 ARA_Knickwinkel_Komfort 3;
BA_ "GenSigStartValue" SG_ 345 ARA_Knickwinkel_Komfort 62;
BA_ "Fehlerwert" SG_ 345 ARA_Knickwinkel_Komfort 63;
BA_ "GenSigSendType" SG_ 345 ARA_Knickwinkel_Konfidenz 0;
BA_ "GenSigStartValue" SG_ 345 ARA_Knickwinkel_Konfidenz 126;
BA_ "Fehlerwert" SG_ 345 ARA_Knickwinkel_Konfidenz 127;
BA_ "GenSigSendType" SG_ 345 ARA_Knickwinkel_Max 3;
BA_ "GenSigStartValue" SG_ 345 ARA_Knickwinkel_Max 126;
BA_ "Fehlerwert" SG_ 345 ARA_Knickwinkel_Max 127;
BA_ "GenSigSendType" SG_ 345 ARA_Knickwinkel_Soll 3;
BA_ "GenSigStartValue" SG_ 345 ARA_Knickwinkel_Soll 254;
BA_ "Fehlerwert" SG_ 345 ARA_Knickwinkel_Soll 255;
BA_ "GenSigSendType" SG_ 345 ARA_Modus 0;
BA_ "GenSigSendType" SG_ 345 ARA_Sensor_Aktivierung 3;
BA_ "GenSigSendType" SG_ 345 ARA_Status 3;
BA_ "GenSigStartValue" SG_ 345 ARA_Status 1;
BA_ "Fehlerwert" SG_ 345 ARA_Status 2;
BA_ "GenSigSendType" SG_ 2527679661 AWV_AW_Abstand 3;
BA_ "GenSigStartValue" SG_ 2527679661 AWV_AW_Abstand 511;
BA_ "GenSigSendType" SG_ 2527679661 AWV_AW_Texte 3;
BA_ "GenSigSendType" SG_ 2527679661 AWV_AW_Texte_Zusatzanzeige 3;
BA_ "GenSigSendType" SG_ 2527679661 AWV_AW_Zeitluecke 3;
BA_ "GenSigSendType" SG_ 2527679661 AWV_Einstellung_System_FSG 3;
BA_ "GenSigSendType" SG_ 2527679661 AWV_Einstellung_Warnung_FSG 3;
BA_ "GenSigSendType" SG_ 2527679661 AWV_KA_Konfiguration 3;
BA_ "GenSigSendType" SG_ 2527679661 AWV_KA_ObjektFront 3;
BA_ "GenSigSendType" SG_ 2527679661 AWV_Kamera_Objekt_ID 3;
BA_ "GenSigSwitchedByIgnition" SG_ 2527679661 AWV_Kamera_Objekt_ID 0;
BA_ "GenSigSendType" SG_ 2527679661 AWV_LED_Leiste 3;
BA_ "GenSigSendType" SG_ 2527679661 AWV_Priowarnung 3;
BA_ "GenSigSendType" SG_ 2527679661 AWV_Status_Anzeige 3;
BA_ "GenSigSendType" SG_ 2527679661 AWV_Texte 3;
BA_ "GenSigSendType" SG_ 2527679661 AWV_Warnlevel 3;
BA_ "GenSigSendType" SG_ 2527679661 AWV_Warnung 3;
BA_ "GenSigSendType" SG_ 2527679661 AWV_Warnung_Richtung 3;
BA_ "GenSigSwitchedByIgnition" SG_ 2527679661 AWV_Warnung_Richtung 0;
BA_ "GenSigSendType" SG_ 2527679661 WBA_Warnblinken 3;
BA_ "GenSigSendType" SG_ 219 AWV_03_BZ 0;
BA_ "GenSigFuncType" SG_ 219 AWV_03_BZ 1;
BA_ "GenSigSwitchedByIgnition" SG_ 219 AWV_03_BZ 0;
BA_ "GenSigSendType" SG_ 219 AWV_03_CRC 0;
BA_ "GenSigFuncType" SG_ 219 AWV_03_CRC 2;
BA_ "GenSigSwitchedByIgnition" SG_ 219 AWV_03_CRC 0;
BA_ "GenSigSendType" SG_ 219 AWV_Anf_Prefill 0;
BA_ "GenSigSendType" SG_ 219 AWV_Eingriff_Sendeart 6;
BA_ "GenSigSendType" SG_ 219 AWV_Fahrerbremswunsch_erf 0;
BA_ "GenSigSendType" SG_ 219 AWV_HBA_Param 0;
BA_ "GenSigSendType" SG_ 219 AWV_QFK_AnfStat 0;
BA_ "GenSigStartValue" SG_ 219 AWV_QFK_AnfStat 1;
BA_ "GenSigSendType" SG_ 219 AWV_QFK_Art1 0;
BA_ "GenSigSendType" SG_ 219 AWV_QFK_Art2 0;
BA_ "GenSigSendType" SG_ 219 AWV_QFK_KrSoll 0;
BA_ "GenSigStartValue" SG_ 219 AWV_QFK_KrSoll 65535;
BA_ "GenSigSendType" SG_ 219 AWV_QFK_KrSoll_VZ 0;
BA_ "GenSigSendType" SG_ 219 AWV_QFK_KruemmSoll 0;
BA_ "GenSigSendType" SG_ 219 AWV_QFK_KruemmSoll_VZ 0;
BA_ "GenSigSendType" SG_ 219 AWV_QFK_Signal1 0;
BA_ "GenSigSendType" SG_ 219 AWV_QFK_Signal2 0;
BA_ "GenSigSendType" SG_ 219 AWV_QFK_Spuerb 0;
BA_ "GenSigSendType" SG_ 219 AWV_Ruckprofil 0;
BA_ "GenSigSendType" SG_ 219 AWV_Status_AWU 0;
BA_ "GenSigStartValue" SG_ 219 AWV_Status_AWU 14;
BA_ "GenSigSendType" SG_ 219 AWV_Time_to_brake 0;
BA_ "GenSigStartValue" SG_ 219 AWV_Time_to_brake 127;
BA_ "GenSigSendType" SG_ 219 AWV_Time_to_collision 0;
BA_ "GenSigStartValue" SG_ 219 AWV_Time_to_collision 255;
BA_ "GenSigSwitchedByIgnition" SG_ 219 AWV_Time_to_collision 0;
BA_ "GenSigSendType" SG_ 219 AWV_Timestamp_TTC 0;
BA_ "GenSigStartValue" SG_ 219 AWV_Timestamp_TTC 8191;
BA_ "GenSigSendType" SG_ 219 AWV_Verz_Anf 0;
BA_ "GenSigStartValue" SG_ 219 AWV_Verz_Anf 1023;
BA_ "GenSigSendType" SG_ 219 AWV_Verz_Anf_ASIL 0;
BA_ "GenSigSendType" SG_ 219 AWV_Verz_Freigabe 0;
BA_ "GenSigSendType" SG_ 219 AWV_Zielobjekttyp 0;
BA_ "GenSigStartValue" SG_ 219 AWV_Zielobjekttyp 15;
BA_ "GenSigSendType" SG_ 219 PCF_Freigabe 0;
BA_ "GenSigSendType" SG_ 219 SDF_PSF_CU_Status 0;
BA_ "GenSigSendType" SG_ 219 SDF_PSF_CW 0;
BA_ "GenSigStartValue" SG_ 219 SDF_PSF_CW 126;
BA_ "Fehlerwert" SG_ 219 SDF_PSF_CW 127;
BA_ "GenSigSendType" SG_ 219 SDF_PSF_Fahrer_aktiv 0;
BA_ "GenSigStartValue" SG_ 219 SDF_PSF_Fahrer_aktiv 1;
BA_ "GenSigSendType" SG_ 219 SDF_PSF_Guete 0;
BA_ "GenSigSendType" SG_ 219 SDF_PSF_Kollisionsueberdeckung 0;
BA_ "GenSigStartValue" SG_ 219 SDF_PSF_Kollisionsueberdeckung 30;
BA_ "Fehlerwert" SG_ 219 SDF_PSF_Kollisionsueberdeckung 31;
BA_ "GenSigSendType" SG_ 219 SDF_PSF_Objektstatus 0;
BA_ "Fehlerwert" SG_ 219 SDF_PSF_Objektstatus 7;
BA_ "GenSigSendType" SG_ 219 SDF_PSF_Time_To_Collision 0;
BA_ "GenSigStartValue" SG_ 219 SDF_PSF_Time_To_Collision 254;
BA_ "Fehlerwert" SG_ 219 SDF_PSF_Time_To_Collision 255;
BA_ "GenSigSendType" SG_ 219 SDF_PSF_v_rel 0;
BA_ "GenSigStartValue" SG_ 219 SDF_PSF_v_rel 254;
BA_ "Fehlerwert" SG_ 219 SDF_PSF_v_rel 255;
BA_ "GenSigSendType" SG_ 219 SOK_AWV_03_Signatur 0;
BA_ "GenSigFuncType" SG_ 219 SOK_AWV_03_Signatur 15;
BA_ "GenSigSwitchedByIgnition" SG_ 219 SOK_AWV_03_Signatur 0;
BA_ "GenSigSendType" SG_ 2536767264 BAP_Debug_Cmd 3;
BA_ "GenSigSwitchedByIgnition" SG_ 2536767264 BAP_Debug_Cmd 0;
BA_ "GenSigSendType" SG_ 2536767280 BAP_Debug_Data 3;
BA_ "GenSigSwitchedByIgnition" SG_ 2536767280 BAP_Debug_Data 0;
BA_ "GenSigSendType" SG_ 2536728320 BAP_REM2_ASG_01_Header 3;
BA_ "GenSigSwitchedByIgnition" SG_ 2536728320 BAP_REM2_ASG_01_Header 0;
BA_ "GenSigSendType" SG_ 2536728336 BAP_REM2_FSG_01_Header 3;
BA_ "GenSigSwitchedByIgnition" SG_ 2536728336 BAP_REM2_FSG_01_Header 0;
BA_ "GenSigSendType" SG_ 2536728337 BAP_REM2_FSG_02_Header 3;
BA_ "GenSigSwitchedByIgnition" SG_ 2536728337 BAP_REM2_FSG_02_Header 0;
BA_ "GenSigSendType" SG_ 2536725248 BAP_REM_ASG_01_Header 3;
BA_ "GenSigSwitchedByIgnition" SG_ 2536725248 BAP_REM_ASG_01_Header 0;
BA_ "GenSigSendType" SG_ 2536725249 BAP_REM_ASG_02_Header 3;
BA_ "GenSigSwitchedByIgnition" SG_ 2536725249 BAP_REM_ASG_02_Header 0;
BA_ "GenSigSendType" SG_ 2536725264 BAP_REM_FSG_01_Header 3;
BA_ "GenSigSwitchedByIgnition" SG_ 2536725264 BAP_REM_FSG_01_Header 0;
BA_ "GenSigSendType" SG_ 2536725265 BAP_REM_FSG_02_Header 3;
BA_ "GenSigSwitchedByIgnition" SG_ 2536725265 BAP_REM_FSG_02_Header 0;
BA_ "GenSigSendType" SG_ 2536726273 BAP_TPA_ASG_02_Header 3;
BA_ "GenSigSwitchedByIgnition" SG_ 2536726273 BAP_TPA_ASG_02_Header 0;
BA_ "GenSigSendType" SG_ 2536726288 BAP_TPA_FSG_01_Header 3;
BA_ "GenSigSwitchedByIgnition" SG_ 2536726288 BAP_TPA_FSG_01_Header 0;
BA_ "GenSigSendType" SG_ 870 Blinken_li_Fzg_Takt 4;
BA_ "GenSigSwitchedByIgnition" SG_ 870 Blinken_li_Fzg_Takt 0;
BA_ "GenSigSendType" SG_ 870 Blinken_li_Kombi_Takt 4;
BA_ "GenSigSwitchedByIgnition" SG_ 870 Blinken_li_Kombi_Takt 0;
BA_ "GenSigSendType" SG_ 870 Blinken_re_Fzg_Takt 4;
BA_ "GenSigSwitchedByIgnition" SG_ 870 Blinken_re_Fzg_Takt 0;
BA_ "GenSigSendType" SG_ 870 Blinken_re_Kombi_Takt 4;
BA_ "GenSigSwitchedByIgnition" SG_ 870 Blinken_re_Kombi_Takt 0;
BA_ "GenSigSendType" SG_ 870 Blinkmodi_02_BZ 0;
BA_ "GenSigFuncType" SG_ 870 Blinkmodi_02_BZ 1;
BA_ "GenSigSwitchedByIgnition" SG_ 870 Blinkmodi_02_BZ 0;
BA_ "GenSigSendType" SG_ 870 Blinkmodi_02_CRC 0;
BA_ "GenSigFuncType" SG_ 870 Blinkmodi_02_CRC 2;
BA_ "GenSigSwitchedByIgnition" SG_ 870 Blinkmodi_02_CRC 0;
BA_ "GenSigSendType" SG_ 870 BM_Autobahn 4;
BA_ "GenSigSwitchedByIgnition" SG_ 870 BM_Autobahn 0;
BA_ "GenSigSendType" SG_ 870 BM_Crash 4;
BA_ "GenSigSwitchedByIgnition" SG_ 870 BM_Crash 0;
BA_ "GenSigSendType" SG_ 870 BM_DWA_Alarm 4;
BA_ "GenSigSwitchedByIgnition" SG_ 870 BM_DWA_Alarm 0;
BA_ "GenSigSendType" SG_ 870 BM_DWA_ein 4;
BA_ "GenSigSwitchedByIgnition" SG_ 870 BM_DWA_ein 0;
BA_ "GenSigSendType" SG_ 870 BM_GDO 4;
BA_ "GenSigSwitchedByIgnition" SG_ 870 BM_GDO 0;
BA_ "GenSigSendType" SG_ 870 BM_HD_Oeffnung_angelernt 3;
BA_ "GenSigSwitchedByIgnition" SG_ 870 BM_HD_Oeffnung_angelernt 0;
BA_ "GenSigSendType" SG_ 870 BM_links 4;
BA_ "GenSigSwitchedByIgnition" SG_ 870 BM_links 0;
BA_ "GenSigSendType" SG_ 870 BM_NBA_n_codiert_n_aktiv 3;
BA_ "GenSigStartValue" SG_ 870 BM_NBA_n_codiert_n_aktiv 1;
BA_ "GenSigSwitchedByIgnition" SG_ 870 BM_NBA_n_codiert_n_aktiv 0;
BA_ "GenSigSendType" SG_ 870 BM_NBA_Status 4;
BA_ "GenSigSwitchedByIgnition" SG_ 870 BM_NBA_Status 0;
BA_ "GenSigSendType" SG_ 870 BM_Not_Bremsung 4;
BA_ "GenSigSwitchedByIgnition" SG_ 870 BM_Not_Bremsung 0;
BA_ "GenSigSendType" SG_ 870 BM_Panik 4;
BA_ "GenSigSwitchedByIgnition" SG_ 870 BM_Panik 0;
BA_ "GenSigSendType" SG_ 870 BM_PiloPa 4;
BA_ "GenSigSwitchedByIgnition" SG_ 870 BM_PiloPa 0;
BA_ "GenSigSendType" SG_ 870 BM_Recas 5;
BA_ "GenSigSwitchedByIgnition" SG_ 870 BM_Recas 0;
BA_ "GenSigSendType" SG_ 870 BM_rechts 4;
BA_ "GenSigSwitchedByIgnition" SG_ 870 BM_rechts 0;
BA_ "GenSigSendType" SG_ 870 BM_Rollenmodus_Blinken 5;
BA_ "GenSigSwitchedByIgnition" SG_ 870 BM_Rollenmodus_Blinken 0;
BA_ "GenSigSendType" SG_ 870 BM_Taxi_Notalarm 4;
BA_ "GenSigSwitchedByIgnition" SG_ 870 BM_Taxi_Notalarm 0;
BA_ "GenSigSendType" SG_ 870 BM_Telematik 4;
BA_ "GenSigSwitchedByIgnition" SG_ 870 BM_Telematik 0;
BA_ "GenSigSendType" SG_ 870 BM_Telematik_Abbruchgrund 4;
BA_ "GenSigSwitchedByIgnition" SG_ 870 BM_Telematik_Abbruchgrund 0;
BA_ "GenSigSendType" SG_ 870 BM_Warnblinken 4;
BA_ "GenSigSwitchedByIgnition" SG_ 870 BM_Warnblinken 0;
BA_ "GenSigSendType" SG_ 870 BM_WBT_Beleuchtung 3;
BA_ "GenSigSwitchedByIgnition" SG_ 870 BM_WBT_Beleuchtung 0;
BA_ "GenSigSendType" SG_ 870 BM_Wischblinken 4;
BA_ "GenSigSwitchedByIgnition" SG_ 870 BM_Wischblinken 0;
BA_ "GenSigSendType" SG_ 870 BM_ZV_auf 4;
BA_ "GenSigSwitchedByIgnition" SG_ 870 BM_ZV_auf 0;
BA_ "GenSigSendType" SG_ 870 BM_ZV_zu 4;
BA_ "GenSigSwitchedByIgnition" SG_ 870 BM_ZV_zu 0;
BA_ "GenSigSendType" SG_ 870 DWA_Alarmquelle 0;
BA_ "GenSigStartValue" SG_ 870 DWA_Alarmquelle 30;
BA_ "GenSigSwitchedByIgnition" SG_ 870 DWA_Alarmquelle 0;
BA_ "Fehlerwert" SG_ 870 DWA_Alarmquelle 31;
BA_ "GenSigSendType" SG_ 870 SAL_RHP_Blinken_Status 3;
BA_ "GenSigSwitchedByIgnition" SG_ 870 SAL_RHP_Blinken_Status 0;
BA_ "GenSigSendType" SG_ 870 SAL_RHP_Warnblinken 3;
BA_ "GenSigSwitchedByIgnition" SG_ 870 SAL_RHP_Warnblinken 0;
BA_ "GenSigSendType" SG_ 870 SAL_TA_Blinken_Status 4;
BA_ "GenSigSwitchedByIgnition" SG_ 870 SAL_TA_Blinken_Status 0;
BA_REL_ "GenSigTimeoutTime" BU_SG_REL_ FASFrontradar SG_ 64 Airbag_01_CRC 500;
BA_REL_ "GenSigTimeoutTime" BU_SG_REL_ FASFrontradar SG_ 64 Airbag_01_BZ 500;
BA_REL_ "GenSigTimeoutTime" BU_SG_REL_ FASFrontradar SG_ 64 AB_Crash_Int 500;
BA_REL_ "GenSigTimeoutTime" BU_SG_REL_ FASFrontradar SG_ 64 AB_Belegung_VF 500;
BA_REL_ "GenSigTimeoutTime" BU_SG_REL_ FASFrontradar SG_ 64 ASM_Masterzeit_02 500;
BA_REL_ "GenSigTimeoutTime" BU_SG_REL_ FASFrontradar SG_ 1312 Airbag_02_CRC 2000;
BA_REL_ "GenSigTimeoutTime" BU_SG_REL_ FASFrontradar SG_ 1312 Airbag_02_BZ 2000;
BA_REL_ "GenSigTimeoutTime" BU_SG_REL_ FASFrontradar SG_ 1349 Airbag_04_CRC 2000;
BA_REL_ "GenSigTimeoutTime" BU_SG_REL_ FASFrontradar SG_ 1349 Airbag_04_BZ 2000;
BA_REL_ "GenSigTimeoutTime" BU_SG_REL_ FASFrontradar SG_ 896 US_Sende_Modus 800;
BA_REL_ "GenSigTimeoutTime" BU_SG_REL_ FASFrontradar SG_ 896 US_relevanter_Fehler 800;
BA_REL_ "GenSigTimeoutTime" BU_SG_REL_ FASFrontradar SG_ 896 US_relevante_Nichtverfuegbarkeit 800;
BA_REL_ "GenSigTimeoutTime" BU_SG_REL_ FASFrontradar SG_ 896 US_Freisicht_nio 800;
BA_REL_ "GenSigTimeoutTime" BU_SG_REL_ FASFrontradar SG_ 896 US_blindness_detected 800;
BA_REL_ "GenSigTimeoutTime" BU_SG_REL_ FASFrontradar SG_ 896 US_Freie_Weglaenge_Front_Typ 800;
BA_REL_ "GenSigTimeoutTime" BU_SG_REL_ FASFrontradar SG_ 896 US_Freie_Weglaenge_Front 800;
BA_REL_ "GenSigTimeoutTime" BU_SG_REL_ FASFrontradar SG_ 2536728320 BAP_REM2_ASG_01_Header 800;
BA_REL_ "GenSigTimeoutTime" BU_SG_REL_ FASFrontradar SG_ 870 BM_Warnblinken 5000;
BA_REL_ "GenSigTimeoutTime" BU_SG_REL_ ICAS1_X_Gateway SG_ 333 ACC_Typ 500;
BA_REL_ "GenSigTimeoutTime" BU_SG_REL_ ICAS1_X_Gateway SG_ 333 ACC_Status_ACC 500;
BA_REL_ "GenSigTimeoutTime" BU_SG_REL_ ICAS1_X_Gateway SG_ 333 ACC_FoD_Status 500;
BA_REL_ "GenSigTimeoutTime" BU_SG_REL_ ICAS1_X_Gateway SG_ 333 RDR_v_ueber_Grund 500;
BA_REL_ "GenSigTimeoutTime" BU_SG_REL_ ICAS1_X_Gateway SG_ 768 ACC_FzgStatus_Kamerafusion 600;
BA_REL_ "GenSigTimeoutTime" BU_SG_REL_ ICAS1_X_Gateway SG_ 768 ACC_FzgStatus_Anfahrbereitschaft 600;
BA_REL_ "GenSigTimeoutTime" BU_SG_REL_ ICAS1_X_Gateway SG_ 768 ACC_FzgStatus_Fehleranzeige 600;
BA_REL_ "GenSigTimeoutTime" BU_SG_REL_ ICAS1_X_Gateway SG_ 768 ACC_ENG_Texte_02 600;
BA_REL_ "GenSigTimeoutTime" BU_SG_REL_ ICAS1_X_Gateway SG_ 768 ACC_Tempolimit 600;
BA_REL_ "GenSigTimeoutTime" BU_SG_REL_ ICAS1_X_Gateway SG_ 768 ACC_Warnung_Verkehrszeichen_1 600;
BA_REL_ "GenSigTimeoutTime" BU_SG_REL_ ICAS1_X_Gateway SG_ 768 ACA_Querfuehrung 600;
BA_REL_ "GenSigTimeoutTime" BU_SG_REL_ ICAS1_X_Gateway SG_ 768 ACC_Wunschgeschw_Farbe_02 600;
BA_REL_ "GenSigTimeoutTime" BU_SG_REL_ ICAS1_X_Gateway SG_ 768 ACC_Wunschgeschw_02 600;
BA_REL_ "GenSigTimeoutTime" BU_SG_REL_ ICAS1_X_Gateway SG_ 768 ACC_Abstandsindex_02 600;
BA_REL_ "GenSigTimeoutTime" BU_SG_REL_ ICAS1_X_Gateway SG_ 768 ACC_Display_Prio 600;
BA_REL_ "GenSigTimeoutTime" BU_SG_REL_ ICAS1_X_Gateway SG_ 768 ACC_rel_Objekt_Zusatzanz 600;
BA_REL_ "GenSigTimeoutTime" BU_SG_REL_ ICAS1_X_Gateway SG_ 768 ACC_Gesetzte_Zeitluecke 600;
BA_REL_ "GenSigTimeoutTime" BU_SG_REL_ ICAS1_X_Gateway SG_ 768 ACC_Optischer_Fahrerhinweis 600;
BA_REL_ "GenSigTimeoutTime" BU_SG_REL_ ICAS1_X_Gateway SG_ 768 ACC_EGO_Fahrzeug 600;
BA_REL_ "GenSigTimeoutTime" BU_SG_REL_ ICAS1_X_Gateway SG_ 768 ACC_Relevantes_Objekt_02 600;
BA_REL_ "GenSigTimeoutTime" BU_SG_REL_ ICAS1_X_Gateway SG_ 768 ACC_Wunschgeschw_erreicht 600;
BA_REL_ "GenSigTimeoutTime" BU_SG_REL_ ICAS1_X_Gateway SG_ 768 ACC_Anzeige_Zeitluecke 600;
BA_REL_ "GenSigTimeoutTime" BU_SG_REL_ ICAS1_X_Gateway SG_ 768 ACC_Texte_Primaeranz_03 600;
BA_REL_ "GenSigTimeoutTime" BU_SG_REL_ ICAS1_X_Gateway SG_ 768 ACC_Texte_Zusatzanz_03 600;
BA_REL_ "GenSigTimeoutTime" BU_SG_REL_ ICAS1_X_Gateway SG_ 768 ACC_Anzeige_Objektmarkierung 600;
BA_REL_ "GenSigTimeoutTime" BU_SG_REL_ ICAS1_X_Gateway SG_ 768 ACC_Regelgeschw 600;
BA_REL_ "GenSigTimeoutTime" BU_SG_REL_ ICAS1_X_Gateway SG_ 768 ACC_Tempolimit_Einheit 600;
BA_REL_ "GenSigTimeoutTime" BU_SG_REL_ ICAS1_X_Gateway SG_ 768 ACC_RUV 600;
BA_REL_ "GenSigTimeoutTime" BU_SG_REL_ ICAS1_X_Gateway SG_ 768 ACC_Tachokranz 600;
BA_REL_ "GenSigTimeoutTime" BU_SG_REL_ ICAS1_X_Gateway SG_ 768 ACC_Typ_Tachokranz_unten 600;
BA_REL_ "GenSigTimeoutTime" BU_SG_REL_ ICAS1_X_Gateway SG_ 768 ACC_ENG_Texte 600;
BA_REL_ "GenSigTimeoutTime" BU_SG_REL_ ICAS1_X_Gateway SG_ 768 ACC_Status_GRA_Modus 600;
BA_REL_ "GenSigTimeoutTime" BU_SG_REL_ ICAS1_X_Gateway SG_ 768 ACA_Querfuehrung_Texte 600;
BA_REL_ "GenSigTimeoutTime" BU_SG_REL_ ICAS1_X_Gateway SG_ 768 ACA_Hinweistexte 600;
BA_REL_ "GenSigTimeoutTime" BU_SG_REL_ ICAS1_X_Gateway SG_ 768 ACC_FoD_Status 600;
BA_REL_ "GenSigTimeoutTime" BU_SG_REL_ ICAS1_X_Gateway SG_ 768 ACC_Status_Anzeige 600;
BA_REL_ "GenSigTimeoutTime" BU_SG_REL_ ICAS1_X_Gateway SG_ 768 ACC_Akustik_03 600;
BA_REL_ "GenSigTimeoutTime" BU_SG_REL_ ICAS1_X_Gateway SG_ 768 ACC_Texte_02 600;
BA_REL_ "GenSigTimeoutTime" BU_SG_REL_ ICAS1_X_Gateway SG_ 768 ACC_Status_Stauende 600;
BA_REL_ "GenSigTimeoutTime" BU_SG_REL_ ICAS1_X_Gateway SG_ 768 FAS_Licht_Anf 600;
BA_REL_ "GenSigTimeoutTime" BU_SG_REL_ ICAS1_X_Gateway SG_ 768 ACC_Texte_Sekundaeranz_03 600;
BA_REL_ "GenSigTimeoutTime" BU_SG_REL_ ICAS1_X_Gateway SG_ 768 ACC_Modus_Pop_Up 600;
BA_REL_ "GenSigTimeoutTime" BU_SG_REL_ ICAS1_X_Gateway SG_ 768 ACC_Statusicon 600;
BA_REL_ "GenSigTimeoutTime" BU_SG_REL_ ICAS1_X_Gateway SG_ 768 ACC_Anzeige_Objektregelung 600;
BA_REL_ "GenSigTimeoutTime" BU_SG_REL_ ICAS1_X_Gateway SG_ 768 ACC_Anzeige_Maximalabstand 600;
BA_REL_ "GenSigTimeoutTime" BU_SG_REL_ ICAS1_X_Gateway SG_ 768 ACC_Typ_LNS 600;
BA_REL_ "GenSigTimeoutTime" BU_SG_REL_ ICAS1_X_Gateway SG_ 768 ACC_Typ_RNS 600;
BA_REL_ "GenSigTimeoutTime" BU_SG_REL_ ICAS1_X_Gateway SG_ 768 ACC_Typ_WZO 600;
BA_REL_ "GenSigTimeoutTime" BU_SG_REL_ ICAS1_X_Gateway SG_ 768 ACC_Abstand_WZO 600;
BA_REL_ "GenSigTimeoutTime" BU_SG_REL_ ICAS1_X_Gateway SG_ 768 ACC_Abstand_RNS 600;
BA_REL_ "GenSigTimeoutTime" BU_SG_REL_ ICAS1_X_Gateway SG_ 768 ACC_Abstand_LNS 600;
BA_REL_ "GenSigTimeoutTime" BU_SG_REL_ ICAS1_X_Gateway SG_ 768 ACC_Texte_03 600;
BA_REL_ "GenSigTimeoutTime" BU_SG_REL_ ICAS1_X_Gateway SG_ 768 ACC_Texte_Sekundaeranz_02 600;
BA_REL_ "GenSigTimeoutTime" BU_SG_REL_ ICAS1_X_Gateway SG_ 768 ACC_Sollabstand_1 600;
BA_REL_ "GenSigTimeoutTime" BU_SG_REL_ ICAS1_X_Gateway SG_ 768 ACC_Sollabstand_2 600;
BA_REL_ "GenSigTimeoutTime" BU_SG_REL_ ICAS1_X_Gateway SG_ 768 ACC_Sollabstand_3 600;
BA_REL_ "GenSigTimeoutTime" BU_SG_REL_ ICAS1_X_Gateway SG_ 768 ACC_Sollabstand_4 600;
BA_REL_ "GenSigTimeoutTime" BU_SG_REL_ ICAS1_X_Gateway SG_ 768 ACC_Sollabstand_5 600;
BA_REL_ "GenSigTimeoutTime" BU_SG_REL_ ICAS1_X_Gateway SG_ 2527679661 AWV_Warnung 2000;
BA_REL_ "GenSigTimeoutTime" BU_SG_REL_ ICAS1_X_Gateway SG_ 2527679661 AWV_Texte 2000;
BA_REL_ "GenSigTimeoutTime" BU_SG_REL_ ICAS1_X_Gateway SG_ 2527679661 AWV_AW_Zeitluecke 2000;
BA_REL_ "GenSigTimeoutTime" BU_SG_REL_ ICAS1_X_Gateway SG_ 2527679661 AWV_AW_Texte 2000;
BA_REL_ "GenSigTimeoutTime" BU_SG_REL_ ICAS1_X_Gateway SG_ 2527679661 AWV_AW_Texte_Zusatzanzeige 2000;
BA_REL_ "GenSigTimeoutTime" BU_SG_REL_ ICAS1_X_Gateway SG_ 2527679661 AWV_Warnung_Richtung 2000;
BA_REL_ "GenSigTimeoutTime" BU_SG_REL_ ICAS1_X_Gateway SG_ 2527679661 AWV_Kamera_Objekt_ID 2000;
BA_REL_ "GenSigTimeoutTime" BU_SG_REL_ MFK SG_ 333 ACC_Status_ACC 500;
BA_REL_ "GenSigTimeoutTime" BU_SG_REL_ MFK SG_ 333 ACC_Tempolimitassistent_Ein 500;
BA_REL_ "GenSigTimeoutTime" BU_SG_REL_ MFK SG_ 333 ACC_FoD_Status 500;
BA_REL_ "GenSigTimeoutTime" BU_SG_REL_ MFK SG_ 333 ACC_TA_Kurve_Abstand 500;
BA_REL_ "GenSigTimeoutTime" BU_SG_REL_ MFK SG_ 333 ACC_TA_Kurve_vDelta 500;
BA_REL_ "GenSigTimeoutTime" BU_SG_REL_ MFK SG_ 333 ACC_Abbiegewunsch 500;
BA_REL_ "GenSigTimeoutTime" BU_SG_REL_ MFK SG_ 333 ACC_Abbiegewunsch_Abstand 500;
BA_REL_ "GenSigTimeoutTime" BU_SG_REL_ MFK SG_ 768 ACC_Wunschgeschw_02 600;
BA_REL_ "GenSigTimeoutTime" BU_SG_REL_ MFK SG_ 768 ACC_Abstandsindex_02 600;
BA_REL_ "GenSigTimeoutTime" BU_SG_REL_ MFK SG_ 768 ACC_ENG_Texte 600;
BA_REL_ "GenSigTimeoutTime" BU_SG_REL_ MFK SG_ 768 ACC_Status_GRA_Modus 600;
BA_REL_ "GenSigTimeoutTime" BU_SG_REL_ MFK SG_ 64 AB_Front_Crash 500;
BA_REL_ "GenSigTimeoutTime" BU_SG_REL_ MFK SG_ 64 AB_Heck_Crash 500;
BA_REL_ "GenSigTimeoutTime" BU_SG_REL_ MFK SG_ 64 AB_SF_Crash 500;
BA_REL_ "GenSigTimeoutTime" BU_SG_REL_ MFK SG_ 64 AB_SB_Crash 500;
BA_REL_ "GenSigTimeoutTime" BU_SG_REL_ MFK SG_ 64 AB_Rollover_Crash 500;
BA_REL_ "GenSigTimeoutTime" BU_SG_REL_ MFK SG_ 64 AB_Systemfehler 500;
BA_REL_ "GenSigTimeoutTime" BU_SG_REL_ MFK SG_ 64 AB_Gurtwarn_VF 500;
BA_REL_ "GenSigTimeoutTime" BU_SG_REL_ MFK SG_ 64 AB_Gurtwarn_VB 500;
BA_REL_ "GenSigTimeoutTime" BU_SG_REL_ MFK SG_ 64 ASM_Masterzeit_02 500;
BA_REL_ "GenSigTimeoutTime" BU_SG_REL_ MFK SG_ 1312 AB_Gurtschloss_FA 2000;
BA_REL_ "GenSigTimeoutTime" BU_SG_REL_ MFK SG_ 1312 AB_Gurtschloss_BF 2000;
BA_REL_ "GenSigTimeoutTime" BU_SG_REL_ MFK SG_ 1312 AB_Gurtschloss_Reihe2_FA 2000;
BA_REL_ "GenSigTimeoutTime" BU_SG_REL_ MFK SG_ 1312 AB_Gurtschloss_Reihe2_MI 2000;
BA_REL_ "GenSigTimeoutTime" BU_SG_REL_ MFK SG_ 1312 AB_Gurtschloss_Reihe2_BF 2000;
BA_REL_ "GenSigTimeoutTime" BU_SG_REL_ MFK SG_ 1312 AB_Gurtschloss_Reihe3_FA 2000;
BA_REL_ "GenSigTimeoutTime" BU_SG_REL_ MFK SG_ 1312 AB_Gurtschloss_Reihe3_MI 2000;
BA_REL_ "GenSigTimeoutTime" BU_SG_REL_ MFK SG_ 1312 AB_Gurtschloss_Reihe3_BF 2000;
BA_REL_ "GenSigTimeoutTime" BU_SG_REL_ MFK SG_ 1349 AB_Gurtwarn_Reihe2_FA 2000;
BA_REL_ "GenSigTimeoutTime" BU_SG_REL_ MFK SG_ 1349 AB_Gurtwarn_Reihe2_BF 2000;
BA_REL_ "GenSigTimeoutTime" BU_SG_REL_ MFK SG_ 1349 AB_Gurtwarn_Reihe2_MI 2000;
BA_REL_ "GenSigTimeoutTime" BU_SG_REL_ MFK SG_ 1349 AB_Gurtwarn_Reihe3_FA 2000;
BA_REL_ "GenSigTimeoutTime" BU_SG_REL_ MFK SG_ 1349 AB_Gurtwarn_Reihe3_MI 2000;
BA_REL_ "GenSigTimeoutTime" BU_SG_REL_ MFK SG_ 1349 AB_Gurtwarn_Reihe3_BF 2000;
BA_REL_ "GenSigTimeoutTime" BU_SG_REL_ MFK SG_ 2527679722 AB_Gurtwarn_VM 2000;
BA_REL_ "GenSigTimeoutTime" BU_SG_REL_ MFK SG_ 1633 AAG_Anhaenger_erkannt 1000;
BA_REL_ "GenSigTimeoutTime" BU_SG_REL_ MFK SG_ 616 US_Fehler_HLS 500;
BA_REL_ "GenSigTimeoutTime" BU_SG_REL_ MFK SG_ 616 US_Fehler_HRS 500;
BA_REL_ "GenSigTimeoutTime" BU_SG_REL_ MFK SG_ 616 US_Fehler_VLS 500;
BA_REL_ "GenSigTimeoutTime" BU_SG_REL_ MFK SG_ 616 US_Fehler_VRS 500;
BA_REL_ "GenSigTimeoutTime" BU_SG_REL_ MFK SG_ 616 US_Links_01_Pos_X 500;
BA_REL_ "GenSigTimeoutTime" BU_SG_REL_ MFK SG_ 616 US_Links_01_Pos_Y 500;
BA_REL_ "GenSigTimeoutTime" BU_SG_REL_ MFK SG_ 616 US_Links_01_Valid 500;
BA_REL_ "GenSigTimeoutTime" BU_SG_REL_ MFK SG_ 616 US_Links_02_Pos_X 500;
BA_REL_ "GenSigTimeoutTime" BU_SG_REL_ MFK SG_ 616 US_Links_02_Pos_Y 500;
BA_REL_ "GenSigTimeoutTime" BU_SG_REL_ MFK SG_ 616 US_Links_02_Valid 500;
BA_REL_ "GenSigTimeoutTime" BU_SG_REL_ MFK SG_ 616 US_Rechts_01_Pos_X 500;
BA_REL_ "GenSigTimeoutTime" BU_SG_REL_ MFK SG_ 616 US_Rechts_01_Pos_Y 500;
BA_REL_ "GenSigTimeoutTime" BU_SG_REL_ MFK SG_ 616 US_Rechts_01_Valid 500;
BA_REL_ "GenSigTimeoutTime" BU_SG_REL_ MFK SG_ 616 US_Rechts_02_Pos_X 500;
BA_REL_ "GenSigTimeoutTime" BU_SG_REL_ MFK SG_ 616 US_Rechts_02_Pos_Y 500;
BA_REL_ "GenSigTimeoutTime" BU_SG_REL_ MFK SG_ 616 US_Rechts_02_Valid 500;
BA_REL_ "GenSigTimeoutTime" BU_SG_REL_ MFK SG_ 616 US_QAbstand_HLS 500;
BA_REL_ "GenSigTimeoutTime" BU_SG_REL_ MFK SG_ 616 US_Nichtverfuegbarkeit_HLS 500;
BA_REL_ "GenSigTimeoutTime" BU_SG_REL_ MFK SG_ 616 US_QAbstand_HRS 500;
BA_REL_ "GenSigTimeoutTime" BU_SG_REL_ MFK SG_ 616 US_Nichtverfuegbarkeit_HRS 500;
BA_REL_ "GenSigTimeoutTime" BU_SG_REL_ MFK SG_ 616 US_QAbstand_VLS 500;
BA_REL_ "GenSigTimeoutTime" BU_SG_REL_ MFK SG_ 616 US_Nichtverfuegbarkeit_VLS 500;
BA_REL_ "GenSigTimeoutTime" BU_SG_REL_ MFK SG_ 616 US_QAbstand_VRS 500;
BA_REL_ "GenSigTimeoutTime" BU_SG_REL_ MFK SG_ 616 US_Nichtverfuegbarkeit_VRS 500;
BA_REL_ "GenSigTimeoutTime" BU_SG_REL_ MFK SG_ 616 US_Datenalter_HLS 500;
BA_REL_ "GenSigTimeoutTime" BU_SG_REL_ MFK SG_ 616 US_Datenalter_HRS 500;
BA_REL_ "GenSigTimeoutTime" BU_SG_REL_ MFK SG_ 616 US_Datenalter_VLS 500;
BA_REL_ "GenSigTimeoutTime" BU_SG_REL_ MFK SG_ 616 US_Datenalter_VRS 500;
BA_REL_ "GenSigTimeoutTime" BU_SG_REL_ MFK SG_ 2527679661 AWV_Warnung 2000;
BA_REL_ "GenSigTimeoutTime" BU_SG_REL_ MFK SG_ 2527679661 AWV_Warnlevel 2000;
BA_REL_ "GenSigTimeoutTime" BU_SG_REL_ MFK SG_ 2536725248 BAP_REM_ASG_01_Header 800;
BA_REL_ "GenSigTimeoutTime" BU_SG_REL_ MFK SG_ 2536725249 BAP_REM_ASG_02_Header 500;
BA_REL_ "GenSigTimeoutTime" BU_SG_REL_ MFK SG_ 2536726273 BAP_TPA_ASG_02_Header 800;
BA_REL_ "GenSigTimeoutTime" BU_SG_REL_ MFK SG_ 870 Blinkmodi_02_CRC 5000;
BA_REL_ "GenSigTimeoutTime" BU_SG_REL_ MFK SG_ 870 Blinkmodi_02_BZ 5000;
BA_REL_ "GenSigTimeoutTime" BU_SG_REL_ MFK SG_ 870 BM_Warnblinken 5000;
BA_REL_ "GenSigTimeoutTime" BU_SG_REL_ MFK SG_ 870 BM_links 5000;
BA_REL_ "GenSigTimeoutTime" BU_SG_REL_ MFK SG_ 870 BM_rechts 5000;
BA_REL_ "GenSigTimeoutTime" BU_SG_REL_ MFK SG_ 870 SAL_TA_Blinken_Status 5000;
BA_REL_ "GenSigTimeoutTime" BU_SG_REL_ MFK120 SG_ 333 ACC_18_CRC 500;
BA_REL_ "GenSigTimeoutTime" BU_SG_REL_ MFK120 SG_ 333 ACC_18_BZ 500;
BA_REL_ "GenSigTimeoutTime" BU_SG_REL_ MFK120 SG_ 333 ACC_Status_ACC 500;
BA_REL_ "GenSigTimeoutTime" BU_SG_REL_ MFK120 SG_ 333 ACC_Tempolimitassistent_Ein 500;
BA_REL_ "GenSigTimeoutTime" BU_SG_REL_ MFK120 SG_ 333 ACC_Verkehrssinn 500;
BA_REL_ "GenSigTimeoutTime" BU_SG_REL_ MFK120 SG_ 333 ACC_TA_Kurve_Abstand 500;
BA_REL_ "GenSigTimeoutTime" BU_SG_REL_ MFK120 SG_ 333 ACC_TA_Kurve_vDelta 500;
BA_REL_ "GenSigTimeoutTime" BU_SG_REL_ MFK120 SG_ 333 ACC_Abbiegewunsch 500;
BA_REL_ "GenSigTimeoutTime" BU_SG_REL_ MFK120 SG_ 333 ACC_Abbiegewunsch_Abstand 500;
BA_REL_ "GenSigTimeoutTime" BU_SG_REL_ MFK120 SG_ 768 ACC_Wunschgeschw_02 600;
BA_REL_ "GenSigTimeoutTime" BU_SG_REL_ MFK120 SG_ 768 ACC_Abstandsindex_02 600;
BA_REL_ "GenSigTimeoutTime" BU_SG_REL_ MFK120 SG_ 768 ACC_ENG_Texte 600;
BA_REL_ "GenSigTimeoutTime" BU_SG_REL_ MFK120 SG_ 768 ACC_Status_GRA_Modus 600;
BA_REL_ "GenSigTimeoutTime" BU_SG_REL_ MFK120 SG_ 768 ACC_Texte_03 600;
BA_REL_ "GenSigTimeoutTime" BU_SG_REL_ MFK120 SG_ 64 Airbag_01_CRC 500;
BA_REL_ "GenSigTimeoutTime" BU_SG_REL_ MFK120 SG_ 64 Airbag_01_BZ 500;
BA_REL_ "GenSigTimeoutTime" BU_SG_REL_ MFK120 SG_ 64 AB_Front_Crash 500;
BA_REL_ "GenSigTimeoutTime" BU_SG_REL_ MFK120 SG_ 64 AB_Heck_Crash 500;
BA_REL_ "GenSigTimeoutTime" BU_SG_REL_ MFK120 SG_ 64 AB_SF_Crash 500;
BA_REL_ "GenSigTimeoutTime" BU_SG_REL_ MFK120 SG_ 64 AB_SB_Crash 500;
BA_REL_ "GenSigTimeoutTime" BU_SG_REL_ MFK120 SG_ 64 AB_Rollover_Crash 500;
BA_REL_ "GenSigTimeoutTime" BU_SG_REL_ MFK120 SG_ 64 AB_Crash_Int 500;
BA_REL_ "GenSigTimeoutTime" BU_SG_REL_ MFK120 SG_ 64 AB_Systemfehler 500;
BA_REL_ "GenSigTimeoutTime" BU_SG_REL_ MFK120 SG_ 64 AB_EDR_Trigger 500;
BA_REL_ "GenSigTimeoutTime" BU_SG_REL_ MFK120 SG_ 64 ASM_Masterzeit_02 500;
BA_REL_ "GenSigTimeoutTime" BU_SG_REL_ MFK120 SG_ 1312 AB_Gurtschloss_FA 2000;
BA_REL_ "GenSigTimeoutTime" BU_SG_REL_ MFK120 SG_ 1312 AB_Gurtschloss_BF 2000;
BA_REL_ "GenSigTimeoutTime" BU_SG_REL_ MFK120 SG_ 1312 AB_Gurtschloss_Reihe2_FA 2000;
BA_REL_ "GenSigTimeoutTime" BU_SG_REL_ MFK120 SG_ 1312 AB_Gurtschloss_Reihe2_MI 2000;
BA_REL_ "GenSigTimeoutTime" BU_SG_REL_ MFK120 SG_ 1312 AB_Gurtschloss_Reihe2_BF 2000;
BA_REL_ "GenSigTimeoutTime" BU_SG_REL_ MFK120 SG_ 1312 AB_Gurtschloss_Reihe3_FA 2000;
BA_REL_ "GenSigTimeoutTime" BU_SG_REL_ MFK120 SG_ 1312 AB_Gurtschloss_Reihe3_MI 2000;
BA_REL_ "GenSigTimeoutTime" BU_SG_REL_ MFK120 SG_ 1312 AB_Gurtschloss_Reihe3_BF 2000;
BA_REL_ "GenSigTimeoutTime" BU_SG_REL_ MFK120 SG_ 1633 AAG_Anhaenger_erkannt 1000;
BA_REL_ "GenSigTimeoutTime" BU_SG_REL_ MFK120 SG_ 616 US_QAbstand_HLS 500;
BA_REL_ "GenSigTimeoutTime" BU_SG_REL_ MFK120 SG_ 616 US_QAbstand_HRS 500;
BA_REL_ "GenSigTimeoutTime" BU_SG_REL_ MFK120 SG_ 616 US_QAbstand_VLS 500;
BA_REL_ "GenSigTimeoutTime" BU_SG_REL_ MFK120 SG_ 616 US_QAbstand_VRS 500;
BA_REL_ "GenSigTimeoutTime" BU_SG_REL_ MFK120 SG_ 2527679661 WBA_Warnblinken 2000;
BA_REL_ "GenSigTimeoutTime" BU_SG_REL_ MFK120 SG_ 2527679661 AWV_Warnung 2000;
BA_REL_ "GenSigTimeoutTime" BU_SG_REL_ MFK120 SG_ 870 Blinkmodi_02_CRC 5000;
BA_REL_ "GenSigTimeoutTime" BU_SG_REL_ MFK120 SG_ 870 Blinkmodi_02_BZ 5000;
BA_REL_ "GenSigTimeoutTime" BU_SG_REL_ MFK120 SG_ 870 BM_Warnblinken 5000;
BA_REL_ "GenSigTimeoutTime" BU_SG_REL_ MFK120 SG_ 870 BM_links 5000;
BA_REL_ "GenSigTimeoutTime" BU_SG_REL_ MFK120 SG_ 870 BM_rechts 5000;
BA_REL_ "GenSigTimeoutTime" BU_SG_REL_ MFK120 SG_ 870 SAL_TA_Blinken_Status 5000;
BA_REL_ "GenSigTimeoutTime" BU_SG_REL_ MIK SG_ 1349 AB_Belegung_VF_ext 2000;
BA_REL_ "GenSigTimeoutTime" BU_SG_REL_ MRR2023 SG_ 64 Airbag_01_CRC 500;
BA_REL_ "GenSigTimeoutTime" BU_SG_REL_ MRR2023 SG_ 64 Airbag_01_BZ 500;
BA_REL_ "GenSigTimeoutTime" BU_SG_REL_ MRR2023 SG_ 64 AB_Crash_Int 500;
BA_REL_ "GenSigTimeoutTime" BU_SG_REL_ MRR2023 SG_ 64 AB_Belegung_VF 500;
BA_REL_ "GenSigTimeoutTime" BU_SG_REL_ MRR2023 SG_ 64 AB_Gurtschloss_FA_ext 500;
BA_REL_ "GenSigTimeoutTime" BU_SG_REL_ MRR2023 SG_ 64 AB_Gurtschloss_FA_ext_aktiv 500;
BA_REL_ "GenSigTimeoutTime" BU_SG_REL_ MRR2023 SG_ 64 ASM_Masterzeit_02 500;
BA_REL_ "GenSigTimeoutTime" BU_SG_REL_ MRR2023 SG_ 1312 Airbag_02_CRC 2000;
BA_REL_ "GenSigTimeoutTime" BU_SG_REL_ MRR2023 SG_ 1312 Airbag_02_BZ 2000;
BA_REL_ "GenSigTimeoutTime" BU_SG_REL_ MRR2023 SG_ 1312 AB_Anprall_Seite_Beifahrer 2000;
BA_REL_ "GenSigTimeoutTime" BU_SG_REL_ MRR2023 SG_ 1312 AB_Anprall_FGS 2000;
BA_REL_ "GenSigTimeoutTime" BU_SG_REL_ MRR2023 SG_ 1312 AB_Anprall_Front_Beifahrer 2000;
BA_REL_ "GenSigTimeoutTime" BU_SG_REL_ MRR2023 SG_ 1312 AB_Anprall_Front_Fahrer 2000;
BA_REL_ "GenSigTimeoutTime" BU_SG_REL_ MRR2023 SG_ 1312 AB_Anprall_Seite_Fahrer 2000;
BA_REL_ "GenSigTimeoutTime" BU_SG_REL_ MRR2023 SG_ 1312 AB_Gurtschloss_FA 2000;
BA_REL_ "GenSigTimeoutTime" BU_SG_REL_ MRR2023 SG_ 1349 Airbag_04_CRC 2000;
BA_REL_ "GenSigTimeoutTime" BU_SG_REL_ MRR2023 SG_ 1349 Airbag_04_BZ 2000;
BA_REL_ "GenSigTimeoutTime" BU_SG_REL_ MRR2023 SG_ 1349 AB_Belegung_VF_ext 2000;
BA_REL_ "GenSigTimeoutTime" BU_SG_REL_ MRR2023 SG_ 1633 AAG_Anhaenger_erkannt 1000;
BA_REL_ "GenSigTimeoutTime" BU_SG_REL_ MRR2023 SG_ 1633 AAG_Bremslicht_H_def 1000;
BA_REL_ "GenSigTimeoutTime" BU_SG_REL_ MRR2023 SG_ 896 US_Sende_Modus 800;
BA_REL_ "GenSigTimeoutTime" BU_SG_REL_ MRR2023 SG_ 896 US_relevanter_Fehler 800;
BA_REL_ "GenSigTimeoutTime" BU_SG_REL_ MRR2023 SG_ 896 US_relevante_Nichtverfuegbarkeit 800;
BA_REL_ "GenSigTimeoutTime" BU_SG_REL_ MRR2023 SG_ 896 US_Freisicht_nio 800;
BA_REL_ "GenSigTimeoutTime" BU_SG_REL_ MRR2023 SG_ 896 US_blindness_detected 800;
BA_REL_ "GenSigTimeoutTime" BU_SG_REL_ MRR2023 SG_ 896 US_Freie_Weglaenge_Front_Typ 800;
BA_REL_ "GenSigTimeoutTime" BU_SG_REL_ MRR2023 SG_ 896 US_Freie_Weglaenge_Front 800;
BA_REL_ "GenSigTimeoutTime" BU_SG_REL_ MRR2023 SG_ 345 ARA_Status 1000;
BA_REL_ "GenSigTimeoutTime" BU_SG_REL_ MRR2023 SG_ 2536728320 BAP_REM2_ASG_01_Header 800;
VAL_ 333 ACC_DynErhoehung 0 "normale_Verzoegerungsdynamik" 1 "erhoehte_Verzoegerungsdynamik" ;
VAL_ 333 ACC_Freilaufstrategie_TSK 0 "Freilaufstr_nicht_angefordert" 1 "Freilaufstr_angefordert" ;
VAL_ 333 ACC_Sollbeschleunigung_02 2046 "Neutralwert" 2047 "Fehler" ;
VAL_ 333 ACC_Anfahren 0 "keine_Anforderung_Anfahren" 1 "Anforderung_Anfahren" ;
VAL_ 333 ACC_Anhalten 0 "kein_Anhalten_gewuenscht" 1 "Anhalten_gewuenscht" ;
VAL_ 333 ACC_Typ 0 "Basis_ACC" 1 "ACC_mit_FollowToStop" 2 "ACC_mit_StopAndGo" 3 "ACC_nicht_codiert" ;
VAL_ 333 ACC_Status_ACC 0 "ACC_OFF_Hauptschalter_aus" 1 "ACC_INIT" 2 "ACC_STANDBY" 3 "ACC_AKTIV_regelt" 4 "ACC_OVERRIDE" 5 "ACC_Abschaltreaktion" 6 "reversibler_Fehler_im_ACC_System" 7 "irreversibler_Fehler_im_ACC_System" ;
VAL_ 333 ACC_Minimale_Bremsung 0 "Anforderung_Minimale_Bremsung_nicht_aktiv" 1 "Anforderung_Minimale_Bremsung_aktiv" ;
VAL_ 333 ACC_Anhalteweg 2046 "Neutralwert" 2047 "Fehler" ;
VAL_ 333 ACC_Anforderung_HMS 0 "keine_Anforderung" 1 "halten" 2 "parken" 3 "halten_Standby" 4 "anfahren" 5 "Loesen_ueber_Rampe" 7 "HMS_uebernehmen" ;
VAL_ 333 ACC_Freilauf_Info 0 "Freilauf_freigegeben" 1 "Weiches_Veto_uebertippbar" 2 "Hartes_Veto_Abbruch" 3 "Freilauf_Anforderung" ;
VAL_ 333 ACC_Tempolimitassistent_Ein 0 "Tempolimitassistent_aus" 1 "Tempolimitassistent_ein" ;
VAL_ 333 ACC_FoD_Status 0 "Init" 1 "Funktion_inaktiv" 2 "Funktion_aktiv" ;
VAL_ 333 ACC_Verkehrssinn 0 "Init" 1 "Linksverkehr" 2 "Rechtsverkehr" 3 "Unbekannt" ;
VAL_ 333 ACC_TA_Kurve_Abstand 61 "groesser_300m" 62 "Init_keine_Kurvenanpassung" ;
VAL_ 333 ACC_TA_Kurve_vDelta 11 "Init_keine_Kurvenanpassung" ;
VAL_ 333 RDR_VBEG_Anforderung 0 "INIT" ;
VAL_ 333 ACC_Abbiegewunsch 0 "Init_kein_Abbiegewunsch" 1 "Abbiegewunsch_rechts" 2 "Abbiegewunsch_links" ;
VAL_ 333 ACC_Abbiegewunsch_Abstand 511 "Kein_Abbiegewunsch" ;
VAL_ 333 ACC_Sollbeschleunigung_AD 4094 "Neutralwert" 4095 "Fehler" ;
VAL_ 333 MPPmod_1_Segment 0 "Keine_Modifikation" 1 "Reset" ;
VAL_ 333 MPPmod_2_Segment 0 "Keine_Modifikation" 1 "Reset" ;
VAL_ 333 MPPmod_3_Segment 0 "Keine_Modifikation" 1 "Reset" ;
VAL_ 333 MPPmod_4_Segment 0 "Keine_Modifikation" 1 "Reset" ;
VAL_ 333 RDR_v_ueber_Grund 4091 "Init" 4092 "temporaer_nicht_verfuegbar" 4093 "Fehler" ;
VAL_ 333 RDR_v_ueber_Grund_Genauigkeit 61 "groesser_6km_h" 62 "Init" 63 "Fehler" ;
VAL_ 333 RDR_v_ueber_Grund_Fahrtrichtung 0 "vorwaerts" 1 "rueckwaerts" 2 "init_unbekannt" ;
VAL_ 768 ACC_FzgStatus_Kamerafusion 0 "keine_Anzeige" 1 "ACC_red_Objekterkennung" 2 "ACC_TA_red_Objekterkennung" ;
VAL_ 768 ACC_FzgStatus_Anfahrbereitschaft 0 "keine_Anzeige" 1 "ACC_red_Anfahrbereitschaft" 2 "ACC_TA_red_Anfahrbereitschaft" ;
VAL_ 768 ACC_FzgStatus_Fehleranzeige 0 "keine_Anzeige" 1 "ACC_Stoerung" 2 "ACC_und_GRA_Stoerung" 3 "ACC_nicht_verfuegbar" 4 "ACC_und_GRA_nicht_verfuegbar" 5 "ACC_keine_Sensorsicht" ;
VAL_ 768 ACC_ENG_Texte_02 0 "keine_Anzeige" 1 "keine_Laenderverfuegbarkeit" 2 "ACC_Vor_Strecke_n_verf" 3 "ACC_TA_Vor_Strecke_n_verf" 4 "ACC_Vor_Geschw_n_verf" 5 "ACC_TA_Vor_Geschw_n_verf" 6 "ACC_Vor_Strecke_Geschw_n_verf" 7 "ACC_TA_Vor_Strecke_Geschw_n_verf" ;
VAL_ 768 ACC_Tempolimit 0 "keine_Anzeige" 1 "5_zulHoechstgeschw" 2 "7_zulHoechstgeschw" 3 "10_zulHoechstgeschw" 4 "15_zulHoechstgeschw" 5 "20_zulHoechstgeschw" 6 "25_zulHoechstgeschw" 7 "30_zulHoechstgeschw" 8 "35_zulHoechstgeschw" 9 "40_zulHoechstgeschw" 10 "45_zulHoechstgeschw" 11 "50_zulHoechstgeschw" 12 "55_zulHoechstgeschw" 13 "60_zulHoechstgeschw" 14 "65_zulHoechstgeschw" 15 "70_zulHoechstgeschw" 16 "75_zulHoechstgeschw" 17 "80_zulHoechstgeschw" 18 "85_zulHoechstgeschw" 19 "90_zulHoechstgeschw" 20 "95_zulHoechstgeschw" 21 "100_zulHoechstgeschw" 22 "110_zulHoechstgeschw" 23 "120_zulHoechstgeschw" 24 "130_zulHoechstgeschw" 25 "140_zulHoechstgeschw" 26 "150_zulHoechstgeschw" 27 "160_zulHoechstgeschw" 28 "200_zulHoechstgeschw" 30 "250_zulHoechstgeschw" 31 "Ende_zulHoechstgeschw" ;
VAL_ 768 ACC_Wunschgeschw_Farbe 0 "Grundfarbe" 1 "Farbe_1" ;
VAL_ 768 ACC_Warnung_Verkehrszeichen_1 0 "keine_Warnung_Initialwert" 1 "Warnung" ;
VAL_ 768 ACA_Querfuehrung 0 "keine_Anzeige_oder_init" 1 "passiv" 2 "aktiv" 3 "Warnung" ;
VAL_ 768 ACC_Wunschgeschw_Farbe_02 0 "Grundfarbe" 1 "Farbe_1" 2 "Farbe_2" 3 "Farbe_3" ;
VAL_ 768 ACC_Regelung_AIO 0 "Regelung_Ampel_nicht_aktiv" 1 "Regelung_Ampel_aktiv" ;
VAL_ 768 ACC_Wunschgeschw_02 1023 "keine_Anzeige" ;
VAL_ 768 ACC_Abstandsindex_02 0 "Audi (Init), VW (passiv/aktiv_Freifahrt)" 1022 "aus_passiv" 1023 "aktiv_Freifahrt" ;
VAL_ 768 ACC_Display_Prio 0 "hoechste_Prio" 1 "mittlere_Prio" 2 "geringe_Prio" 3 "keine_Prio" ;
VAL_ 768 ACC_rel_Objekt_Zusatzanz 0 "keine Anzeige" 1 "Relevantes_Objekt_erkannt" 2 "Relevantes_Objekt_Abstandswarnung" ;
VAL_ 768 ACC_Gesetzte_Zeitluecke 0 "keine_Anzeige" 1 "Zeitluecke_1" 2 "Zeitluecke_2" 3 "Zeitluecke_3" 4 "Zeitluecke_4" 5 "Zeitluecke_5" 6 "nicht_definiert" 7 "nicht_definiert" ;
VAL_ 768 ACC_Optischer_Fahrerhinweis 0 "optischer_Fahrerhinweis_AUS" 1 "optischer_Fahrerhinweis_EIN" ;
VAL_ 768 ACC_EGO_Fahrzeug 0 "keine_Anzeige" 1 "aktiv" 2 "Warnung" 3 "aktiv_stop" 4 "passiv" ;
VAL_ 768 ACC_Relevantes_Objekt_02 0 "keine_Anzeige" 1 "Relevantes_Objekt_erkannt" 2 "Relevantes_Objekt_Warnung" 3 "passiv" ;
VAL_ 768 ACC_Wunschgeschw_erreicht 0 "Wunschgeschwindigkeit_nicht_erreicht" 1 "Wunschgeschwindigkeit_erreicht" ;
VAL_ 768 ACC_Anzeige_Zeitluecke 0 "Anzeige_Zeitluecke_nicht_angefordert" 1 "Anzeige_Zeitluecke_angefordert" ;
VAL_ 768 ACC_Texte_Primaeranz_03 0 "keine_Anzeige" 1 "ACC_anfahrbereit" 2 "VDA_ACC_Symbol_YYY_kmh_mph" 3 "Kurven_Symbol_YYY_kmh_mph" 4 "Tempolimit_Symbol_YYY_kmh_mph" 5 "Kreuzungs_Symbol" 6 "Kreisverkehr_Symbol" 7 "Gefaelle_Symbol" 8 "Autobahnausfahrt_Symbol" 9 "Stauende_Symbol" 10 "Engstelle_Symbol" 11 "Tuer_offen" 12 "Fahrer_Gurtschloss_offen" 13 "praediktive_Regelung_Aktiv" 14 "Ampel_vertikal" 15 "Ampel_horizontal" 16 "STP_verfuegbar" 17 "GRA_Symbol" 18 "ACC_Freifahrt_Symbol" 19 "ACC_Folgefahrt_Symbol" ;
VAL_ 768 ACC_Texte_Zusatzanz_03 0 "keine_Anzeige" 1 "ACC_AUS" 2 "Standby" 3 "UEBERTRETEN" 4 "ABSTAND" 5 "Fahrprogramm_1" 6 "Fahrprogramm_2" 7 "Fahrprogramm_3" 8 "Fahrprogramm_4" 9 "Fahrprogramm_5" 10 "Fahrprogramm_6" 11 "ACHTUNG" 12 "STA_verfuegbar" 13 "Engstelle" 14 "RUV_aktiv_Rechtsverkehr" 15 "RUV_aktiv_Linksverkehr" 16 "STP_Verfuegbar" ;
VAL_ 768 STA_Primaeranz 0 "keine_Anzeige" 1 "STA_standby" 2 "STA_aktiv" 3 "STA_Warnung" ;
VAL_ 768 ACC_Anzeige_Objektmarkierung 0 "keine_Anzeige" 1 "keine_Kritikalitaet" 8 "mittlere_Kritikalitaet" 15 "hohe_Kritikalitaet" ;
VAL_ 768 ACC_Regelgeschw 1023 "keine_Anzeige" ;
VAL_ 768 ACC_Einheit_maxSetzgeschw 0 "kmh" 1 "mph" ;
VAL_ 768 ACC_maxSetzgeschw 511 "Init_Neutralwert" ;
VAL_ 768 ACC_Tempolimit_Einheit 0 "kmh_init" 1 "mph" ;
VAL_ 768 ACC_RUV 0 "keine_Anzeige" 1 "RUV_aktiv_Rechtsverkehr" 2 "RUV_aktiv_Linksverkehr" ;
VAL_ 768 ACC_Tachokranz 0 "Tachokranz_nicht_beleuchtet" 1 "Tachokranz_beleuchtet" ;
VAL_ 768 ACC_Typ_Tachokranz_unten 0 "LEDs_an" 1 "LEDs_aus" ;
VAL_ 768 ACC_ENG_Texte 0 "keine_Anzeige" 1 "keine_Laenderverfuegbarkeit" 2 "nicht_verfuegbar" 3 "Geschwindigkeitsgrenze" ;
VAL_ 768 ACC_Status_GRA_Modus 0 "GRA_Modus_nicht_verfuegbar" 1 "GRA_Modus_verfuegbar_nicht_aktiv" 2 "GRA_Modus_verfuegbar_aktiv" ;
VAL_ 768 ACA_Querfuehrung_Texte 0 "keine_Anzeige" 1 "nicht_verfuegbar" 2 "keine_Sensorsicht" 3 "Fahreruebernahme" ;
VAL_ 768 ACA_Hinweistexte 0 "keine_Anzeige" 1 "QF_eingeschaltet" 2 "QF_ausgeschaltet" ;
VAL_ 768 ACC_FoD_Status 0 "Init" 1 "Funktion_inaktiv" 2 "Funktion_aktiv" ;
VAL_ 768 ACC_Status_Anzeige 0 "ACC_GRA_Hauptschalter_aus" 1 "ACC_in_Init_nicht_bei_GRA" 2 "ACC_GRA_passiv" 3 "ACC_GRA_aktiv" 4 "ACC_GRA_im_Hintergrund_uebertreten" 5 "ACC_GRA_Abschaltreaktion" 6 "ACC_reversibel_aus_nicht_bei_GRA" 7 "ACC_GRA_irreversibel_aus" ;
VAL_ 768 ACC_Akustik_03 0 "keine_Akustik" 1 "niederpriore_Akustik" 2 "mittelpriore_Akustik" 3 "hochpriore_Akustik" 4 "hochpriore_Dauerakustik" 5 "hochpriore_Dauerakustik_02" ;
VAL_ 768 ACC_Texte_02 0 "keine_Anzeige" 1 "ACC_zurzeit_nicht_verfuegbar" 2 "ACC_Stoerung" 3 "ACC_keine_Sensorsicht" 4 "ACC_Steigung_zu_gross" 5 "ACC_nur_in_Fahrstufe_verfuegbar" 6 "ACC_Parkbremse_betaetigt" 7 "ACC_ESP_Eingriff" 8 "ACC_HDC_betaetigt" 9 "ACC_Geschwindigkeitsgrenze" 10 "ACC_Schalthebelposition" 11 "ACC_Drehzahl" 12 "ACC_Kupplung_betaetigt" 13 "ACC_ESC_aus" 14 "ACC_Bitte_uebernehmen" 15 "ACC_Aktivierverhinderung" 16 "ACC_eingeschraenkte_Funktion" 17 "ACC_Manoevrierassistent_aktiv" 18 "ACC_Parkassistent_aktiv" 19 "ACC_Stehendes_Objekt_voraus" 20 "ACC_aus" 21 "ACC_startet" 22 "ACC_Tuer_offen" 23 "ACC_Fahrer_Gurtschloss_offen" 25 "ACC_Abschaltung" 26 "ACC_Charisma_Modus_inkompatibel" 27 "ACC_verfuegbar" 28 "ACC_und_GRA_nicht_verfuegbar" 29 "Fehler_ACC_und_GRA" 30 "GRA_deaktiviert" 31 "keine_Abstandsregelung" 32 "GRA_zurzeit_nicht_verfuegbar" 33 "Fehler_GRA" 34 "ACC_nicht_ueber_FOD_freigeschalt" 35 "Fahrersitz_nicht_belegt" ;
VAL_ 768 ACC_Status_Stauende 0 "deaktiviert" 1 "aktiviert" ;
VAL_ 768 STA_Texte 0 "keine_Anzeige" 1 "STA_nicht_verfuegbar" 2 "STA_Fahreruebernahme" 3 "STA_Constant_brake_mode" 4 "STA_Gurtschloss_nicht_gesteckt" 5 "STA_Fahrzeugeschw_zu_hoch" 6 "STA_Freifahrt" 7 "STA_Systemgrenze" ;
VAL_ 768 AbstWarn_LRR_FAS_Fkt_Status 0 "Init" 1 "Funktion_Ist_Ein" 2 "Funktion_Ist_Aus" 3 "Fehler" ;
VAL_ 768 STA_Zusatzanz 0 "keine_Anzeige" 1 "STA_verfuegbar" 2 "STA_aktiv" 3 "STA_Warnung" ;
VAL_ 768 FAS_Licht_Anf 0 "keine_Anforderung" 1 "Anforderung" ;
VAL_ 768 ACC_Texte_Sekundaeranz_03 0 "Keine_Anzeige" 1 "Kurve_voraus" 2 "Tempolimit_erkannt" 3 "Tempolimit_voraus" 4 "Kreuzung_voraus" 5 "Kreisverkehr_voraus" 6 "Stauende_voraus" 7 "Anfahrbereit" 8 "Ampel_horizontal_voraus" 9 "Ampel_vertikal_voraus" 10 "Stoppschild_voraus" 11 "Ampel_horizontal_erkannt" 12 "Ampel_vertikal_erkannt" 13 "Vorfahrt_beachten_voraus" 14 "Bumper_voraus" 15 "Kuppe_voraus" 16 "Hindernis_erkannt" 17 "TA_Anfahrbereit" 18 "TA_Hindernis_erkannt" 19 "Rechtskurve_voraus" 20 "Linkskurve_voraus" ;
VAL_ 768 ACC_Modus_Pop_Up 0 "keine_Anzeige" 1 "ACC_ausgewaehlt" 2 "GRA_ausgewaehlt" ;
VAL_ 768 ACC_Statusicon 0 "ACC_GRA_deaktiviert" 1 "ACC_init" 2 "ACC_passiv_FreeMode" 3 "ACC_passiv_FollowMode" 4 "ACC_aktiv_FreeMode" 5 "ACC_aktiv_FollowMode" 6 "ACC_override_FreeMode" 7 "ACC_override_FollowMode" 8 "ACC_reversibler_Fehler" 9 "ACC_irreversibler_Fehler" 10 "GRA_Modus_passiv" 11 "GRA_Modus_aktiv" 12 "GRA_override" 13 "GRA_reversibler_Fehler" 14 "GRA_irreversibler_Fehler" 15 "GRA_Init" ;
VAL_ 768 ACC_Anzeige_Objektregelung 0 "Keine_Anzeige" 1 "Linkes_Nebenspurobjekt" 2 "Rechtes_Nebenspurobjekt" 3 "Direktes_Zielobjekt" 4 "Tempolimit" 5 "Kurve" 6 "links_Kurve" 7 "rechts_Kurve" 8 "Kreuzung" 9 "Kreisverkehr" 10 "Autobahnabfahrt_auffahrt" 11 "Stauende" 12 "Engstelle" 13 "Gefaelle" 14 "Steigung" 15 "Kuppe_Bumper" 16 "Ampel_horizontal" 17 "Ampel_vertikal" 18 "Bahnuebergang" 19 "praediktive_Regelung_aktiv" ;
VAL_ 768 ACC_Typ_LNS 0 "invalid" 1 "Fussgaenger" 2 "LKW" 3 "PKW" 4 "Motorrad" 5 "Radfahrer" ;
VAL_ 768 ACC_Typ_RNS 0 "invalid" 1 "Fussgaenger" 2 "LKW" 3 "PKW" 4 "Motorrad" 5 "Radfahrer" ;
VAL_ 768 ACC_Typ_WZO 0 "invalid" 1 "Fussgaenger" 2 "LKW" 3 "PKW" 4 "Motorrad" 5 "Radfahrer" ;
VAL_ 768 ACC_Abstand_WZO 0 "keine_Anzeige" ;
VAL_ 768 ACC_Abstand_RNS 0 "keine_Anzeige" ;
VAL_ 768 ACC_Abstand_LNS 0 "keine_Anzeige" ;
VAL_ 768 ACC_Texte_03 0 "keine_Anzeige" 1 "ACC_nicht_ueber_FOD_freigeschalt" 2 "ACC_auswaehlen" 3 "ACC_verfuegbar" 4 "ACC_startet" 5 "GRA_startet" 6 "Hauptschalter_betaetigen" 7 "ACC_Stoerung" 8 "ACC_und_GRA_Stoerung" 9 "ACC_nicht_verfuegbar" 10 "ACC_und_GRA_nicht_verfuegbar" 11 "ACC_na_keine_Sensorsicht" 12 "ACC_na_Bremse_betaetigen" 13 "ACC_na_Steigung_zu_gross" 14 "ACC_na_Gefaelle_zu_gross" 15 "ACC_na_Parkbremse_betaetigt" 16 "GRA_na_Parkbremse_betaetigt" 17 "ACC_na_Bremse_betaetigt" 18 "GRA_na_Bremse_betaetigt" 19 "ACC_na_Fahrer_abwesend" 20 "ACC_na_Frontklappe_offen" 21 "GRA_na_Frontklappe_offen" 22 "ACC_na_Tuer_offen" 23 "GRA_na_Tuer_offen" 24 "ACC_na_WBA_aktiv" 25 "GRA_na_WBA_aktiv" 26 "ACC_na_Parkassistent_aktiv" 27 "GRA_na_Parkassistent_aktiv" 28 "ACC_na_HDC_betaetigt" 29 "GRA_na_HDC_betaetigt" 30 "ACC_na_ESC_Eingriff" 31 "GRA_na_ESC_Eingriff" 32 "ACC_na_nur_in_Fahrstufe_verfuegb" 33 "GRA_na_nur_in_Fahrstufe_verfuegb" 34 "ACC_na_Rueckwaertsgang_eingelegt" 35 "GRA_na_Rueckwaertsgang_eingelegt" 36 "ACC_na_rueckwaertsrollen" 37 "ACC_na_Fahrbereitschaft" 38 "ACC_na_Fzg_starten" 39 "GRA_na_Fzg_starten" 40 "ACC_na_Doppelbetaetigung" 41 "GRA_na_Doppelbetaetigung" 42 "ACC_na_Gangempfehlung" 43 "GRA_na_Gangempfehlung" 44 "ACC_na_zu_grosse_Verzoegerung" 45 "GRA_na_zu_grosse_Verzoegerung" 46 "GRA_na_Geschwindigkeitsgrenze" 47 "ACC_abg_Steigung_zu_gross" 48 "ACC_abg_Gefaelle_zu_gross" 49 "ACC_abg_Stillstand_verlassen" 50 "ACC_abg_keine_Sensorsicht" 51 "ACC_abg_nicht_fahrbereit" 52 "GRA_abg_nicht_fahrbereit" 53 "ACC_abg_Parkbremse_betaetigt" 54 "GRA_abg_Parkbremse_betaetigt" 55 "ACC_abg_ESC_Eingriff" 56 "GRA_abg_ESC_Eingriff" 57 "ACC_abg_ESC_aus" 58 "GRA_abg_ESC_aus" 59 "ACC_abg_Rueckwaertsgang_eingeleg" 60 "GRA_abg_Rueckwaertsgang_eingeleg" 61 "ACC_abg_nur_in_Fahrstufe_verfueg" 62 "GRA_abg_nur_in_Fahrstufe_verfueg" 63 "ACC_abg_Fahrer_abwesend" 64 "GRA_abg_Fahrer_abwesend" 65 "ACC_abg_Frontklappe_offen" 66 "GRA_abg_Frontklappe_offen" 67 "ACC_abg_Tuer_offen" 68 "GRA_abg_Tuer_offen" 69 "ACC_abg_WBA_aktiv" 70 "GRA_abg_WBA_aktiv" 71 "ACC_abg_Gangempfehlung" 72 "GRA_abg_Gangempfehlung" 73 "ACC_aus" 74 "GRA_aus" 75 "GRA_abg_Geschwindigkeitsgrenze" 76 "keine_Abstandsregelung" 77 "TA_startet" 78 "TA_na_Bremse_betaetigen" 79 "TA_na_Steigung_zu_gross" 80 "TA_na_Gefaelle_zu_gross" 81 "TA_na_Parkbremse_betaetigt" 82 "TA_na_Bremse_betaetigt" 83 "TA_na_Fahrer_abwesend" 84 "TA_na_Frontklappe_offen" 85 "TA_na_Tuer_offen" 86 "TA_na_WBA_aktiv" 87 "TA_na_Parkassistent_aktiv" 88 "TA_na_HDC_betaetigt" 89 "TA_na_ESC_Eingriff" 90 "TA_na_nur_in_Fahrstufe_verfuegb" 91 "TA_na_Rueckwaertsgang_eingelegt" 92 "TA_na_rueckwaertsrollen" 93 "TA_na_Fahrbereitschaft" 94 "TA_na_Fzg_starten" 95 "TA_na_Doppelbetaetigung" 96 "TA_na_Gangempfehlung" 97 "TA_na_zu_grosse_Verzoegerung" 98 "TA_abg_Steigung_zu_gross" 99 "TA_abg_Gefaelle_zu_gross" 100 "TA_abg_Stillstand_verlassen" 101 "TA_abg_nicht_fahrbereit" 102 "TA_abg_Parkbremse_betaetigt" 103 "TA_abg_ESC_Eingriff" 104 "TA_abg_ESC_aus" 105 "TA_abg_Rueckwaertsgang_eingeleg" 106 "TA_abg_nur_in_Fahrstufe_verfueg" 107 "TA_abg_Fahrer_abwesend" 108 "TA_abg_Frontklappe_offen" 109 "TA_abg_Tuer_offen" 110 "TA_abg_WBA_aktiv" 111 "TA_abg_Gangempfehlung" 112 "TA_Hauptschalter_betaetigen" 113 "GRA_nicht_verfuegbar" 114 "GRA_Stoerung" 115 "ACC_na_zurzeit_nicht_aktivierbar" 116 "GRA_na_zurzeit_nicht_aktivierbar" 117 "TA_na_zurzeit_nicht_aktivierbar" 118 "ACC_abg_Geschwindigkeitsgrenze" 119 "TA_abg_Geschwindigkeitsgrenze" 120 "ACC_abg_HDC_Eingriff" 121 "GRA_abg_HDC_Eingriff" 122 "TA_abg_HDC_Eingriff" 123 "ACC_abg_Kupplung_betaetigt" 124 "GRA_abg_Kupplung_betaetigt" 125 "TA_abg_Kupplung_betaetigt" 126 "ACC_na_Geschwindigkeitsgrenze" 127 "TA_na_Geschwindigkeitsgrenze" ;
VAL_ 768 ACC_iBoost_Anzeige 0 "keine_Anzeige" 1 "iBoost_aktiv_Freifahrt" 2 "iBoost_aktiv_Folgefahrt_verz" 3 "iBoost_aktiv_Folgefahrt_beschl" ;
VAL_ 768 ACC_Texte_Sekundaeranz_02 0 "Keine_Anzeige" 1 "Zielfahrzeug_erkannt" 2 "Sensorsicht" 3 "Anfahrbereit" 4 "Tempolimit_voraus" 5 "Tempolimit_erkannt" 6 "Kurve_voraus" 7 "rechts_Kurve_voraus" 8 "links_Kurve_voraus" 9 "Kreuzung_voraus" 10 "Kreisverkehr_voraus" 11 "Autobahnabfahrt_auffahrt_voraus" 12 "Stauende_voraus" 13 "Engstelle_voraus" 14 "Gefaelle_voraus" 15 "Steigung_voraus" 16 "Kuppe_Bumper_voraus" 17 "Ampel_horizontal_voraus" 18 "Ampel_vertikal_voraus" 19 "Bahnuebergang_voraus" ;
VAL_ 768 ACC_Sollabstand_1 0 "keine_Anzeige" ;
VAL_ 768 ACC_Sollabstand_2 0 "keine_Anzeige" ;
VAL_ 768 ACC_Sollabstand_3 0 "keine_Anzeige" ;
VAL_ 768 ACC_Sollabstand_4 0 "keine_Anzeige" ;
VAL_ 768 ACC_Sollabstand_5 0 "keine_Anzeige" ;
VAL_ 2197378135 ACC_Sollbeschleunigung_AD 4094 "Neutralwert" 4095 "Fehler" ;
VAL_ 2527679682 ACC_ASM_Ereignis 0 "No_Event" 255 "ASM_Trigger" ;
VAL_ 2527679682 ACC_ASM_Zeitstempel_02 255 "Init" ;
VAL_ 64 AB_RGS_Anst 4 "aktiv_Niveau_1" 5 "aktiv_Niveau_2" 6 "aktiv_Niveau_3" 7 "aktiv_Niveau_4" 8 "deaktiviert" ;
VAL_ 64 AB_Front_Crash 0 "kein_Front_Crash" 1 "Front_Crash" ;
VAL_ 64 AB_Heck_Crash 0 "kein_Heck_Crash" 1 "Heck_Crash" ;
VAL_ 64 AB_SF_Crash 0 "kein_Seiten_Crash_Fahrer" 1 "Seiten_Crash_Fahrer" ;
VAL_ 64 AB_SB_Crash 0 "kein_Seiten_Crash_Beifahrer" 1 "Seiten_Crash_Beifahrer" ;
VAL_ 64 AB_Rollover_Crash 0 "kein_Rollover" 1 "Rollover" ;
VAL_ 64 AB_Crash_Int 0 "kein_Crash" 1 "Crash_Intensitaet_1" 2 "Crash_Intensitaet_2_(nur_Stellgliedtest_MLB_B8)" 3 "Crash_Intensitaet_2_(nur_D4_C7_Colorado_NF_PAG__Crash_im_MLB_B8)" 4 "Crash_Intensitaet_3_(alt_VW/AUDI__Stellgliedtest_MLB_B8)" 5 "Crash_Intensitaet_3_(alt_PAG)" 7 "Crash_Intensitaet_3" ;
VAL_ 64 AB_Lampe 0 "Aus" 1 "Ein" ;
VAL_ 64 AB_Deaktiviert 0 "aktiv" 1 "deaktiviert" ;
VAL_ 64 AB_VB_deaktiviert 0 "Beifahrerairbag_aktiv" 1 "Beifahrerairbag_deaktiviert" ;
VAL_ 64 AB_Systemfehler 0 "kein_Fehler" 1 "Airbag_Systemfehler" ;
VAL_ 64 AB_Diagnose 0 "nicht_in_Diagnose" 1 "in_Diagnose" ;
VAL_ 64 AB_Stellgliedtest 0 "nicht_im_Stellgliedtest" 1 "Airbag_im_Stellgliedtest" ;
VAL_ 64 AB_Erh_Auf_VB 0 "keine_Anzeige" 1 "Beifahrerairbag_deaktiviert" 2 "Beifahrerairbag_aktiviert" 3 "nicht_definiert" ;
VAL_ 64 AB_Gurtwarn_VF 0 "keine_Warnung" 1 "Gurtwarnung_ausloesen" ;
VAL_ 64 AB_Gurtwarn_VB 0 "keine_Warnung" 1 "Gurtwarnung_ausloesen" ;
VAL_ 64 AB_Anzeige_Fussg 0 "keine_FSG_Aktion_ausgeloest" 1 "Motorhaube_offen" 2 "Systemfehler" ;
VAL_ 64 AB_Texte_AKS 0 "keine_AKS_Ausloesung" 1 "AKS_ausgeloest" 2 "AKS_Systemfehler" ;
VAL_ 64 AB_PAO_Leuchte_Anf 0 "Leuchte_ausschalten" 1 "Leuchte_einschalten" ;
VAL_ 64 AB_MKB_gueltig 0 "Multikollisionsbremsung_nicht_freigeschaltet" 1 "Multikollisionsbremsung_freigeschaltet" ;
VAL_ 64 AB_MKB_Anforderung 0 "Multikollisionsbremsung_nicht_angefordert" 1 "Multikollisionsbremsung_angefordert" ;
VAL_ 64 AB_Versorgungsspannung 0 "plausibel" 1 "unplausibel" ;
VAL_ 64 AB_Deaktivierung_HV 0 "keine_Deaktivierung" 1 "Deaktivierung_1" 2 "Deaktivierung_2" 3 "Deaktivierung_3" 4 "Deaktivierung_4" 5 "Deaktivierung_5" 6 "Deaktivierung_6" 7 "Fehler" ;
VAL_ 64 AB_EDR_Trigger 0 "No_Event" 1 "Start_Event" 2 "NonDeployment_Event" 3 "Deployment_Event" ;
VAL_ 64 AB_Belegung_VF 0 "nicht_verfuegbar" 1 "Fehler" 2 "nicht_belegt" 3 "belegt" ;
VAL_ 64 AB_Gurtschloss_FA_ext 0 "nicht_verbaut" 1 "reserviert" 2 "nicht_gesteckt" 3 "gesteckt" 4 "dauerhaft_nicht_gesteckt" 5 "dauerhaft_gesteckt" 6 "Init" 7 "Fehler" ;
VAL_ 64 AB_Gurtschloss_FA_ext_aktiv 0 "inaktiv" 1 "aktiv" ;
VAL_ 64 AB_eCS_Error 0 "keine_Anzeige" 1 "Anzeige_anfordern" ;
VAL_ 64 ASM_Masterzeit_02 255 "Init" ;
VAL_ 1312 LoGeWa_Event_Kombiwarnung 0 "Init" 1 "Unfall" 2 "Traktionsverlust" 3 "Panne" 4 "Sichtbehinderung" 5 "Aquaplaning" ;
VAL_ 1312 AB_Anforderung_eCall 0 "keine_Anforderung" 1 "Anforderung" ;
VAL_ 1312 AB_Anprall_Seite_Beifahrer 0 "kein_Anprall" 1 "Anprall_erkannt" ;
VAL_ 1312 AB_Anprall_FGS 0 "kein_Anprall" 1 "Anprall_erkannt" ;
VAL_ 1312 AB_Anprall_Front_Beifahrer 0 "kein_Anprall" 1 "Anprall_erkannt" ;
VAL_ 1312 AB_Anprall_Front_Fahrer 0 "kein_Anprall" 1 "Anprall_erkannt" ;
VAL_ 1312 AB_Wickelklappung_Reihe2_MI 0 "nicht_verbaut" 1 "nicht_verfuegbar__Fehler_oder_Init" 2 "nicht_verriegelt" 3 "verriegelt" ;
VAL_ 1312 AB_Belegung_VB 0 "nicht_verfuegbar" 1 "Fehler" 2 "nicht_belegt" 3 "belegt" ;
VAL_ 1312 AB_Abschaltanf_SIH_BF 0 "Normalbetrieb" 1 "Abschaltung_angefordert" ;
VAL_ 1312 AB_Anprall_Seite_Fahrer 0 "kein_Anprall" 1 "Anprall_erkannt" ;
VAL_ 1312 SC_PAO_Schriftzug_Anf 0 "LED aus" 1 "LED an" 2 "LED blinken" 3 "reserviert" ;
VAL_ 1312 SC_PAO_ON_Anf 0 "LED aus" 1 "LED an" 2 "LED blinken" 3 "reserviert" ;
VAL_ 1312 SC_PAO_OFF_Anf 0 "LED aus" 1 "LED an" 2 "LED blinken" 3 "reserviert" ;
VAL_ 1312 AB_Crashschwere 0 "kein_Ereignis" 1 "Crashschwere_1" 2 "Crashschwere_2" 3 "Crashschwere_3" 4 "Crashschwere_4" 5 "Crashschwere_5" 6 "Crashschwere_2_bis_5" 7 "Fehler" ;
VAL_ 1312 AB_Anforderung_USM 0 "keine_Anforderung" 1 "Anforderung" ;
VAL_ 1312 AB_Gurtschloss_FA 0 "nicht_verbaut" 1 "nicht_verfügbar (Fehler oder Init)" 2 "nicht_gesteckt" 3 "gesteckt" ;
VAL_ 1312 AB_Gurtschloss_BF 0 "nicht_verbaut" 1 "nicht_verfügbar (Fehler oder Init)" 2 "nicht_gesteckt" 3 "gesteckt" ;
VAL_ 1312 AB_Gurtschloss_Reihe2_FA 0 "nicht_verbaut" 1 "nicht_verfügbar (Fehler oder Init)" 2 "nicht_gesteckt" 3 "gesteckt" ;
VAL_ 1312 AB_Gurtschloss_Reihe2_MI 0 "nicht_verbaut" 1 "nicht_verfügbar (Fehler oder Init)" 2 "nicht_gesteckt" 3 "gesteckt" ;
VAL_ 1312 AB_Gurtschloss_Reihe2_BF 0 "nicht_verbaut" 1 "nicht_verfügbar (Fehler oder Init)" 2 "nicht_gesteckt" 3 "gesteckt" ;
VAL_ 1312 AB_Gurtschloss_Reihe3_FA 0 "nicht_verbaut" 1 "nicht_verfügbar (Fehler oder Init)" 2 "nicht_gesteckt" 3 "gesteckt" ;
VAL_ 1312 AB_Gurtschloss_Reihe3_MI 0 "nicht_verbaut" 1 "nicht_verfügbar (Fehler oder Init)" 2 "nicht_gesteckt" 3 "gesteckt" ;
VAL_ 1312 AB_Gurtschloss_Reihe3_BF 0 "nicht_verbaut" 1 "nicht_verfügbar (Fehler oder Init)" 2 "nicht_gesteckt" 3 "gesteckt" ;
VAL_ 1312 AB_Sitzpos_Sens_FA 0 "nicht verfügbar" 1 "Fehler" 2 "Sitz nicht vorne" 3 "Sitz vorne" ;
VAL_ 1312 AB_Sitzpos_Sens_BF 0 "nicht verfügbar" 1 "Fehler" 2 "Sitz nicht vorne" 3 "Sitz vorne" ;
VAL_ 1312 AB_Wickelklappung_Reihe2_BF 0 "nicht_verbaut" 1 "nicht_verfuegbar__Fehler_oder_Init" 2 "nicht_verriegelt" 3 "verriegelt" ;
VAL_ 1312 AB_Wickelklappung_Reihe2_FA 0 "nicht_verbaut" 1 "nicht_verfuegbar__Fehler_oder_Init" 2 "nicht_verriegelt" 3 "verriegelt" ;
VAL_ 1349 AB_Anprall_Heck 0 "kein_Anprall" 1 "Anprall_erkannt" ;
VAL_ 1349 AB_Gurtwarn_Reihe4_FA 0 "nicht_verbaut" 1 "keine_Gurtwarnung_Sitz_leer" 2 "keine_Gurtwarnung_Sitz_belegt" 3 "Gurtwarnung_Sitz_belegt" ;
VAL_ 1349 AB_Gurtwarn_Reihe4_BF 0 "nicht_verbaut" 1 "keine_Gurtwarnung_Sitz_leer" 2 "keine_Gurtwarnung_Sitz_belegt" 3 "Gurtwarnung_Sitz_belegt" ;
VAL_ 1349 AB_Gurtwarn_Reihe4_MI 0 "nicht_verbaut" 1 "keine_Gurtwarnung_Sitz_leer" 2 "keine_Gurtwarnung_Sitz_belegt" 3 "Gurtwarnung_Sitz_belegt" ;
VAL_ 1349 AB_Gurtwarn_Reihe2_FA 0 "nicht_verbaut" 1 "keine_Gurtwarnung_Sitz_leer" 2 "keine_Gurtwarnung_Sitz_belegt" 3 "Gurtwarnung_Sitz_belegt" ;
VAL_ 1349 AB_Gurtwarn_Reihe2_BF 0 "nicht_verbaut" 1 "keine_Gurtwarnung_Sitz_leer" 2 "keine_Gurtwarnung_Sitz_belegt" 3 "Gurtwarnung_Sitz_belegt" ;
VAL_ 1349 AbstWarn_MV_FAS_Fkt_Status 0 "Init" 1 "Funktion_Ist_Ein" 2 "Funktion_Ist_Aus" 3 "Fehler" ;
VAL_ 1349 WarnBrems_Charisma_Status 0 "Init" 1 "verfügbar" 2 "nicht verfügbar" 3 "asynchron durch Fahrerwunsch" ;
VAL_ 1349 WarnBrems_Charisma_FahrPr 0 "keine_Funktion" 1 "Programm_1" 2 "Programm_2" 3 "Programm_3" 4 "Programm_4" 5 "Programm_5" 6 "Programm_6" 7 "Programm_7" 8 "Programm_8" 9 "Programm_9" 10 "Programm_10" 11 "Programm_11" 12 "Programm_12" 13 "Programm_13" 14 "Programm_14" 15 "Programm_15" ;
VAL_ 1349 AB_Gurtwarn_Reihe2_MI 0 "nicht_verbaut" 1 "keine_Gurtwarnung_Sitz_leer" 2 "keine_Gurtwarnung_Sitz_belegt" 3 "Gurtwarnung_Sitz_belegt" ;
VAL_ 1349 AB_Gurtwarn_Reihe3_FA 0 "nicht_verbaut" 1 "keine_Gurtwarnung_Sitz_leer" 2 "keine_Gurtwarnung_Sitz_belegt" 3 "Gurtwarnung_Sitz_belegt" ;
VAL_ 1349 AB_Gurtwarn_Reihe3_MI 0 "nicht_verbaut" 1 "keine_Gurtwarnung_Sitz_leer" 2 "keine_Gurtwarnung_Sitz_belegt" 3 "Gurtwarnung_Sitz_belegt" ;
VAL_ 1349 AB_Gurtwarn_Reihe3_BF 0 "nicht_verbaut" 1 "keine_Gurtwarnung_Sitz_leer" 2 "keine_Gurtwarnung_Sitz_belegt" 3 "Gurtwarnung_Sitz_belegt" ;
VAL_ 1349 LGI_FAS_Fkt_Status 0 "Init" 1 "Funktion_Ist_Ein" 2 "Funktion_Ist_Aus" 3 "Fehler" ;
VAL_ 1349 PreCrash_FAS_Fkt_Status 0 "Init" 1 "Funktion_Ist_Ein" 2 "Funktion_Ist_Aus" 3 "Fehler" ;
VAL_ 1349 AB_Belegung_VF_ext 0 "nicht_verbaut" 1 "reserviert" 2 "nicht_belegt" 3 "belegt" 4 "dauerhaft_nicht_belegt" 5 "dauerhaft_belegt" 6 "Init" 7 "Fehler" ;
VAL_ 1349 AB_SBR_hinten_verbau 0 "ohne_SBR_hinten" 1 "mit_SBR_hinten" 2 "nicht_definiert" 3 "Init" ;
VAL_ 1349 AB_Belegung_VF_ext_aktiv 0 "inaktiv" 1 "aktiv" ;
VAL_ 1349 AWV_Einstellung_System_ASG 0 "deaktiviert" 1 "aktiviert" ;
VAL_ 1349 AWV_Einstellung_Warnung_ASG 0 "Aus" 1 "Setting_2" 2 "Setting_3" 3 "Setting_4" 4 "Setting_5" 5 "Ein" ;
VAL_ 1349 SC_PreSense_Modus_Warnung_NV 0 "Aus" 1 "Setting_2" 2 "Setting_3" 3 "Setting_4" 4 "Setting_5" 5 "Ein" ;
VAL_ 1349 SC_PreSense_Modus_Warnung_MV 0 "Aus" 1 "Setting_2" 2 "Setting_3" 3 "Setting_4" 4 "Setting_5" 5 "Ein" ;
VAL_ 1349 SC_PreSense_Modus_System_MV 0 "deaktiviert" 1 "aktiviert" ;
VAL_ 1349 SC_PreSense_Modus_System_NV 0 "deaktiviert" 1 "aktiviert" ;
VAL_ 1349 SC_PreSense_Modus_System_KAS 0 "deaktiviert" 1 "aktiviert" ;
VAL_ 2527679722 AB_Gurtschloss_Reihe4_FA 0 "nicht_verbaut" 1 "nicht_verfügbar (Fehler oder Init)" 2 "nicht_gesteckt" 3 "gesteckt" ;
VAL_ 2527679722 AB_Gurtschloss_Reihe4_BF 0 "nicht_verbaut" 1 "nicht_verfügbar (Fehler oder Init)" 2 "nicht_gesteckt" 3 "gesteckt" ;
VAL_ 2527679722 AB_Gurtschloss_Reihe4_MI 0 "nicht_verbaut" 1 "nicht_verfügbar (Fehler oder Init)" 2 "nicht_gesteckt" 3 "gesteckt" ;
VAL_ 2527679722 AB_wSBR_Batteriestatus 0 "Batterien_OK" 1 "mindestens_eine_Batterie_schwach" ;
VAL_ 2527679722 AB_Gurtwarn_VM 0 "keine_Warnung" 1 "Gurtwarnung_ausloesen" ;
VAL_ 2527679722 AB_Gurtschloss_MI 0 "nicht_verbaut" 1 "nicht_verfügbar (Fehler oder Init)" 2 "nicht_gesteckt" 3 "gesteckt" ;
VAL_ 1633 AAG_AVS_Fehler_02_inv 0 "Fehler" 1 "kein_Fehler" ;
VAL_ 1633 AAG_Bremsl_durch_ECD 0 "Bremslicht_ist_aus" 1 "Bremslicht_durch_ECD_aktiv" ;
VAL_ 1633 AAG_Anhaenger_abgesteckt 1 "Anhaenger_wurde_bei_KL15_aus_abgesteckt" ;
VAL_ 1633 AAG_NSL_aktiv 0 "Init" 1 "Anhaenger_Nebelschusslicht_aktiv" ;
VAL_ 1633 AAG_Anhaenger_erkannt 0 "kein_Anhaenger_erkannt" 1 "AAG_Anhaenger_erkannt" ;
VAL_ 1633 AAG_Blinker_H_aktiv 0 "Init" 1 "Anhaenger_Blinker_aktiv" ;
VAL_ 1633 AAG_Blinker_HL_def 0 "Init" 1 "Anhaenger_Blinker_links_defekt" ;
VAL_ 1633 AAG_Blinker_HR_def 0 "Init" 1 "Anhaenger_Blinker_rechts_defekt" ;
VAL_ 1633 AAG_Bremslicht_H_def 0 "Init" 1 "Anhaenger_Bremslicht_defekt" ;
VAL_ 1633 AAG_Schlusslicht_HL_def 0 "Init" 1 "Anhaenger_Schlusslicht_links_defekt" ;
VAL_ 1633 AAG_Schlusslicht_HR_def 0 "Init" 1 "Anhaenger_Schlusslicht_rechts_defekt" ;
VAL_ 1633 AAG_Bremslicht_Reku 0 "inaktiv" 1 "aktiv" ;
VAL_ 1633 AAG_AVS_Fehler_02 0 "kein_Fehler" 1 "Fehler" ;
VAL_ 1633 AAG_LED_aktiv 0 "Lampen" 1 "LED" ;
VAL_ 1633 AAG_AVS_Stati 0 "endlage_eingefahren_erreicht" 1 "endlage_ausgefahren_erreicht" 2 "ausfahren_automatik" 3 "einfahren_automatik" 4 "ausfahren_manuell" 5 "einfahren_manuell" 6 "zwischenposition" 7 "nicht_initialisiert" ;
VAL_ 616 US_Fehler_HLS 0 "Kein_Fehler" 1 "Fehler" ;
VAL_ 616 US_Fehler_HRS 0 "Kein_Fehler" 1 "Fehler" ;
VAL_ 616 US_Fehler_VLS 0 "Kein_Fehler" 1 "Fehler" ;
VAL_ 616 US_Fehler_VRS 0 "Kein_Fehler" 1 "Fehler" ;
VAL_ 616 US_Links_01_Pos_X 1023 "Init" ;
VAL_ 616 US_Links_01_Pos_Y 511 "Init" ;
VAL_ 616 US_Links_01_Valid 0 "ungueltig" 1 "gueltig" ;
VAL_ 616 US_Links_02_Pos_X 1023 "Init" ;
VAL_ 616 US_Links_02_Pos_Y 511 "Init" ;
VAL_ 616 US_Links_02_Valid 0 "ungueltig" 1 "gueltig" ;
VAL_ 616 US_Rechts_01_Pos_X 1023 "Init" ;
VAL_ 616 US_Rechts_01_Pos_Y 511 "Init" ;
VAL_ 616 US_Rechts_01_Valid 0 "ungueltig" 1 "gueltig" ;
VAL_ 616 US_Rechts_02_Pos_X 1023 "Init" ;
VAL_ 616 US_Rechts_02_Pos_Y 511 "Init" ;
VAL_ 616 US_Rechts_02_Valid 0 "ungueltig" 1 "gueltig" ;
VAL_ 616 US_QAbstand_HLS 511 "Init" ;
VAL_ 616 US_Nichtverfuegbarkeit_HLS 0 "verfuegbar" 1 "nicht_verfuegbar" ;
VAL_ 616 US_QAbstand_HRS 511 "Init" ;
VAL_ 616 US_Nichtverfuegbarkeit_HRS 0 "verfuegbar" 1 "nicht_verfuegbar" ;
VAL_ 616 US_QAbstand_VLS 511 "Init" ;
VAL_ 616 US_Nichtverfuegbarkeit_VLS 0 "verfuegbar" 1 "nicht_verfuegbar" ;
VAL_ 616 US_QAbstand_VRS 511 "Init" ;
VAL_ 616 US_Nichtverfuegbarkeit_VRS 0 "verfuegbar" 1 "nicht_verfuegbar" ;
VAL_ 896 US_Sende_Modus 0 "keine_fuer_das_ACC_SG_relevanten_Abstandswerte_werden_gesendet" 1 "4K_ext_range__10_Signalwege_verfuegbar__4m" 2 "4K_norm_range__10_Signalwege_verfuegbar__2m" 3 "6K_ext_range__16_Signalwege_verfuegbar__4m" 4 "6K_norm_range__16_Signalwege_verfuegbar__2m" 5 "2K_ext_range__2_Signalwege_verfuegbar__4m" 6 "Modeumschaltung__ext_>_norm__oder__norm_>_ext" 7 "Blindheitspruefung" 8 "4K_ext_range__12_Signalwege_verfuegbar_4m" 9 "4K_norm_range__12_Signalwege_verfuegbar_2m" 10 "6K_ext_range__18_Signalwege_verfuegbar_4m" 11 "6K_norm_range__18_Signalwege_verfuegbar_2m" 15 "Fehler" ;
VAL_ 896 US_relevanter_Fehler 0 "kein_relevanter_Fehler" 1 "relevanter_Fehler" ;
VAL_ 896 US_relevante_Nichtverfuegbarkeit 0 "verfuegbar" 1 "nicht_verfuegbar" ;
VAL_ 896 US_Freisicht_nio 0 "Freisicht_iO" 1 "Freisicht_niO" ;
VAL_ 896 US_blindness_detected 0 "blindness_nicht_detektiert" 1 "blindness_detektiert" ;
VAL_ 896 US_Sende_Modus_hinten 0 "keine_fuer_das_ACC_SG_relevanten_Abstandswerte_werden_gesendet" 5 "2K_ext_range__2_Signalwege_verfuegbar__4m" 6 "Modeumschaltung__ext_>_norm__oder__norm_>_ext" 7 "Blindheitspruefung" 15 "Fehler" ;
VAL_ 896 US_Freie_Weglaenge_Heck_Typ 0 "Maximaler_Messbereich" 1 "Hindernis_detektiert" ;
VAL_ 896 US_Freie_Weglaenge_Heck 510 "Init" 511 "Fehler" ;
VAL_ 896 APS_Master_Sendestatus 0 "Langsame_Zykluszeit_aktiv" 1 "Schnelle_Zykluszeit_aktiv" ;
VAL_ 896 US_Freie_Weglaenge_Front_Typ 0 "Maximaler_Messbereich" 1 "Hindernis_detektiert" ;
VAL_ 896 US_Freie_Weglaenge_Front 509 "freie_Weglaenge_groesser_5m" 510 "Init" 511 "Fehler" ;
VAL_ 345 ARA_Anf_Meldungen 0 "keine_Meldung" 1 "trailer_assist_temp_notAvailable" 2 "pressBrake_toReleaseParkingBrak" 3 "trailDetNotFinishedMoveStraight" 4 "trailDetecNotFinishedReducedFctn" 5 "parkAsNotFuncRackOnTrailTowHitch" 6 "trailAsNotAvail_RackOnTowHitch" 7 "aborted_trailer_is_not_detected" 8 "standstill_to_act_trailerAssist" 9 "duringAutomSteering_actNotAvail" 10 "standstill_time_not_long_enough" 11 "press_PLA_BTN_toActTrailerAssist" 12 "Temporary_not_available_ESP_off" 13 "traject_forward_path_suggestion" 14 "traject_backing_up_is_possible" 15 "traject_towing_fwd_canB_finished" 16 "trailerAsNotAvail_acivateMirrors" 17 "mirrors_are_closing" 18 "trailerAsNotAvailable_close_door" 19 "trailerAs_aborted_driverDoorOpen" 20 "trailerAsNotAvailable_closeTrunk" 21 "aborted_trunk_door_is_open" 22 "trailerAsNotAvail_cleanRearCam" 23 "aborted_clean_rear_camera" 24 "trailerAs_check_trailerConnector" 25 "trajectory_finished" 26 "trailerAs_changeIntoReverseGear" 128 "steeringAsAct_brakeByYourself" 129 "trailer_assist_is_finished" 130 "SteerIntervenDriverEmergBrakeAct" 131 "stabilityCtrl_emergencyBrake_act" 132 "maxAngleExeeded_EmergBrakeAct" 133 "sysErrorEmergBrakeContactService" 134 "system_error_contact_service" 135 "aborted_trailNotDetec_emergBrake" 136 "aborted_trailerNotDetecRsmeSteer" 137 "system_error_braking_byYourself" 138 "trajectFwdSteerAsActBrakeYourslf" 139 "SteeringAs_notAct_resumeSteering" 140 "trailerAs_aborted_resumeSteering" ;
VAL_ 345 ARA_Knickwinkel_Konfidenz 126 "Init" 127 "Fehler" ;
VAL_ 345 ARA_Modus 0 "Knickwinkelmodus" 1 "Trajektorienmodus" ;
VAL_ 345 ARA_Sensor_Aktivierung 0 "Knickwinkelsensor_deaktivieren" 1 "Knickwinkelsensor_aktivieren" ;
VAL_ 345 ARA_Knickwinkel_Komfort 62 "Init" 63 "Fehler" ;
VAL_ 345 ARA_Status 0 "ARA_Status_inaktiv" 1 "ARA_Status_init" 2 "Fehler" 3 "ARA_Status_Start" 4 "ARA_Status_aktiv" 6 "ARA_Status_Regelung_aktiv" 8 "ARA_Status_betriebsbereit" 9 "ARA_Status_Klemmtraeger_erkannt" 10 "ARA_Status_Abbruch" 11 "ARA_Status_nicht_betriebsbereit" ;
VAL_ 345 ARA_Knickwinkel_Max 126 "Init" 127 "Fehler" ;
VAL_ 345 ARA_Knickwinkel_Soll 254 "Init" 255 "Fehler" ;
VAL_ 345 ARA_Knickwinkel_Ist 254 "Init" 255 "Fehler" ;
VAL_ 2527679661 WBA_Warnblinken 0 "kein_Blinken" 1 "Warnblinken" 2 "Warnblinken_Taster" ;
VAL_ 2527679661 AWV_KA_Konfiguration 0 "Ausgeschaltet" 1 "Eingeschaltet" ;
VAL_ 2527679661 AWV_Warnung 0 "keine_Anzeige" 1 "latente_Vorwarnung" 2 "Vorwarnung" 3 "AWU_ohne_Ton_oder_Akutwarnung" 4 "Eingriff" 5 "Fahreruebernahmeaufforderung" 6 "AWU_mit_Ton" 7 "Querinfo_2" ;
VAL_ 2527679661 AWV_Texte 0 "keine_Anzeige" 1 "Systemstoerung" 2 "keine_Sensorsicht" 3 "Initialisierung_gelb" 4 "System_aus" 5 "Initialisierung" 6 "ESC_aus" 7 "zurzeit_eingeschraenkt" ;
VAL_ 2527679661 AWV_Warnlevel 0 "keine_Gefaehrdung" 63 "max_Gefaehrdung" ;
VAL_ 2527679661 AWV_Einstellung_System_FSG 0 "deaktiviert" 1 "aktiviert" ;
VAL_ 2527679661 AWV_Einstellung_Warnung_FSG 0 "Aus" 1 "Setting_2" 2 "Setting_3" 3 "Setting_4" 4 "Setting_5" 5 "Ein" ;
VAL_ 2527679661 AWV_Status_Anzeige 0 "Init" 1 "verfuegbar" 2 "nicht_verfuegbar" ;
VAL_ 2527679661 AWV_LED_Leiste 0 "keine_Anzeige" 1 "Stufe_1_glimmen" 2 "Stufe_2_leuchten" 3 "nicht_definiert" ;
VAL_ 2527679661 AWV_Priowarnung 0 "HCA_Warnung_nicht_unterdruecken" 1 "HCA_Warnung_unterdruecken" ;
VAL_ 2527679661 AWV_AW_Abstand 509 "Freifahrt" 510 "nicht_definiert" 511 "Keine_Anzeige" ;
VAL_ 2527679661 AWV_AW_Zeitluecke 0 "keine_Anzeige" 1 "Zeitluecke_1" 2 "Zeitluecke_2" 3 "Zeitluecke_3" ;
VAL_ 2527679661 AWV_AW_Texte 0 "Keine_Anzeige" 1 "Systemstoerung" 2 "keine_Sensorsicht" 3 "zurzeit_eingeschraenkt" ;
VAL_ 2527679661 AWV_AW_Texte_Zusatzanzeige 0 "keine_Anzeige" 1 "Abstandsanzeige" 2 "AW_Warnschwelle_1" 3 "AW_Warnschwelle_2" 4 "AW_Warnschwelle_3" 5 "AW_Warnung_1" 6 "AW_Warnung_2" 7 "AW_Warnung_3" ;
VAL_ 2527679661 AWV_KA_ObjektFront 0 "kein_Hindernis" 1 "Hindernis_erkannt" ;
VAL_ 2527679661 AWV_Warnung_Richtung 0 "keine_Richtung" 1 "Links" 2 "Mitte" 3 "Rechts" 4 "Links_und_Rechts" ;
VAL_ 2527679661 AWV_Kamera_Objekt_ID 0 "Kein_Kameraobjekt" ;
VAL_ 219 PCF_Freigabe 0 "keine_Freigabe_PreCrashFront" 1 "Freigabe_PreCrashFront" ;
VAL_ 219 SDF_PSF_Objektstatus 0 "kein_relevantes_Obj" 1 "relevantes_Obj_vorausfahrend" 2 "relevantes_Obj_stehend" 3 "relevantes_Obj_angehalten" 4 "relevantes_Obj_entgegenkommend" 5 "relevantes_Obj_querend" 7 "Fehler" ;
VAL_ 219 SDF_PSF_CU_Status 0 "Kollision_vermeidbar" 1 "Kollision_unvermeidbar" ;
VAL_ 219 SDF_PSF_CW 126 "Init" 127 "Fehler" ;
VAL_ 219 SDF_PSF_Fahrer_aktiv 0 "Fahrer_nicht_aktiv" 1 "Fahrer_aktiv" ;
VAL_ 219 SDF_PSF_Guete 0 "Modellguete_niO_keine_Plausi" 1 "Modellguete_niO_plausibilisiert" 2 "Modellguete_iO_keine_Plausi" 3 "Modellguete_iO_plausibilisiert" ;
VAL_ 219 SDF_PSF_Kollisionsueberdeckung 0 "Keine_Ueberdeckung" 29 "Ueberdeckung_groesser_Maximalwert" 30 "Init" 31 "Fehler" ;
VAL_ 219 SDF_PSF_Time_To_Collision 254 "Init" 255 "Fehler" ;
VAL_ 219 SDF_PSF_v_rel 0 "Objektstatus_0" 254 "Init" 255 "Fehler" ;
VAL_ 219 AWV_Eingriff_Sendeart 0 "langsamer_Zyklus" 1 "schneller_Zyklus" ;
VAL_ 219 AWV_Verz_Freigabe 0 "Verzoegerung_nicht_freigeben" 1 "Verzoegerung_freigeben" ;
VAL_ 219 AWV_Verz_Anf 1023 "keine_Anforderung" ;
VAL_ 219 AWV_Anf_Prefill 0 "Keine_Anforderung" 1 "Prefill_aktivieren" ;
VAL_ 219 AWV_Ruckprofil 0 "kein_Ruck" 1 "schwacher_Ruck" 2 "mittlerer_Ruck" 3 "starker_Ruck" ;
VAL_ 219 AWV_Time_to_collision 253 "Wert_groesser_max" 254 "Unbekannt" 255 "Init" ;
VAL_ 219 AWV_HBA_Param 0 "Defaultparametersatz" 1 "leicht_erhoeht" 2 "erhoeht" 3 "hoechst" ;
VAL_ 219 AWV_Verz_Anf_ASIL 0 "QM" 1 "A" 2 "B" 3 "C" ;
VAL_ 219 AWV_Time_to_brake 125 "Wert_groesser_max" 126 "unbekannt" 127 "Init" ;
VAL_ 219 AWV_Zielobjekttyp 0 "Unbekannt" 1 "Fussgaenger" 2 "Zweirad" 3 "PKW" 4 "LKW" 5 "reserviert" 6 "reserviert" 7 "reserviert" 8 "reserviert" 9 "reserviert" 10 "reserviert" 11 "reserviert" 12 "reserviert" 13 "reserviert" 14 "kein_relevantes_Obj" 15 "init" ;
VAL_ 219 AWV_QFK_KruemmSoll_VZ 0 "positiv" 1 "negativ" ;
VAL_ 219 AWV_QFK_AnfStat 1 "Init" 2 "Bereit" 4 "Eingriff" ;
VAL_ 219 AWV_Fahrerbremswunsch_erf 0 "erforderlich" 1 "nicht_erforderlich" ;
VAL_ 219 AWV_Timestamp_TTC 8191 "Init" ;
VAL_ 219 AWV_QFK_KrSoll_VZ 0 "positiv" 1 "negativ" ;
VAL_ 219 AWV_QFK_KrSoll 65535 "Init" ;
VAL_ 219 AWV_Status_AWU 0 "Off" 1 "On_but_not_intervening" 2 "On_actively_intervening" 3 "Faulted" 4 "Reserved04" 5 "Reserved05" 6 "Reserved06" 7 "Reserved07" 8 "Reserved08" 9 "Reserved09" 10 "Reserved10" 11 "Reserved11" 12 "Reserved12" 13 "Reserved13" 14 "Invalid_data" 15 "Data_not_available" ;
VAL_ 870 BM_ZV_auf 0 "inaktiv" 1 "aktiv" ;
VAL_ 870 BM_ZV_zu 0 "inaktiv" 1 "aktiv" ;
VAL_ 870 BM_DWA_ein 0 "inaktiv" 1 "aktiv" ;
VAL_ 870 BM_DWA_Alarm 0 "inaktiv" 1 "aktiv" ;
VAL_ 870 BM_Crash 0 "inaktiv" 1 "aktiv" ;
VAL_ 870 BM_Panik 0 "inaktiv" 1 "aktiv" ;
VAL_ 870 BM_Not_Bremsung 0 "kein_blinken" 1 "Notbremswarnblinken_aktiv" ;
VAL_ 870 BM_GDO 0 "inaktiv" 1 "aktiv" ;
VAL_ 870 BM_Warnblinken 0 "inaktiv" 1 "aktiv" ;
VAL_ 870 BM_Taxi_Notalarm 0 "inaktiv" 1 "aktiv" ;
VAL_ 870 BM_Telematik 0 "inaktiv" 1 "aktiv" ;
VAL_ 870 BM_links 0 "inaktiv" 1 "aktiv" ;
VAL_ 870 BM_rechts 0 "inaktiv" 1 "aktiv" ;
VAL_ 870 Blinken_li_Fzg_Takt 0 "Blinker_links_ausgeschaltet" 1 "Blinker_links_eingeschaltet" ;
VAL_ 870 Blinken_re_Fzg_Takt 0 "Blinker_rechts_ausgeschaltet" 1 "Blinker_rechts_eingeschaltet" ;
VAL_ 870 Blinken_li_Kombi_Takt 0 "Blinkerkontrolllampe_links_ausgeschaltet" 1 "Blinkerkontrolllampe_links_eingeschaltet" ;
VAL_ 870 Blinken_re_Kombi_Takt 0 "Blinkerkontrolllampe_rechts_ausgeschaltet" 1 "Blinkerkontrolllampe_rechts_eingeschaltet" ;
VAL_ 870 BM_NBA_n_codiert_n_aktiv 0 "codiert_AND_kein_Fehler" 1 "nicht_codiert_OR_Fehler_erkannt" ;
VAL_ 870 BM_NBA_Status 0 "NBA_nicht_aktiv" 1 "BRL_Dunkelphase" 3 "BRL_Hellphase" ;
VAL_ 870 BM_WBT_Beleuchtung 0 "inaktiv" 1 "aktiv" ;
VAL_ 870 BM_HD_Oeffnung_angelernt 0 "keine_Quittierung" 1 "Quittierung" ;
VAL_ 870 BM_Autobahn 0 "inaktiv" 1 "aktiv" ;
VAL_ 870 BM_Rollenmodus_Blinken 0 "inaktiv" 1 "aktiv" ;
VAL_ 870 BM_Recas 0 "kein_blinken" 1 "Recasblinken_aktiv" ;
VAL_ 870 BM_Wischblinken 0 "inaktiv" 1 "aktiv" ;
VAL_ 870 BM_Telematik_Abbruchgrund 0 "Init" 1 "speed_out_of_range" 2 "defect" 3 "clamp_s_on" 4 "clamp_15_on" 5 "door_open" 6 "engine_hood_open" 7 "trunk_open" 8 "convertible_top_not_locked" 9 "horn_activated_by_user" 10 "Higher_Prioritiy_Function_active" 11 "Central_Lock_status_changed" 12 "Request_Dropped_by_Requester" 13 "Service_Duration_Expired" 14 "not_possible_due_to_coding" 15 "no_reason_or_unknown_timeout" ;
VAL_ 870 BM_PiloPa 0 "PiloPa_Blinkerquittierung_inaktiv" 1 "PiloPa_Blinkerquittierung_aktiv" ;
VAL_ 870 SAL_TA_Blinken_Status 0 "init" 1 "nicht_bereit" 2 "bereit" 3 "aktiv_links" 4 "aktiv_rechts" ;
VAL_ 870 SAL_RHP_Blinken_Status 0 "init" 1 "nicht_bereit" 2 "bereit" 3 "aktiv_links" 4 "aktiv_rechts" ;
VAL_ 870 SAL_RHP_Warnblinken 0 "inaktiv" 1 "aktiv" ;
VAL_ 870 DWA_Alarmquelle 0 "kein_Ausloesegrund" 1 "Tuerkontakt_Fahrertuer" 2 "Tuerkontakt_Beifahrertuer" 3 "Tuerkontakt_hinten_links" 4 "Tuerkontakt_hinten_rechts" 5 "Motorhaubenkontakt_vorne" 6 "Kofferraum_hinten" 7 "Masseschleife_der_Heckscheibe" 8 "Innenraumueberwachung" 9 "Alarm_durch_Noteinstieg" 10 "Sounder" 11 "Neigungssensor" 12 "TSG_FT_am_CAN_Bus" 13 "TSG_BT_am_CAN_Bus" 14 "TSG_HFS_am_CAN_Bus" 15 "TSG_HBFS_am_CAN_Bus" 16 "Klemme_15" 17 "Klemme_15sig" 18 "frei" 19 "Anhaengerueberwachung" 20 "Scheinwerferueberwachung_links" 21 "Scheinwerferueberwachung_rechts" 22 "Handschuhkasten" 23 "Verdeckueberwachung" 24 "OBD_Alarm" 25 "Power_on_Reset" 30 "Init" 31 "Fehler" ;
